VERSION "created by canmatrix"

NS_ :

BS_:

BU_: TCM iBooster HCU CIM SCM Right_Hand_Control Left_Hand_Control GPS VCM IC_2 XM GMRS Radio_CANtool Diagnostic_Tool_Digital_Wrench Information_System_Controller_1 STEERING_CONTROLLER VEHICLE_SECURITY RADIO_Hub ABS Battery_Management_Cntrl_2 Battery_Management_Cntrl_1 Auxiliary_Power_Unit_2 Auxiliary_Power_Unit_1 Electric_Propulsion_Cntrl_Unit_4 Electric_Propulsion_Cntrl_Unit_3 Electric_Propulsion_Cntrl_Unit_2 Electric_Propulsion_Cntrl_Unit_1 ECM IC

BO_ 2348941054 TC1_256: 8 Vector__XXX
 SG_ AutoNeutralReq_7695 : 48|2@1+ (1,0) [0.0|3.0] "" Vector__XXX
 SG_ TransMode8_4249 : 62|2@1+ (1,0) [0.0|3.0] "" Vector__XXX
 SG_ TransMode7_4248 : 60|2@1+ (1,0) [0.0|3.0] "" Vector__XXX
 SG_ TransMode6_4247 : 58|2@1+ (1,0) [0.0|3.0] "" Vector__XXX
 SG_ TransMode5_4246 : 56|2@1+ (1,0) [0.0|3.0] "" Vector__XXX
 SG_ TrnsShftSelectorDMS_2985 : 54|2@1+ (1,0) [0.0|3.0] "" Vector__XXX
 SG_ TransRequestedLaunchGear_4255 : 50|4@1+ (1,0) [0.0|15.0] "" Vector__XXX
 SG_ TransMode4_1855 : 46|2@1+ (1,0) [0.0|3.0] "" Vector__XXX
 SG_ TransMode3_1854 : 44|2@1+ (1,0) [0.0|3.0] "" Vector__XXX
 SG_ TransMode2_1853 : 42|2@1+ (1,0) [0.0|3.0] "" Vector__XXX
 SG_ TransMode1_1852 : 40|2@1+ (1,0) [0.0|3.0] "" Vector__XXX
 SG_ TransLoadReductionInhibitRq_5762 : 38|2@1+ (1,0) [0.0|3.0] "" Vector__XXX
 SG_ DisengDiffLockRqCentralRear_691 : 36|2@1+ (1,0) [0.0|3.0] "" Vector__XXX
 SG_ DisengDiffLockRqCentralFront_690 : 34|2@1+ (1,0) [0.0|3.0] "" Vector__XXX
 SG_ DisengageDiffLockRqCentral_689 : 32|2@1+ (1,0) [0.0|3.0] "" Vector__XXX
 SG_ DisengageDiffLockRqRearAxle2_688 : 30|2@1+ (1,0) [0.0|3.0] "" Vector__XXX
 SG_ DisengageDiffLockRqRearAxle1_687 : 28|2@1+ (1,0) [0.0|3.0] "" Vector__XXX
 SG_ DisengDiffLockRqFrontAxle2_686 : 26|2@1+ (1,0) [0.0|3.0] "" Vector__XXX
 SG_ DisengDiffLockRqFrontAxle1_685 : 24|2@1+ (1,0) [0.0|3.0] "" Vector__XXX
 SG_ TransRequestedGear_525 : 16|8@1+ (1,-125) [-64.0|64.0] "" Vector__XXX
 SG_ RequestedPercentClutchSlip_684 : 8|8@1+ (0.4,0) [0.0|100.0] "%" Vector__XXX
 SG_ TransRevGearShiftInhibitRq_4242 : 6|2@1+ (1,0) [0.0|3.0] "" Vector__XXX
 SG_ DisengageDrivelineRq_683 : 4|2@1+ (1,0) [0.0|3.0] "" Vector__XXX
 SG_ TrnsTrqeConvLockupDisableRq_682 : 2|2@1+ (1,0) [0.0|3.0] "" Vector__XXX
 SG_ TransGearShiftInhibitRq_681 : 0|2@1+ (1,0) [0.0|3.0] "" Vector__XXX

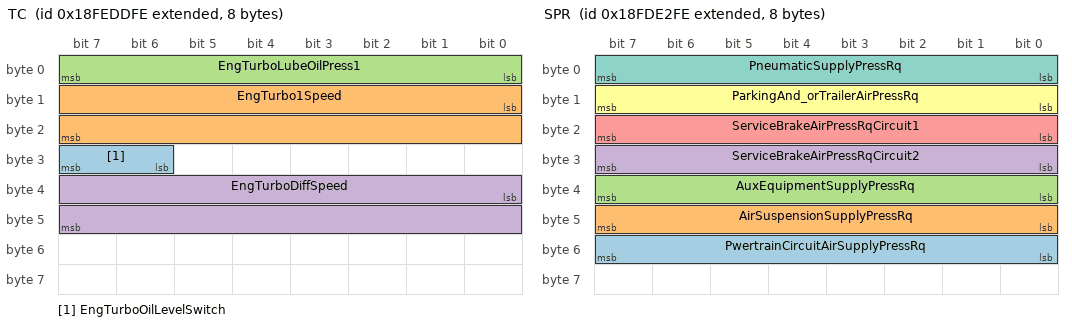
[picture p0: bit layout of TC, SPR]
BO_ 2566839806 TC: 8 Vector__XXX
 SG_ EngTurboOilLevelSwitch : 30|2@1+ (1,0) [0.0|3.0] "" Vector__XXX
 SG_ EngTurbo1Speed : 8|16@1+ (4,0) [0.0|257020.0] "rpm" Vector__XXX
 SG_ EngTurboLubeOilPress1 : 0|8@1+ (4,0) [0.0|1000.0] "kPa" Vector__XXX
 SG_ EngTurboDiffSpeed : 32|16@1+ (4,0) [0.0|257020.0] "rpm" Vector__XXX

BO_ 2633911806 TAVG: 8 Vector__XXX
 SG_ EngTotalAverageFuelEconomy : 16|16@1+ (0.00195312,0) [0.0|125.498046875] "km/L" Vector__XXX
 SG_ EngTotalAverageFuelRate : 0|16@1+ (0.05,0) [0.0|3212.75] "L/h" Vector__XXX

BO_ 2566775550 SPR: 8 Vector__XXX
 SG_ PwertrainCircuitAirSupplyPressRq : 48|8@1+ (8,0) [0.0|2000.0] "kPa" Vector__XXX
 SG_ AirSuspensionSupplyPressRq : 40|8@1+ (8,0) [0.0|2000.0] "kPa" Vector__XXX
 SG_ AuxEquipmentSupplyPressRq : 32|8@1+ (8,0) [0.0|2000.0] "kPa" Vector__XXX
 SG_ ServiceBrakeAirPressRqCircuit2 : 24|8@1+ (8,0) [0.0|2000.0] "kPa" Vector__XXX
 SG_ ServiceBrakeAirPressRqCircuit1 : 16|8@1+ (8,0) [0.0|2000.0] "kPa" Vector__XXX
 SG_ ParkingAnd_orTrailerAirPressRq : 8|8@1+ (8,0) [0.0|2000.0] "kPa" Vector__XXX
 SG_ PneumaticSupplyPressRq : 0|8@1+ (8,0) [0.0|2000.0] "kPa" Vector__XXX

BO_ 2566819838 SP2: 8 Vector__XXX
 SG_ EngExtlShutdownAirSupplyPress : 0|16@1+ (0.5,0) [0.0|32127.5] "kPa" Vector__XXX

BO_ 2566839038 SOFT: 8 Vector__XXX
 SG_ NmbrOfSftwreIdentificationFields : 0|8@1+ (1,0) [0.0|125.0] "steps" Vector__XXX
 SG_ SoftwareIdentification : 8|8@1+ (1,0) [0.0|255.0] "" Vector__XXX

BO_ 2566841598 SHUTDN: 8 Vector__XXX
 SG_ ClntLvlEngPrtctionShutdownStatus : 60|2@1+ (1,0) [0.0|3.0] "" Vector__XXX
 SG_ PTOShutdownHasShutdownEng : 58|2@1+ (1,0) [0.0|3.0] "" Vector__XXX
 SG_ EngAirShutoffStatus : 56|2@1+ (1,0) [0.0|3.0] "" Vector__XXX
 SG_ EngOverspeedTest : 54|2@1+ (1,0) [0.0|3.0] "" Vector__XXX
 SG_ EngAirShutoffCmdStatus : 52|2@1+ (1,0) [0.0|3.0] "" Vector__XXX
 SG_ EngAlarmOutputCmdStatus : 50|2@1+ (1,0) [0.0|3.0] "" Vector__XXX
 SG_ EngAlarmAcknowledge : 48|2@1+ (1,0) [0.0|3.0] "" Vector__XXX
 SG_ EngProtectionSystemConfig : 46|2@1+ (1,0) [0.0|3.0] "" Vector__XXX
 SG_ EngProtectionSystemTimerState : 38|2@1+ (1,0) [0.0|3.0] "" Vector__XXX
 SG_ EngProtectionSystemTimerOverride : 36|2@1+ (1,0) [0.0|3.0] "" Vector__XXX
 SG_ EngPrtctnSystmApprachingShutdown : 34|2@1+ (1,0) [0.0|3.0] "" Vector__XXX
 SG_ EngPrtectionSystemHasShutdownEng : 32|2@1+ (1,0) [0.0|3.0] "" Vector__XXX
 SG_ EngWaitToStartLamp : 24|2@1+ (1,0) [0.0|3.0] "" Vector__XXX
 SG_ RefrigerantHighPressSwitch : 20|2@1+ (1,0) [0.0|3.0] "" Vector__XXX
 SG_ RefrigerantLowPressSwitch : 18|2@1+ (1,0) [0.0|3.0] "" Vector__XXX
 SG_ A_CHighPressFanSwitch : 16|2@1+ (1,0) [0.0|3.0] "" Vector__XXX
 SG_ EngIdleShutdownTimerFunction : 14|2@1+ (1,0) [0.0|3.0] "" Vector__XXX
 SG_ EngIdleShutdownTimerState : 6|2@1+ (1,0) [0.0|3.0] "" Vector__XXX
 SG_ EngIdleShutdownTimerOverride : 4|2@1+ (1,0) [0.0|3.0] "" Vector__XXX
 SG_ EngIdleShutdownDriverAlertMode : 2|2@1+ (1,0) [0.0|3.0] "" Vector__XXX
 SG_ EngIdleShutdownHasShutdownEng : 0|2@1+ (1,0) [0.0|3.0] "" Vector__XXX

BO_ 2566786302 WSMEM: 8 Vector__XXX
 SG_ VehicleSystem5 m5  : 49|7@1+ (1,0) [0.0|127.0] "" Vector__XXX
 SG_ VehicleSystem4 m4  : 49|7@1+ (1,0) [0.0|127.0] "" Vector__XXX
 SG_ VehicleSystem3 m3  : 49|7@1+ (1,0) [0.0|127.0] "" Vector__XXX
 SG_ VehicleSystem2 m2  : 49|7@1+ (1,0) [0.0|127.0] "" Vector__XXX
 SG_ VehicleSystem1 m1  : 49|7@1+ (1,0) [0.0|127.0] "" Vector__XXX
 SG_ ArbitraryAddressCapable : 63|1@1+ (1,0) [0.0|1.0] "" Vector__XXX
 SG_ IndustryGroup M  : 60|3@1+ (1,0) [0.0|7.0] "" Vector__XXX
 SG_ VehicleSystemInstance : 56|4@1+ (1,0) [0.0|15.0] "" Vector__XXX
 SG_ VehicleSystem m0  : 49|7@1+ (1,0) [0.0|127.0] "" Vector__XXX
 SG_ ECUInstance : 32|3@1+ (1,0) [0.0|7.0] "" Vector__XXX
 SG_ FunctionInstance : 35|5@1+ (1,0) [0.0|31.0] "" Vector__XXX
 SG_ Function : 40|8@1+ (1,0) [0.0|255.0] "" Vector__XXX
 SG_ ManufacturerCode : 21|11@1+ (1,0) [0.0|2047.0] "" Vector__XXX
 SG_ IdentityNumber : 0|21@1+ (1,0) [0.0|2097152.0] "" Vector__XXX

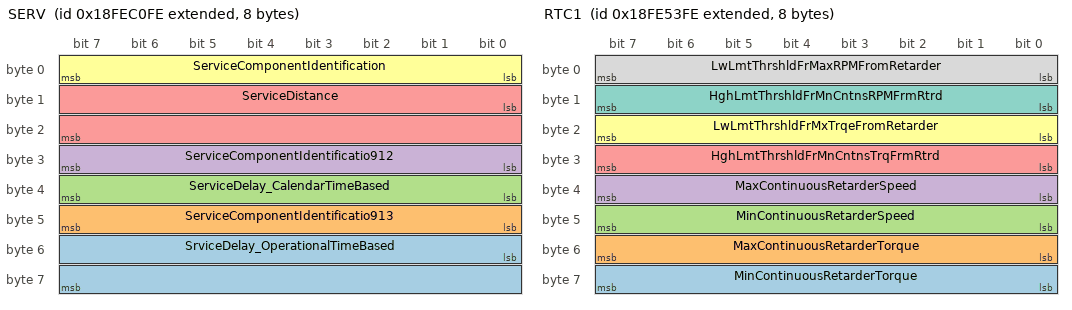
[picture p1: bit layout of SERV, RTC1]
BO_ 2566832382 SERV: 8 Vector__XXX
 SG_ SrviceDelay_OperationalTimeBased : 48|16@1+ (1,-32127) [-32127.0|32128.0] "h" Vector__XXX
 SG_ ServiceComponentIdentificatio913 : 40|8@1+ (1,0) [0.0|250.0] "ID" Vector__XXX
 SG_ ServiceDelay_CalendarTimeBased : 32|8@1+ (1,-125) [-125.0|125.0] "weeks" Vector__XXX
 SG_ ServiceComponentIdentificatio912 : 24|8@1+ (1,0) [0.0|250.0] "ID" Vector__XXX
 SG_ ServiceDistance : 8|16@1+ (5,-160635) [-160635.0|160640.0] "km" Vector__XXX
 SG_ ServiceComponentIdentification : 0|8@1+ (1,0) [0.0|250.0] "ID" Vector__XXX

BO_ 2633928446 S2: 8 Vector__XXX
 SG_ TimeSinceLastService : 8|16@1+ (1,-32127) [-32127.0|32128.0] "h" Vector__XXX
 SG_ ServiceComponentIdentification : 0|8@1+ (1,0) [0.0|250.0] "ID" Vector__XXX

BO_ 2566804478 RTC1: 8 Vector__XXX
 SG_ MinContinuousRetarderTorque : 56|8@1+ (1,-125) [-125.0|125.0] "%" Vector__XXX
 SG_ MaxContinuousRetarderTorque : 48|8@1+ (1,-125) [-125.0|125.0] "%" Vector__XXX
 SG_ MinContinuousRetarderSpeed : 40|8@1+ (32,0) [0.0|8000.0] "rpm" Vector__XXX
 SG_ MaxContinuousRetarderSpeed : 32|8@1+ (32,0) [0.0|8000.0] "rpm" Vector__XXX
 SG_ HghLmtThrshldFrMnCntnsTrqFrmRtrd : 24|8@1+ (1,-125) [-125.0|125.0] "%" Vector__XXX
 SG_ LwLmtThrshldFrMxTrqeFromRetarder : 16|8@1+ (1,-125) [-125.0|125.0] "%" Vector__XXX
 SG_ HghLmtThrshldFrMnCntnsRPMFrmRtrd : 8|8@1+ (32,0) [0.0|8000.0] "rpm" Vector__XXX
 SG_ LwLmtThrshldFrMaxRPMFromRetarder : 0|8@1+ (32,0) [0.0|8000.0] "rpm" Vector__XXX

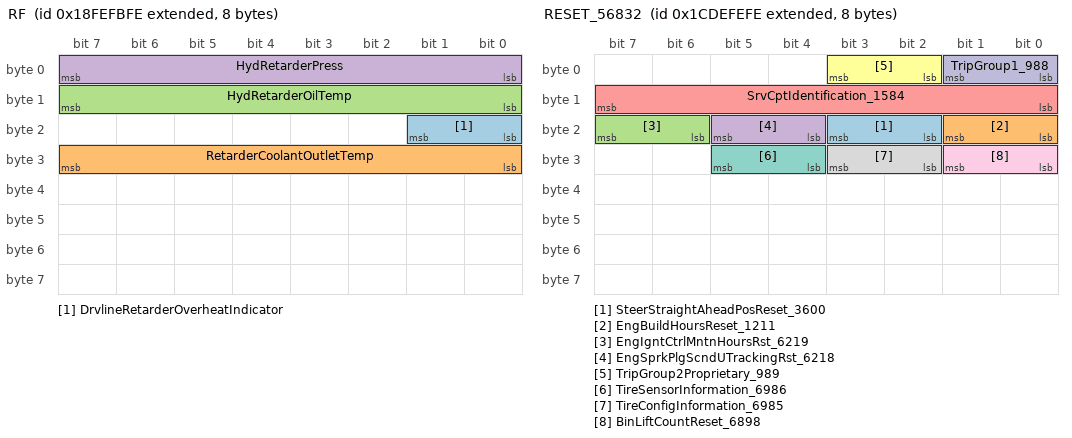
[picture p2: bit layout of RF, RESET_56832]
BO_ 2566847486 RF: 8 Vector__XXX
 SG_ DrvlineRetarderOverheatIndicator : 16|2@1+ (1,0) [0.0|3.0] "" Vector__XXX
 SG_ RetarderCoolantOutletTemp : 24|8@1+ (1,-40) [-40.0|210.0] "°C" Vector__XXX
 SG_ HydRetarderOilTemp : 8|8@1+ (1,-40) [-40.0|210.0] "°C" Vector__XXX
 SG_ HydRetarderPress : 0|8@1+ (16,0) [0.0|4000.0] "kPa" Vector__XXX

BO_ 2631859966 RESET_56832: 8 Vector__XXX
 SG_ SteerStraightAheadPosReset_3600 : 18|2@1+ (1,0) [0.0|3.0] "" Vector__XXX
 SG_ EngBuildHoursReset_1211 : 16|2@1+ (1,0) [0.0|3.0] "" Vector__XXX
 SG_ EngIgntCtrlMntnHoursRst_6219 : 22|2@1+ (1,0) [0.0|3.0] "" Vector__XXX
 SG_ EngSprkPlgScndUTrackingRst_6218 : 20|2@1+ (1,0) [0.0|3.0] "" Vector__XXX
 SG_ SrvCptIdentification_1584 : 8|8@1+ (1,0) [0.0|250.0] "ID" Vector__XXX
 SG_ TripGroup2Proprietary_989 : 2|2@1+ (1,0) [0.0|3.0] "" Vector__XXX
 SG_ TireSensorInformation_6986 : 28|2@1+ (1,0) [0.0|3.0] "" Vector__XXX
 SG_ TireConfigInformation_6985 : 26|2@1+ (1,0) [0.0|3.0] "" Vector__XXX
 SG_ BinLiftCountReset_6898 : 24|2@1+ (1,0) [0.0|3.0] "" Vector__XXX
 SG_ TripGroup1_988 : 0|2@1+ (1,0) [0.0|3.0] "" Vector__XXX

BO_ 2566840830 RC: 19 Vector__XXX
 SG_ PercentTorqueAtPeakTorquePoint5 : 144|8@1+ (1,-125) [-125.0|0.0] "%" Vector__XXX
 SG_ ReferenceRetarderTorque : 128|16@1+ (1,0) [0.0|64255.0] "Nm" Vector__XXX
 SG_ RetarderSpeedAtPeakTorquePoint5 : 112|16@1+ (0.125,0) [0.0|8031.875] "rpm" Vector__XXX
 SG_ PercentTorqueAtPoint4 : 104|8@1+ (1,-125) [-125.0|0.0] "%" Vector__XXX
 SG_ RetarderSpeedAtPoint4 : 88|16@1+ (0.125,0) [0.0|8031.875] "rpm" Vector__XXX
 SG_ PercentTorqueAtPoint3 : 80|8@1+ (1,-125) [-125.0|0.0] "%" Vector__XXX
 SG_ RetarderSpeedAtPoint3 : 64|16@1+ (0.125,0) [0.0|8031.875] "rpm" Vector__XXX
 SG_ PercentTorqueAtMaxSpeedPoint2 : 56|8@1+ (1,-125) [-125.0|0.0] "%" Vector__XXX
 SG_ MaxRetarderSpeedPoint2 : 40|16@1+ (0.125,0) [0.0|8031.875] "rpm" Vector__XXX
 SG_ PercentTorqueAtIdlePoint1 : 32|8@1+ (1,-125) [-125.0|0.0] "%" Vector__XXX
 SG_ RetarderSpeedAtIdlePoint1 : 16|16@1+ (0.125,0) [0.0|8031.875] "rpm" Vector__XXX
 SG_ RetarderCtrlMethod : 8|8@1+ (1,0) [0.0|250.0] "steps" Vector__XXX
 SG_ RetarderLocation : 4|4@1+ (1,0) [0.0|15.0] "" Vector__XXX
 SG_ RetarderType : 0|4@1+ (1,0) [0.0|15.0] "" Vector__XXX

BO_ 2633930238 RBI: 8 Vector__XXX
 SG_ EngOperationTimeSinceRebuild : 0|32@1+ (1,0) [0.0|4211081215.0] "s" Vector__XXX

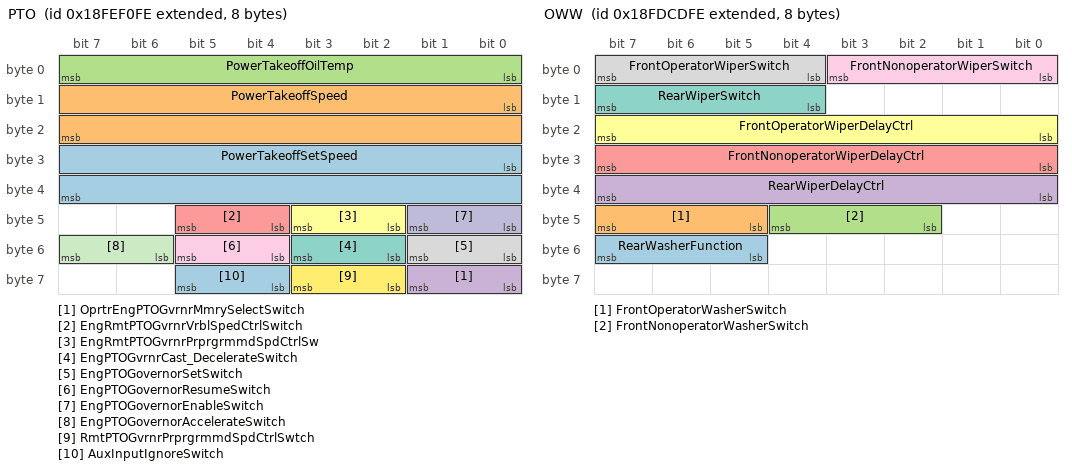
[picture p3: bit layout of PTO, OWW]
BO_ 2566844670 PTO: 8 Vector__XXX
 SG_ PowerTakeoffSetSpeed : 24|16@1+ (0.125,0) [0.0|8031.875] "rpm" Vector__XXX
 SG_ PowerTakeoffSpeed : 8|16@1+ (0.125,0) [0.0|8031.875] "rpm" Vector__XXX
 SG_ PowerTakeoffOilTemp : 0|8@1+ (1,-40) [-40.0|210.0] "°C" Vector__XXX
 SG_ OprtrEngPTOGvrnrMmrySelectSwitch : 56|2@1+ (1,0) [0.0|3.0] "" Vector__XXX
 SG_ EngRmtPTOGvrnrVrblSpedCtrlSwitch : 44|2@1+ (1,0) [0.0|3.0] "" Vector__XXX
 SG_ EngRmtPTOGvrnrPrprgrmmdSpdCtrlSw : 42|2@1+ (1,0) [0.0|3.0] "" Vector__XXX
 SG_ EngPTOGvrnrCast_DecelerateSwitch : 50|2@1+ (1,0) [0.0|3.0] "" Vector__XXX
 SG_ EngPTOGovernorSetSwitch : 48|2@1+ (1,0) [0.0|3.0] "" Vector__XXX
 SG_ EngPTOGovernorResumeSwitch : 52|2@1+ (1,0) [0.0|3.0] "" Vector__XXX
 SG_ EngPTOGovernorEnableSwitch : 40|2@1+ (1,0) [0.0|3.0] "" Vector__XXX
 SG_ EngPTOGovernorAccelerateSwitch : 54|2@1+ (1,0) [0.0|3.0] "" Vector__XXX
 SG_ RmtPTOGvrnrPrprgrmmdSpdCtrlSwtch : 58|2@1+ (1,0) [0.0|3.0] "" Vector__XXX
 SG_ AuxInputIgnoreSwitch : 60|2@1+ (1,0) [0.0|3.0] "" Vector__XXX

BO_ 2566770174 OWW: 8 Vector__XXX
 SG_ RearWasherFunction : 53|3@1+ (1,0) [0.0|7.0] "" Vector__XXX
 SG_ FrontOperatorWasherSwitch : 45|3@1+ (1,0) [0.0|7.0] "" Vector__XXX
 SG_ FrontNonoperatorWasherSwitch : 42|3@1+ (1,0) [0.0|7.0] "" Vector__XXX
 SG_ RearWiperDelayCtrl : 32|8@1+ (0.4,0) [0.0|100.0] "%" Vector__XXX
 SG_ FrontNonoperatorWiperDelayCtrl : 24|8@1+ (0.4,0) [0.0|100.0] "%" Vector__XXX
 SG_ FrontOperatorWiperDelayCtrl : 16|8@1+ (0.4,0) [0.0|100.0] "%" Vector__XXX
 SG_ RearWiperSwitch : 12|4@1+ (1,0) [0.0|15.0] "" Vector__XXX
 SG_ FrontOperatorWiperSwitch : 4|4@1+ (1,0) [0.0|15.0] "" Vector__XXX
 SG_ FrontNonoperatorWiperSwitch : 0|4@1+ (1,0) [0.0|15.0] "" Vector__XXX

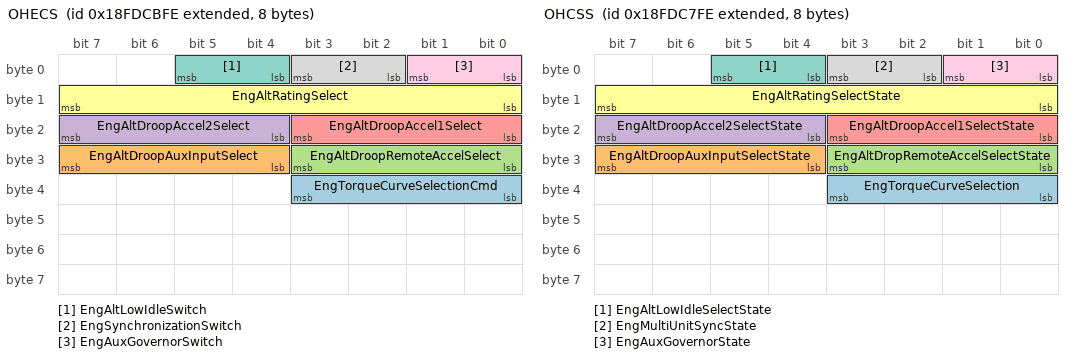
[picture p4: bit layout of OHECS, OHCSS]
BO_ 2566769662 OHECS: 8 Vector__XXX
 SG_ EngTorqueCurveSelectionCmd : 32|4@1+ (1,0) [0.0|15.0] "" Vector__XXX
 SG_ EngAltDroopAuxInputSelect : 28|4@1+ (1,0) [0.0|15.0] "" Vector__XXX
 SG_ EngAltDroopRemoteAccelSelect : 24|4@1+ (1,0) [0.0|15.0] "" Vector__XXX
 SG_ EngAltDroopAccel2Select : 20|4@1+ (1,0) [0.0|15.0] "" Vector__XXX
 SG_ EngAltDroopAccel1Select : 16|4@1+ (1,0) [0.0|15.0] "" Vector__XXX
 SG_ EngAltRatingSelect : 8|8@1+ (1,0) [0.0|255.0] "" Vector__XXX
 SG_ EngAltLowIdleSwitch : 4|2@1+ (1,0) [0.0|3.0] "" Vector__XXX
 SG_ EngSynchronizationSwitch : 2|2@1+ (1,0) [0.0|3.0] "" Vector__XXX
 SG_ EngAuxGovernorSwitch : 0|2@1+ (1,0) [0.0|3.0] "" Vector__XXX

BO_ 2566768638 OHCSS: 8 Vector__XXX
 SG_ EngTorqueCurveSelection : 32|4@1+ (1,0) [0.0|15.0] "" Vector__XXX
 SG_ EngAltDroopAuxInputSelectState : 28|4@1+ (1,0) [0.0|15.0] "" Vector__XXX
 SG_ EngAltDropRemoteAccelSelectState : 24|4@1+ (1,0) [0.0|15.0] "" Vector__XXX
 SG_ EngAltDroopAccel2SelectState : 20|4@1+ (1,0) [0.0|15.0] "" Vector__XXX
 SG_ EngAltDroopAccel1SelectState : 16|4@1+ (1,0) [0.0|15.0] "" Vector__XXX
 SG_ EngAltRatingSelectState : 8|8@1+ (1,0) [0.0|255.0] "" Vector__XXX
 SG_ EngAltLowIdleSelectState : 4|2@1+ (1,0) [0.0|3.0] "" Vector__XXX
 SG_ EngMultiUnitSyncState : 2|2@1+ (1,0) [0.0|3.0] "" Vector__XXX
 SG_ EngAuxGovernorState : 0|2@1+ (1,0) [0.0|3.0] "" Vector__XXX

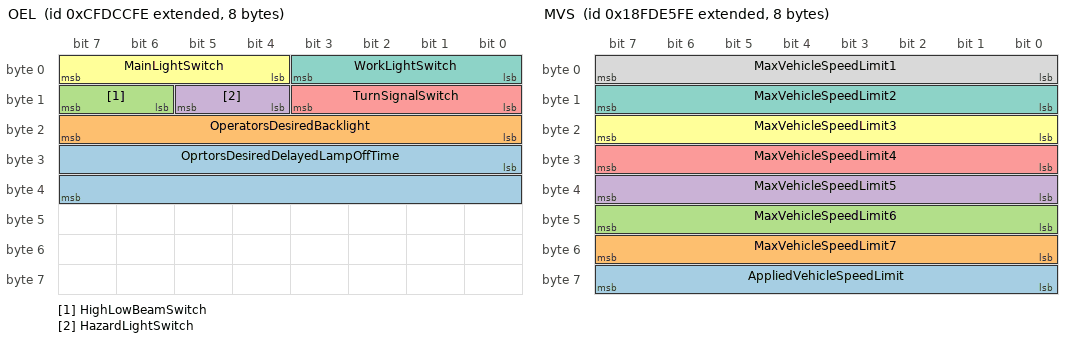
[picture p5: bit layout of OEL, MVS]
BO_ 2365443326 OEL: 8 Vector__XXX
 SG_ OprtorsDesiredDelayedLampOffTime : 24|16@1+ (1,0) [0.0|64255.0] "s" Vector__XXX
 SG_ OperatorsDesiredBacklight : 16|8@1+ (0.4,0) [0.0|100.0] "%" Vector__XXX
 SG_ HighLowBeamSwitch : 14|2@1+ (1,0) [0.0|3.0] "" Vector__XXX
 SG_ HazardLightSwitch : 12|2@1+ (1,0) [0.0|3.0] "" Vector__XXX
 SG_ TurnSignalSwitch : 8|4@1+ (1,0) [0.0|15.0] "" Vector__XXX
 SG_ MainLightSwitch : 4|4@1+ (1,0) [0.0|15.0] "" Vector__XXX
 SG_ WorkLightSwitch : 0|4@1+ (1,0) [0.0|15.0] "" Vector__XXX

BO_ 2566776318 MVS: 8 Vector__XXX
 SG_ AppliedVehicleSpeedLimit : 56|8@1+ (1,0) [0.0|250.0] "km/h" Vector__XXX
 SG_ MaxVehicleSpeedLimit7 : 48|8@1+ (1,0) [0.0|250.0] "km/h" Vector__XXX
 SG_ MaxVehicleSpeedLimit6 : 40|8@1+ (1,0) [0.0|250.0] "km/h" Vector__XXX
 SG_ MaxVehicleSpeedLimit5 : 32|8@1+ (1,0) [0.0|250.0] "km/h" Vector__XXX
 SG_ MaxVehicleSpeedLimit4 : 24|8@1+ (1,0) [0.0|250.0] "km/h" Vector__XXX
 SG_ MaxVehicleSpeedLimit3 : 16|8@1+ (1,0) [0.0|250.0] "km/h" Vector__XXX
 SG_ MaxVehicleSpeedLimit2 : 8|8@1+ (1,0) [0.0|250.0] "km/h" Vector__XXX
 SG_ MaxVehicleSpeedLimit1 : 0|8@1+ (1,0) [0.0|250.0] "km/h" Vector__XXX

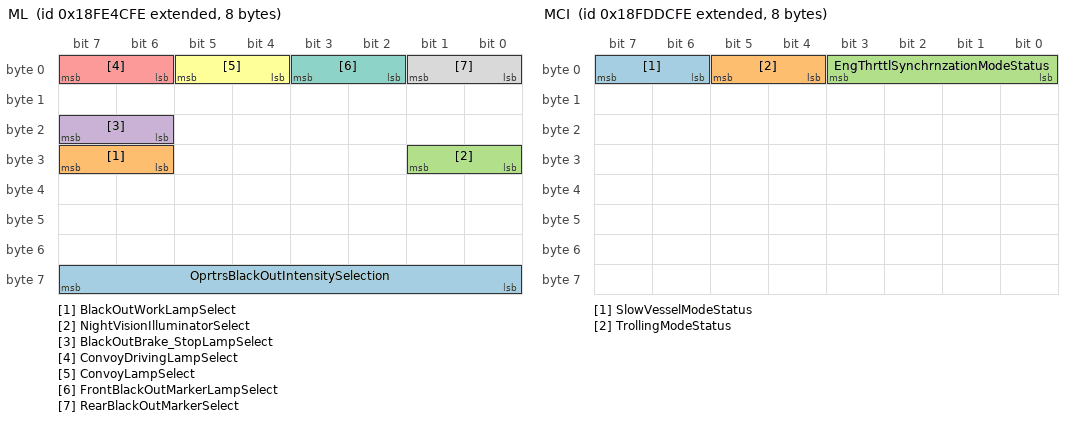
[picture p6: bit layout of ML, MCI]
BO_ 2566802686 ML: 8 Vector__XXX
 SG_ OprtrsBlackOutIntensitySelection : 56|8@1+ (0.4,0) [0.0|100.0] "%" Vector__XXX
 SG_ BlackOutWorkLampSelect : 30|2@1+ (1,0) [0.0|3.0] "" Vector__XXX
 SG_ NightVisionIlluminatorSelect : 24|2@1+ (1,0) [0.0|3.0] "" Vector__XXX
 SG_ BlackOutBrake_StopLampSelect : 22|2@1+ (1,0) [0.0|3.0] "" Vector__XXX
 SG_ ConvoyDrivingLampSelect : 6|2@1+ (1,0) [0.0|3.0] "" Vector__XXX
 SG_ ConvoyLampSelect : 4|2@1+ (1,0) [0.0|3.0] "" Vector__XXX
 SG_ FrontBlackOutMarkerLampSelect : 2|2@1+ (1,0) [0.0|3.0] "" Vector__XXX
 SG_ RearBlackOutMarkerSelect : 0|2@1+ (1,0) [0.0|3.0] "" Vector__XXX

BO_ 2566774014 MCI: 8 Vector__XXX
 SG_ SlowVesselModeStatus : 6|2@1+ (1,0) [0.0|3.0] "" Vector__XXX
 SG_ TrollingModeStatus : 4|2@1+ (1,0) [0.0|3.0] "" Vector__XXX
 SG_ EngThrttlSynchrnzationModeStatus : 0|4@1+ (1,0) [0.0|15.0] "" Vector__XXX

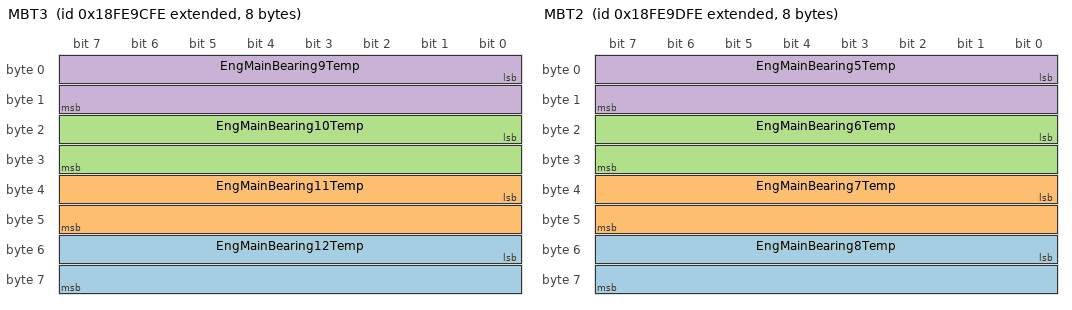
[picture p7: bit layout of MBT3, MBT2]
BO_ 2566823166 MBT3: 8 Vector__XXX
 SG_ EngMainBearing12Temp : 48|16@1+ (0.03125,-273) [-273.0|1734.96875] "°C" Vector__XXX
 SG_ EngMainBearing11Temp : 32|16@1+ (0.03125,-273) [-273.0|1734.96875] "°C" Vector__XXX
 SG_ EngMainBearing10Temp : 16|16@1+ (0.03125,-273) [-273.0|1734.96875] "°C" Vector__XXX
 SG_ EngMainBearing9Temp : 0|16@1+ (0.03125,-273) [-273.0|1734.96875] "°C" Vector__XXX

BO_ 2566823422 MBT2: 8 Vector__XXX
 SG_ EngMainBearing8Temp : 48|16@1+ (0.03125,-273) [-273.0|1734.96875] "°C" Vector__XXX
 SG_ EngMainBearing7Temp : 32|16@1+ (0.03125,-273) [-273.0|1734.96875] "°C" Vector__XXX
 SG_ EngMainBearing6Temp : 16|16@1+ (0.03125,-273) [-273.0|1734.96875] "°C" Vector__XXX
 SG_ EngMainBearing5Temp : 0|16@1+ (0.03125,-273) [-273.0|1734.96875] "°C" Vector__XXX

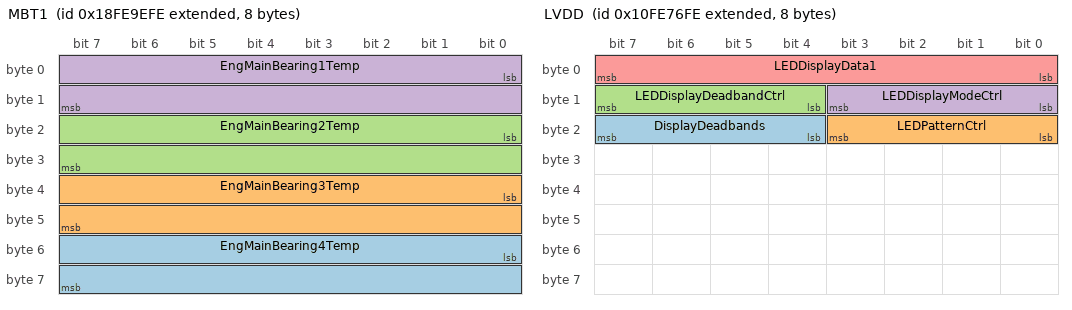
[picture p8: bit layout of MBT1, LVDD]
BO_ 2566823678 MBT1: 8 Vector__XXX
 SG_ EngMainBearing4Temp : 48|16@1+ (0.03125,-273) [-273.0|1734.96875] "°C" Vector__XXX
 SG_ EngMainBearing3Temp : 32|16@1+ (0.03125,-273) [-273.0|1734.96875] "°C" Vector__XXX
 SG_ EngMainBearing2Temp : 16|16@1+ (0.03125,-273) [-273.0|1734.96875] "°C" Vector__XXX
 SG_ EngMainBearing1Temp : 0|16@1+ (0.03125,-273) [-273.0|1734.96875] "°C" Vector__XXX

BO_ 2432595710 LVDD: 8 Vector__XXX
 SG_ DisplayDeadbands : 20|4@1+ (1,0) [0.0|15.0] "" Vector__XXX
 SG_ LEDPatternCtrl : 16|4@1+ (1,0) [0.0|15.0] "" Vector__XXX
 SG_ LEDDisplayDeadbandCtrl : 12|4@1+ (1,0) [0.0|15.0] "" Vector__XXX
 SG_ LEDDisplayModeCtrl : 8|4@1+ (1,0) [0.0|15.0] "" Vector__XXX
 SG_ LEDDisplayData1 : 0|8@1+ (1,0) [0.0|255.0] "" Vector__XXX

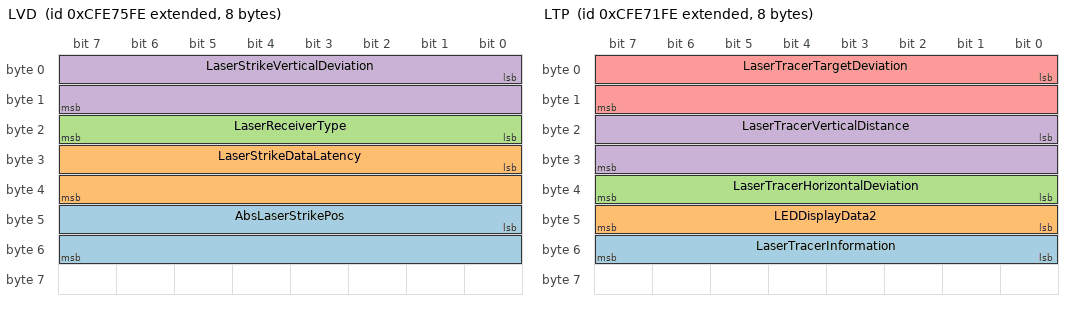
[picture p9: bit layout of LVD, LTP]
BO_ 2365486590 LVD: 8 Vector__XXX
 SG_ AbsLaserStrikePos : 40|16@1+ (0.1,0) [0.0|6425.5] "mm" Vector__XXX
 SG_ LaserStrikeDataLatency : 24|16@1+ (5.12e-05,0) [0.0|3.289856] "s" Vector__XXX
 SG_ LaserReceiverType : 16|8@1+ (1,0) [0.0|250.0] "" Vector__XXX
 SG_ LaserStrikeVerticalDeviation : 0|16@1+ (0.1,-3200) [-3200.0|3225.5] "mm" Vector__XXX

BO_ 2365485566 LTP: 8 Vector__XXX
 SG_ LaserTracerInformation : 48|8@1+ (1,0) [0.0|255.0] "" Vector__XXX
 SG_ LEDDisplayData2 : 40|8@1+ (1,0) [0.0|255.0] "" Vector__XXX
 SG_ LaserTracerHorizontalDeviation : 32|8@1+ (1,0) [0.0|200.0] "%" Vector__XXX
 SG_ LaserTracerVerticalDistance : 16|16@1+ (0.1,0) [0.0|6400.0] "mm" Vector__XXX
 SG_ LaserTracerTargetDeviation : 0|16@1+ (0.1,-3200) [-3200.0|3225.5] "mm" Vector__XXX

BO_ 2633939454 LTFI: 22 Vector__XXX
 SG_ TripDriveFuelEconomy : 160|16@1+ (0.00195312,0) [0.0|125.498046875] "km/L" Vector__XXX
 SG_ TripCruiseFuelUsed : 128|32@1+ (0.5,0) [0.0|2105540607.5] "L" Vector__XXX
 SG_ TripVehicleIdleFuelUsed : 96|32@1+ (0.5,0) [0.0|2105540607.5] "L" Vector__XXX
 SG_ TripPTOGovernorNonmovingFuelUsed : 64|32@1+ (0.5,0) [0.0|2105540607.5] "L" Vector__XXX
 SG_ TripPTOGovernorMovingFuelUsed : 32|32@1+ (0.5,0) [0.0|2105540607.5] "L" Vector__XXX
 SG_ TripDriveFuelUsed : 0|32@1+ (0.5,0) [0.0|2105540607.5] "L" Vector__XXX

BO_ 2365486334 LSP: 8 Vector__XXX
 SG_ BldeHeightSetPointHighResolution : 16|32@1+ (1e-07,-209.715) [-209.7152|209.7152] "m" Vector__XXX
 SG_ ModifyLevelingSystemSetPoint : 0|16@1+ (0.1,-3200) [-3200.0|3225.5] "mm" Vector__XXX

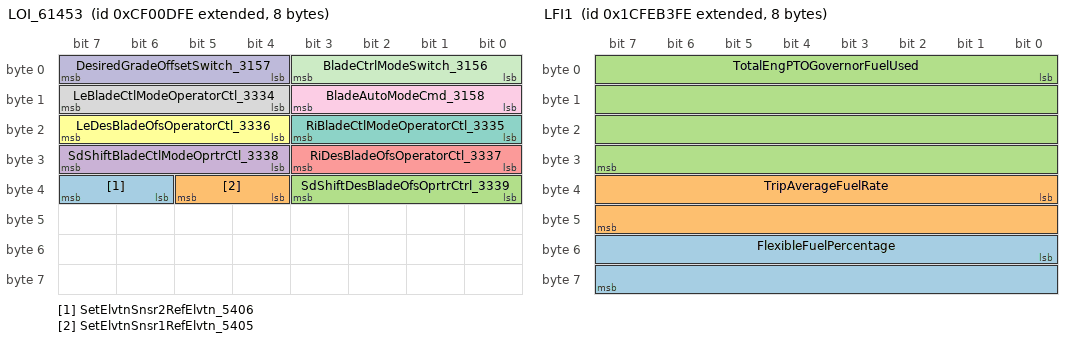
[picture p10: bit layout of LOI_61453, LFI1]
BO_ 2364542462 LOI_61453: 8 Vector__XXX
 SG_ SetElvtnSnsr2RefElvtn_5406 : 38|2@1+ (1,0) [0.0|3.0] "" Vector__XXX
 SG_ SetElvtnSnsr1RefElvtn_5405 : 36|2@1+ (1,0) [0.0|3.0] "" Vector__XXX
 SG_ SdShiftDesBladeOfsOprtrCtrl_3339 : 32|4@1+ (1,0) [0.0|15.0] "" Vector__XXX
 SG_ SdShiftBladeCtlModeOprtrCtl_3338 : 28|4@1+ (1,0) [0.0|15.0] "" Vector__XXX
 SG_ RiDesBladeOfsOperatorCtl_3337 : 24|4@1+ (1,0) [0.0|15.0] "" Vector__XXX
 SG_ LeDesBladeOfsOperatorCtl_3336 : 20|4@1+ (1,0) [0.0|15.0] "" Vector__XXX
 SG_ RiBladeCtlModeOperatorCtl_3335 : 16|4@1+ (1,0) [0.0|15.0] "" Vector__XXX
 SG_ LeBladeCtlModeOperatorCtl_3334 : 12|4@1+ (1,0) [0.0|15.0] "" Vector__XXX
 SG_ BladeAutoModeCmd_3158 : 8|4@1+ (1,0) [0.0|15.0] "" Vector__XXX
 SG_ DesiredGradeOffsetSwitch_3157 : 4|4@1+ (1,0) [0.0|15.0] "" Vector__XXX
 SG_ BladeCtrlModeSwitch_3156 : 0|4@1+ (1,0) [0.0|15.0] "" Vector__XXX

BO_ 2365486078 LMP: 8 Vector__XXX
 SG_ MastPos : 0|16@1+ (0.1,-3200) [-3200.0|3225.5] "mm" Vector__XXX

BO_ 2633937918 LFI1: 8 Vector__XXX
 SG_ FlexibleFuelPercentage : 48|16@1+ (0.0025,0) [0.0|100.0] "%" Vector__XXX
 SG_ TripAverageFuelRate : 32|16@1+ (0.05,0) [0.0|3212.75] "L/h" Vector__XXX
 SG_ TotalEngPTOGovernorFuelUsed : 0|32@1+ (0.5,0) [0.0|2105540607.5] "L" Vector__XXX

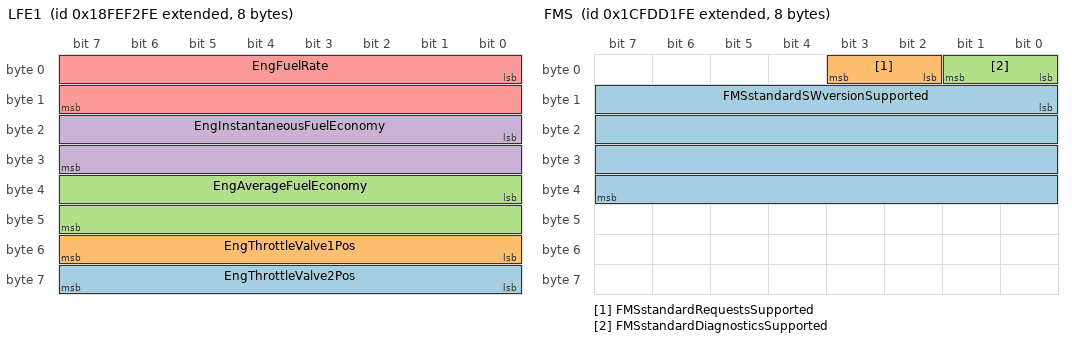
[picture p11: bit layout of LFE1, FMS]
BO_ 2566845182 LFE1: 8 Vector__XXX
 SG_ EngThrottleValve2Pos : 56|8@1+ (0.4,0) [0.0|100.0] "%" Vector__XXX
 SG_ EngThrottleValve1Pos : 48|8@1+ (0.4,0) [0.0|100.0] "%" Vector__XXX
 SG_ EngAverageFuelEconomy : 32|16@1+ (0.00195312,0) [0.0|125.498046875] "km/L" Vector__XXX
 SG_ EngInstantaneousFuelEconomy : 16|16@1+ (0.00195312,0) [0.0|125.498046875] "km/L" Vector__XXX
 SG_ EngFuelRate : 0|16@1+ (0.05,0) [0.0|3212.75] "L/h" Vector__XXX

BO_ 2566842878 LFC1: 8 Vector__XXX
 SG_ EngTotalFuelUsed : 32|32@1+ (0.5,0) [0.0|2105540607.5] "L" Vector__XXX
 SG_ EngTripFuel : 0|32@1+ (0.5,0) [0.0|2105540607.5] "L" Vector__XXX

BO_ 2633883646 FWD: 8 Vector__XXX
 SG_ FrontWheelDriveActuatorStatus : 0|2@1+ (1,0) [0.0|3.0] "" Vector__XXX

BO_ 2633880062 FMS: 8 Vector__XXX
 SG_ FMSstandardSWversionSupported : 8|32@1+ (1,0) [0.0|255.0] "" Vector__XXX
 SG_ FMSstandardRequestsSupported : 2|2@1+ (1,0) [0.0|3.0] "" Vector__XXX
 SG_ FMSstandardDiagnosticsSupported : 0|2@1+ (1,0) [0.0|3.0] "" Vector__XXX

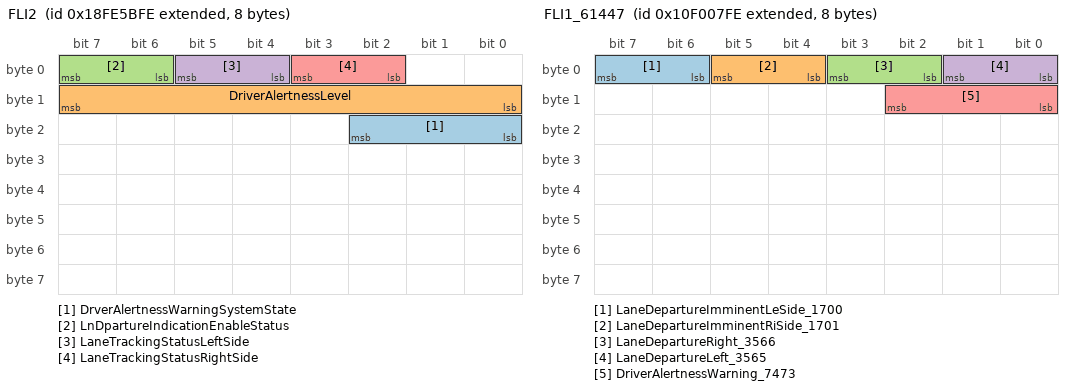
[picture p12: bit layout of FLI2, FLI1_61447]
BO_ 2566806526 FLI2: 8 Vector__XXX
 SG_ DrverAlertnessWarningSystemState : 16|3@1+ (1,0) [0.0|7.0] "" Vector__XXX
 SG_ DriverAlertnessLevel : 8|8@1+ (0.4,0) [0.0|100.0] "%" Vector__XXX
 SG_ LnDpartureIndicationEnableStatus : 6|2@1+ (1,0) [0.0|3.0] "" Vector__XXX
 SG_ LaneTrackingStatusLeftSide : 4|2@1+ (1,0) [0.0|3.0] "" Vector__XXX
 SG_ LaneTrackingStatusRightSide : 2|2@1+ (1,0) [0.0|3.0] "" Vector__XXX

BO_ 2431649790 FLI1_61447: 8 Vector__XXX
 SG_ LaneDepartureImminentLeSide_1700 : 6|2@1+ (1,0) [0.0|3.0] "" Vector__XXX
 SG_ LaneDepartureImminentRiSide_1701 : 4|2@1+ (1,0) [0.0|3.0] "" Vector__XXX
 SG_ LaneDepartureRight_3566 : 2|2@1+ (1,0) [0.0|3.0] "" Vector__XXX
 SG_ LaneDepartureLeft_3565 : 0|2@1+ (1,0) [0.0|3.0] "" Vector__XXX
 SG_ DriverAlertnessWarning_7473 : 8|3@1+ (1,0) [0.0|7.0] "" Vector__XXX

BO_ 2633929214 FL: 8 Vector__XXX
 SG_ EngFuelLeakage2 : 2|2@1+ (1,0) [0.0|3.0] "" Vector__XXX
 SG_ EngFuelLeakage1 : 0|2@1+ (1,0) [0.0|3.0] "" Vector__XXX

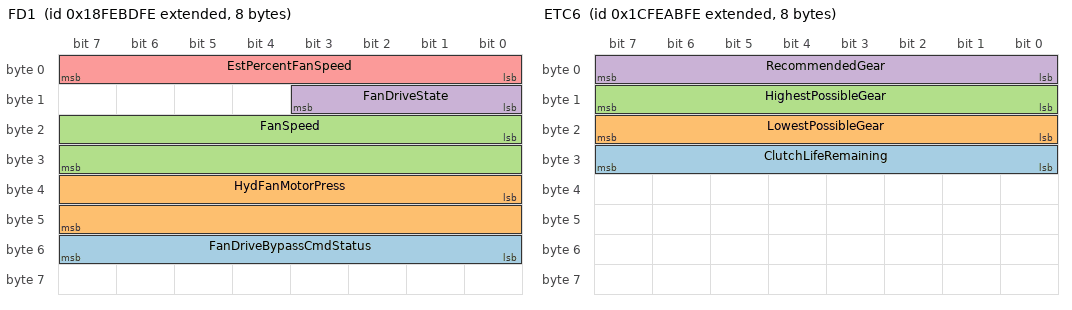
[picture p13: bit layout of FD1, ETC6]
BO_ 2566831614 FD1: 8 Vector__XXX
 SG_ FanDriveBypassCmdStatus : 48|8@1+ (0.4,0) [0.0|100.0] "%" Vector__XXX
 SG_ HydFanMotorPress : 32|16@1+ (0.5,0) [0.0|32127.5] "kPa" Vector__XXX
 SG_ FanSpeed : 16|16@1+ (0.125,0) [0.0|8031.875] "rpm" Vector__XXX
 SG_ FanDriveState : 8|4@1+ (1,0) [0.0|15.0] "" Vector__XXX
 SG_ EstPercentFanSpeed : 0|8@1+ (0.4,0) [0.0|100.0] "%" Vector__XXX

BO_ 2566820094 ETH: 8 Vector__XXX
 SG_ EngTorqueLimit6AxleInput : 248|16@1+ (2,0) [0.0|128510.0] "Nm" Vector__XXX
 SG_ EngTorqueLimit5Switch : 232|16@1+ (1,0) [0.0|64255.0] "Nm" Vector__XXX
 SG_ EngTorqueLimit4Trans : 216|16@1+ (1,0) [0.0|64255.0] "Nm" Vector__XXX
 SG_ EngTorqueLimit3Trans : 200|16@1+ (1,0) [0.0|64255.0] "Nm" Vector__XXX
 SG_ TransGearRatio3 : 184|16@1+ (0.01,0) [0.0|642.55] "" Vector__XXX
 SG_ EngTorqueLimit2Trans : 168|16@1+ (1,0) [0.0|64255.0] "Nm" Vector__XXX
 SG_ TransGearRatio2 : 152|16@1+ (0.01,0) [0.0|642.55] "" Vector__XXX
 SG_ EngTorqueLimit1Trans : 136|16@1+ (1,0) [0.0|64255.0] "Nm" Vector__XXX
 SG_ TransGearRatio1 : 120|16@1+ (0.01,0) [0.0|642.55] "" Vector__XXX
 SG_ EngTorqueLimitFeature : 114|3@1+ (1,0) [0.0|7.0] "" Vector__XXX
 SG_ TorqueLimitingFeatureStatus : 112|2@1+ (1,0) [0.0|3.0] "" Vector__XXX
 SG_ CalibRecordDurationTime : 80|32@1+ (0.05,0) [0.0|210554060.75] "h" Vector__XXX
 SG_ CalibRecordStartYear : 72|8@1+ (1,1985) [1985.0|2235.0] "years" Vector__XXX
 SG_ CalibRecordStartDay : 64|8@1+ (0.25,0) [0.25|31.75] "days" Vector__XXX
 SG_ CalibRecordStartMonth : 56|8@1+ (1,0) [1.0|12.0] "months" Vector__XXX
 SG_ EngPeakTorque2 : 40|16@1+ (1,0) [0.0|64255.0] "Nm" Vector__XXX
 SG_ EngPeakTorque1 : 24|16@1+ (1,0) [0.0|64255.0] "Nm" Vector__XXX
 SG_ EngPower : 8|16@1+ (0.5,0) [0.0|32127.5] "kW" Vector__XXX
 SG_ NumberOfEngTorqueHistoryRecords : 0|8@1+ (1,0) [0.0|250.0] "records" Vector__XXX

BO_ 2364542206 ETC8_61452: 8 Vector__XXX
 SG_ TransCluCnvrInpSpd_5052 : 16|16@1+ (0.125,0) [0.0|8031.875] "rpm" Vector__XXX
 SG_ TransTorqueConverterRatio_3030 : 0|16@1+ (0.001,0) [0.0|64.255] "" Vector__XXX

BO_ 2566802174 ETC7: 8 Vector__XXX
 SG_ TransAutoNeutralSt : 50|2@1+ (1,0) [0.0|3.0] "" Vector__XXX
 SG_ TransWarningIndicator : 42|2@1+ (1,0) [0.0|3.0] "" Vector__XXX
 SG_ TrnsRverseGearShiftInhibitStatus : 40|2@1+ (1,0) [0.0|3.0] "" Vector__XXX
 SG_ TransMode8Indicator : 38|2@1+ (1,0) [0.0|3.0] "" Vector__XXX
 SG_ TransMode7Indicator : 36|2@1+ (1,0) [0.0|3.0] "" Vector__XXX
 SG_ TransMode6Indicator : 34|2@1+ (1,0) [0.0|3.0] "" Vector__XXX
 SG_ TransMode5Indicator : 32|2@1+ (1,0) [0.0|3.0] "" Vector__XXX
 SG_ TransRequestedGearFeedback : 24|8@1+ (1,-125) [-125.0|125.0] "" Vector__XXX
 SG_ TransMode1Indicator : 22|2@1+ (1,0) [0.0|3.0] "" Vector__XXX
 SG_ TransMode2Indicator : 20|2@1+ (1,0) [0.0|3.0] "" Vector__XXX
 SG_ TransMode3Indicator : 18|2@1+ (1,0) [0.0|3.0] "" Vector__XXX
 SG_ TransMode4Indicator : 16|2@1+ (1,0) [0.0|3.0] "" Vector__XXX
 SG_ TransShiftInhibitIndicator : 14|2@1+ (1,0) [0.0|3.0] "" Vector__XXX
 SG_ TransEngCrankEnable : 12|2@1+ (1,0) [0.0|3.0] "" Vector__XXX
 SG_ ActiveShiftConsoleIndicator : 10|2@1+ (1,0) [0.0|3.0] "" Vector__XXX
 SG_ TransReadyForBrakeRelease : 8|2@1+ (1,0) [0.0|3.0] "" Vector__XXX
 SG_ TrnsRqstedRangeDisplayFlashState : 6|2@1+ (1,0) [0.0|3.0] "" Vector__XXX
 SG_ TrnsRqstedRangeDisplayBlankState : 4|2@1+ (1,0) [0.0|3.0] "" Vector__XXX
 SG_ TransServiceIndicator : 2|2@1+ (1,0) [0.0|3.0] "" Vector__XXX
 SG_ TransAirSupplyPressIndicator : 48|2@1+ (1,0) [0.0|3.0] "" Vector__XXX
 SG_ TransMode10Indicator : 46|2@1+ (1,0) [0.0|3.0] "" Vector__XXX
 SG_ TransMode9Indicator : 44|2@1+ (1,0) [0.0|3.0] "" Vector__XXX
 SG_ TrnsCrrentRangeDisplayBlankState : 0|2@1+ (1,0) [0.0|3.0] "" Vector__XXX

BO_ 2633935870 ETC6: 8 Vector__XXX
 SG_ ClutchLifeRemaining : 24|8@1+ (0.4,0) [0.0|100.0] "%" Vector__XXX
 SG_ LowestPossibleGear : 16|8@1+ (1,-125) [-125.0|125.0] "" Vector__XXX
 SG_ HighestPossibleGear : 8|8@1+ (1,-125) [-125.0|125.0] "" Vector__XXX
 SG_ RecommendedGear : 0|8@1+ (1,-125) [-125.0|125.0] "" Vector__XXX

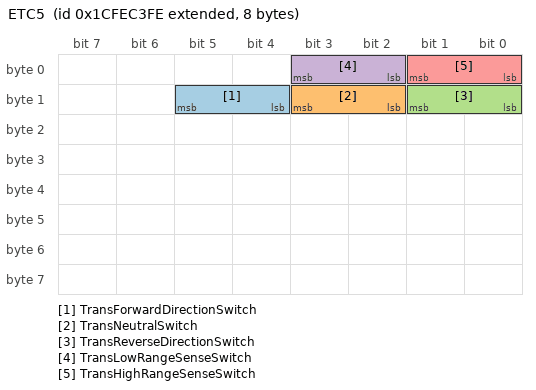
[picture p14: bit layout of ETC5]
BO_ 2633942014 ETC5: 8 Vector__XXX
 SG_ TransForwardDirectionSwitch : 12|2@1+ (1,0) [0.0|3.0] "" Vector__XXX
 SG_ TransNeutralSwitch : 10|2@1+ (1,0) [0.0|3.0] "" Vector__XXX
 SG_ TransReverseDirectionSwitch : 8|2@1+ (1,0) [0.0|3.0] "" Vector__XXX
 SG_ TransLowRangeSenseSwitch : 2|2@1+ (1,0) [0.0|3.0] "" Vector__XXX
 SG_ TransHighRangeSenseSwitch : 0|2@1+ (1,0) [0.0|3.0] "" Vector__XXX

BO_ 2633942526 ETC4: 8 Vector__XXX
 SG_ TransSynchronizerBrakeValue : 8|8@1+ (0.4,0) [0.0|100.0] "%" Vector__XXX
 SG_ TransSynchronizerClutchValue : 0|8@1+ (0.4,0) [0.0|100.0] "%" Vector__XXX

CM_ BO_ 2348941054  "Transmission Control 1";
CM_ BO_ 2566839806  "Turbocharger";
CM_ BO_ 2633911806  "Total Averaged Information
Averages of information accumulated over the life of the engine";
CM_ BO_ 2566775550  "Supply Pressure Demand
Used for controlling the supply pressure.  Often used to raise the pressure of a supply pressure circuit in situations where more pneumatic energy is needed.
This message is the setpoint for the PGN 65198 message.";
CM_ BO_ 2566819838  "Supply Pressure 2";
CM_ BO_ 2566839038  "Software Identification
Byte: 1 Number of software identification fields
2-n Software identification(s)
Delimiter (ASCII “*”)
NOTE- The software identification field is variable in length and may contain up to 125 software identification ...";
CM_ BO_ 2566841598  "Shutdown";
CM_ BO_ 2566786302  "Working Set Member
This message is sent by the Master of a Working Set to identify an individual member of a specific Working Set (Master’s Source Address identifies the particular Working Set).";
CM_ BO_ 2566832382  "Service Information
Transmitted with the service component identification that has the shortest distance or nearest time until the next service inspection.
NOTE - There are two acceptable formats for the Service PGN.  Format 1 has only 8 bytes of ...";
CM_ BO_ 2633928446  "Service 2
NOTE - There are two acceptable formats for the Service PGN.  Format 1 has only 8 bytes of data and reports the component most in need of service for each of the three categories.  Format 2, however, uses the transport protocol as ...";
CM_ BO_ 2566804478  "Retarder Continuous Torque & Speed Limit";
CM_ BO_ 2566847486  "Retarder fluids";
CM_ BO_ 2631859966  "Reset - NOTE This message requires an Acknowledgement response (See J1939-21,PGN 59392) from the receiving node.The use of individual proprietary protocols can still be used instead of the trip reset PGN to maintain security.";
CM_ BO_ 2566840830  "Retarder Configuration
This map describes the stationary behavior of the retarder.
Note:  Grandfathered definition for systems that implemented this message prior to July, 2010: On change of torque/speed points of more than 10% since last ...";
CM_ BO_ 2633930238  "Rebuild Information";
CM_ BO_ 2566844670  "Power Takeoff Information";
CM_ BO_ 2566770174  "Operator Wiper and Washer Controls Message
Message for items related to the operators controls for the window wipers and washers on the front and rear cab windows";
CM_ BO_ 2566769662  "Off-Highway Engine Control Selection
Allows for the selection of off-highway engine control modes, as they apply to different modes of engine operation which may be used to aid particular working environments. By offering characteristics suitable ...";
CM_ BO_ 2566768638  "Off-Highway Engine Control Selection States
Reports the states of off-highway engine control modes, as they apply to different modes of engine operation which may be used to aid particular working environments. These states provide the controls ...";
CM_ BO_ 2365443326  "Operators External Light Controls Message
The message containing the information about the position of the operator's external light control switch(s).  Including switches for the Headlights, turn signals, hazard light, clearance lights, marker ...";
CM_ BO_ 2566776318  "Maximum Vehicle Speed Limit Status
Reports the possible maximum vehicle speed limits, one through seven, and the applied maximum vehicle speed limit.";
CM_ BO_ 2566802686  "Military Lighting Command
The message contains parameters that control military specific lights.";
CM_ BO_ 2566774014  "Marine Control Information
This messages contains marine vessel control information for the engine";
CM_ BO_ 2566823166  "Main Bearing Temperature 3";
CM_ BO_ 2566823422  "Main Bearing Temperature 2";
CM_ BO_ 2566823678  "Main Bearing Temperature 1";
CM_ BO_ 2432595710  "Laser Leveling System Vertical Position Display Data";
CM_ BO_ 2365486590  "Laser Leveling System Vertical Deviation";
CM_ BO_ 2365485566  "Laser Tracer Position";
CM_ BO_ 2633939454  "Trip Fuel Information (Liquid)";
CM_ BO_ 2365486334  "Modify Leveling System Control Set Point";
CM_ BO_ 2364542462  "Land Leveling System Operational Information - Group of operational parameters associated with the Land Leveling System, such as switch states.    This is provided to the device controlling the blade, and is usually directed at the primary land ...";
CM_ BO_ 2365486078  "Laser Receiver Mast Position";
CM_ BO_ 2633937918  "Fuel Information 1 (Liquid)";
CM_ BO_ 2566845182  "Fuel Economy (Liquid)";
CM_ BO_ 2566842878  "Fuel Consumption (Liquid) 1
Engine fuel consumption accumulators.  See PGN 64777 for alternate resolution.";
CM_ BO_ 2633883646  "Front Wheel Drive Status
Front wheel drive ECU information";
CM_ BO_ 2633880062  "FMS-standard Interface Identity/Capabilities
Information which specifies the capabilities of the Fleet Management System (FMS) - standard interface device. This PGN typically is sourced from the network interconnect FMS - standard interface device.";
CM_ BO_ 2566806526  "Forward Lane Image 2";
CM_ BO_ 2431649790  "Forward Lane Image 1";
CM_ BO_ 2633929214  "Fuel Leakage";
CM_ BO_ 2566831614  "Fan Drive #1
This parameter group transfers status and measured information for an engine coolant fan.  This PGN is used for the primary fan if there are more than one fan in the syste.  PGN 64817 may be used for a second fan.";
CM_ BO_ 2566820094  "Engine Torque History
NOTE - The torque history PGN is variable in length and may contain up to 125 torque history records.  Each torque history record MUST BE 38 bytes in length.  Any unused bytes must be 0xFF.
The last six bytes of each record ...";
CM_ BO_ 2364542206  "Electronic Transmission Controller #8 - Electronic Transmission Controller #8";
CM_ BO_ 2566802174  "Electronic Transmission Controller 7
Transmission status information from the transmission controller to network.";
CM_ BO_ 2633935870  "Electronic Transmission Controller 6";
CM_ BO_ 2633942014  "Electronic Transmission Controller 5";
CM_ BO_ 2633942526  "Electronic Transmission Controller 4";
CM_ SG_ 2348941054 AutoNeutralReq_7695 "This parameter conveys a vehicle system desire to override the operator’s current shift selector request (e.g. Drive, Reverse) and shift the transmission into Neutral. “Manual Return” indicates this parameter has the ability to initiate a ...";
CM_ SG_ 2348941054 TransMode8_4249 "Indicates whether transmission mode 8 is enabled. Modes are manufacturer specific and are not necessarily mutually exclusive. See also SPN 4253.
00  Disable
01  Enable
10  Reserved
11  Take no action";
CM_ SG_ 2348941054 TransMode7_4248 "Indicates whether transmission mode 7 is enabled. Modes are manufacturer specific and are not necessarily mutually exclusive. See also SPN 4252.
00  Disable
01  Enable
10  Reserved
11  Take no action";
CM_ SG_ 2348941054 TransMode6_4247 "Indicates whether transmission mode 6 is enabled. Modes are manufacturer specific and are not necessarily mutually exclusive. See also SPN 4251.
00  Disable
01  Enable
10  Reserved
11  Take no action";
CM_ SG_ 2348941054 TransMode5_4246 "Indicates whether transmission mode 5 is enabled. Modes are manufacturer specific and are not necessarily mutually exclusive. See also SPN 4250.
00  Disable
01  Enable
10  Reserved
11  Take no action";
CM_ SG_ 2348941054 TrnsShftSelectorDMS_2985 "Status of the operator’s switch used to ‘toggle’ through multiple display modes of a shift selector display.
When a shift selector display is capable of displaying more than just range information, this switch is toggled by the operator to move ...";
CM_ SG_ 2348941054 TransRequestedLaunchGear_4255 "Initial gear for the transmission to start out in when the vehicle is launched from a standing stop, as specified by the vehicle operator or vehicle system.  Automatic transmissions typically default to starting out in 1st gear.  However, in ...";
CM_ SG_ 2348941054 TransMode4_1855 "Indicates whether transmission mode 4 is enabled.  Modes are manufacturer specific and are not necessarily mutually exclusive.  See also SPN 2539.
00 Disable
01 Enable
10 Reserved
11 Take no action";
CM_ SG_ 2348941054 TransMode3_1854 "Indicates whether transmission mode 3 is enabled.  Modes are manufacturer specific and are not necessarily mutually exclusive.  See also SPN 2538.
00 Disable
01 Enable
10 Reserved
11 Take no action";
CM_ SG_ 2348941054 TransMode2_1853 "Indicates whether transmission mode 2 is enabled.  Modes are manufacturer specific and are not necessarily mutually exclusive.  See also SPN 2537.
00 Disable
01 Enable
10 Reserved
11 Take no action";
CM_ SG_ 2348941054 TransMode1_1852 "Indicates whether transmission mode 1 is enabled.  Modes are manufacturer specific and are not necessarily mutually exclusive.  See also SPN 2536.
00 Disable
01 Enable
10 Reserved
11 Take no action";
CM_ SG_ 2348941054 TransLoadReductionInhibitRq_5762 "Request signal to the transmission to inhibit activation of load reduction functions.
Automatic transmissions may incorporate functions designed to reduce engine load during certain operating conditions (vehicle standstill at bus stop, traffic ...";
CM_ SG_ 2348941054 DisengDiffLockRqCentralRear_691 "Command signal used to disengage the various differential locks, e.g., to allow an undistributed individual wheel control by ABS.  The differential locks are located as defined in Figure SPN564_A.
00 Engage differential lock
01 Disengage ...";
CM_ SG_ 2348941054 DisengDiffLockRqCentralFront_690 "Command signal used to disengage the various differential locks, e.g., to allow an undistributed individual wheel control by ABS.  The differential locks are located as defined in Figure SPN564_A.
00 Engage differential lock
01 Disengage ...";
CM_ SG_ 2348941054 DisengageDiffLockRqCentral_689 "Command signal used to disengage the various differential locks, e.g., to allow an undistributed individual wheel control by ABS.  The differential locks are located as defined in Figure SPN564_A.
00 Engage differential lock
01 Disengage ...";
CM_ SG_ 2348941054 DisengageDiffLockRqRearAxle2_688 "Command signal used to disengage the various differential locks, e.g., to allow an undistributed individual wheel control by ABS.  The differential locks are located as defined in Figure SPN564_A.
00 Engage differential lock
01 Disengage ...";
CM_ SG_ 2348941054 DisengageDiffLockRqRearAxle1_687 "Command signal used to disengage the various differential locks, e.g., to allow an undistributed individual wheel control by ABS.  The differential locks are located as defined in Figure SPN564_A.
00 Engage differential lock
01 Disengage ...";
CM_ SG_ 2348941054 DisengDiffLockRqFrontAxle2_686 "Command signal used to disengage the various differential locks, e.g., to allow an undistributed individual wheel control by ABS.  The differential locks are located as defined in Figure SPN564_A.
00 Engage differential lock
01 Disengage ...";
CM_ SG_ 2348941054 DisengDiffLockRqFrontAxle1_685 "Command signal used to disengage the various differential locks, e.g., to allow an undistributed individual wheel control by ABS.  The differential locks are located as defined in Figure SPN564_A.
00 Engage differential lock
01 Disengage ...";
CM_ SG_ 2348941054 TransRequestedGear_525 "Gear requested by the operator, ABS, or engine.
Negative values are reverse gears, positive values are forward gears, zero is neutral, parameter specific indicators are listed below.
Parameter specific values for this parameter are as follows:
...";
CM_ SG_ 2348941054 RequestedPercentClutchSlip_684 "Parameter which represents the percent clutch slip requested by a device.";
CM_ SG_ 2348941054 TransRevGearShiftInhibitRq_4242 "Allows devices external to the normal transmission shift selector system to request the transmission to inhibit shifts into any Reverse gear and force the transmission into Neutral if it is currently in Reverse or attempting to shift to Reverse ...";
CM_ SG_ 2348941054 DisengageDrivelineRq_683 "Command signal used to simply disengage the driveline, e.g., to prevent engine drag torque from causing high wheel slip on slippery surfaces.
00 Allow driveline engagement
01 Disengage driveline
10 Reserved
11 Take no action
Note:  If this ...";
CM_ SG_ 2348941054 TrnsTrqeConvLockupDisableRq_682 "Command signal to prevent torque converter lockup, which may cause problems in certain circumstances for ASR.
00 Allow torque converter lockup
01 Disable torque converter lockup
10 Reserved
11 Take no action";
CM_ SG_ 2348941054 TransGearShiftInhibitRq_681 "Command signal to inhibit gear shifts.
00 Gear shifts are allowed  (disable function)
01 Gear shifts are inhibited  (enable function)
10 Reserved
11 Take no action  (leave function as is)";
CM_ SG_ 2566839806 EngTurboOilLevelSwitch "Switch signal which indicates the presence of oil at the turbocharger
00 = No oil present at turbocharger
01 = Oil present at turbocharger
10 = Error
11 = Not available";
CM_ SG_ 2566839806 EngTurbo1Speed "Rotational velocity of rotor in the turbocharger.";
CM_ SG_ 2566839806 EngTurboLubeOilPress1 "Gage pressure of oil in turbocharger lubrication system.";
CM_ SG_ 2566839806 EngTurboDiffSpeed "The difference between turbocharger speeds on engine systems with 2 or more turbochargers. If there are are more than 2 turbochargers, it will be the difference between the fastest and the slowest turbocharger speed.";
CM_ SG_ 2633911806 EngTotalAverageFuelEconomy "Average fuel economy, equal to total vehicle distance divided by total fuel used, over the life of the engine";
CM_ SG_ 2633911806 EngTotalAverageFuelRate "Average fuel rate, equal to total fuel used divided by total engine hours, over the life of the engine";
CM_ SG_ 2566775550 PwertrainCircuitAirSupplyPressRq "Command signal to influence the air pressure in the powertrain circuit.  This parameter is the setpoint for the parameter SPN 6305.";
CM_ SG_ 2566775550 AirSuspensionSupplyPressRq "Command signal to influence the pneumatic pressure in the circuit for the electronically controlled air suspension system.   This parameter is the setpoint for the parameter SPN 1090.";
CM_ SG_ 2566775550 AuxEquipmentSupplyPressRq "Command signal to influence the pneumatic pressure in the auxiliary circuit.   This parameter is the setpoint for the parameter SPN 1089.";
CM_ SG_ 2566775550 ServiceBrakeAirPressRqCircuit2 "Command signal to influence the pneumatic pressure in the service brake circuit or reservoir #2.  This parameter is the setpoint for the parameter SPN 1088.";
CM_ SG_ 2566775550 ServiceBrakeAirPressRqCircuit1 "Command signal to influence the pneumatic pressure in the service brake circuit or reservoir #1.  This parameter is the setpoint for the parameter SPN 1087.";
CM_ SG_ 2566775550 ParkingAnd_orTrailerAirPressRq "Command signal to influence the pneumatic pressure in the circuit or reservoir for the parking brake and/or the trailer supply.  This parameter is the setpoint for the parameter SPN 1086.";
CM_ SG_ 2566775550 PneumaticSupplyPressRq "Command signal to influence the pneumatic pressure in the main reservoir.  This parameter is the setpoint for the parameter SPN 46.";
CM_ SG_ 2566819838 EngExtlShutdownAirSupplyPress "Pressure of the air used to shut off the fuel supply to the engine.";
CM_ SG_ 2566839038 NmbrOfSftwreIdentificationFields "Number of software identification designators represented in the software identification parameter group.";
CM_ SG_ 2566839038 SoftwareIdentification "Software identification of an electronic module.  As an example, this parameter may be represented with ASCII characters MMDDYYaa where MM is the month, DD is the day, YY is the year, and aa is the revision number.
NOTE The ASCII character “*” is ...";
CM_ SG_ 2566841598 ClntLvlEngPrtctionShutdownStatus "Parameter which indicates the configuration of the coolant level engine protection shutdown.
00 - Disabled - calibration does not allow engine protection due to low coolant level or the override is currently active
01 - Enabled - calibration ...";
CM_ SG_ 2566841598 PTOShutdownHasShutdownEng "Status signal which identifies whether or not the engine has been shutdown by the PTO shutdown system.
00 - No
01 - Yes
10 - Error
11 - Not available";
CM_ SG_ 2566841598 EngAirShutoffStatus "State signal which indicates the actual measured position of the Air Shutoff.
00 - Air flow allowed to engine
01 - Air flow restricted
10 - Error
11 - Not Available
Note:   This parameter, in conjunction with SPN 2813 - \"Engine Air Shutoff ...";
CM_ SG_ 2566841598 EngOverspeedTest "The engine overspeed test signal as measured by the reporting ECM.  Engine Overspeed Test is a mechanism to simulate engine overspeed situations, while operating the engine within the engine's safe operating range.
State signal which indicates when ...";
CM_ SG_ 2566841598 EngAirShutoffCmdStatus "State signal which indicates when the Air Shutoff  driver output is being driven. Disabled means controller wants air flowing to the engine. Status of the airflow  shutoff as being commanded by the ECU.
00 Air Shutoff Disabled, not attempting to ...";
CM_ SG_ 2566841598 EngAlarmOutputCmdStatus "State signal which indicates when the Alarm driver output is being driven. Not active means the Controller has no alarm level conditions.
00 Engine Alarm Output Command Not Active
01 Engine Alarm Output Command Active
10 Reserved
11 Not ...";
CM_ SG_ 2566841598 EngAlarmAcknowledge "The Engine Alarm Acknowledge Input signal as measured by the reporting ECU.  The Engine Alarm Acknowledge is a mechanism for external acknowledgement of the SPN 2814,  Engine Alarm Output Command.
00 Engine Alarm Acknowledge  Not Active
01 Engine ...";
CM_ SG_ 2566841598 EngProtectionSystemConfig "Parameter which indicates the configuration of the engine shutdown system.
00 - Disabled in calibration
01 - Enabled in calibration
10 - Error
11 - Not available";
CM_ SG_ 2566841598 EngProtectionSystemTimerState "Status signal which indicates the current mode of the engine protection system timer system.  See Figure SPN1107_A.
00 - Inactive
01 - Active
10 - Error
11 - Not available";
CM_ SG_ 2566841598 EngProtectionSystemTimerOverride "Status signal which indicates the status of the override feature of the engine protection system timer. See Figure SPN1107_A.
00 - Inactive
01 - Active
10 - Error
11 - Not available";
CM_ SG_ 2566841598 EngPrtctnSystmApprachingShutdown "Status signal which indicates that engine shutdown is imminent.  This engine protection signal can be a result of different systems failing, i.e., engine overheating. See Figure SPN1107_A.
00 - Not approaching
01 - Approaching
10 - Error
11 - ...";
CM_ SG_ 2566841598 EngPrtectionSystemHasShutdownEng "Status signal which indicates whether or not the engine protection system has shutdown the engine.  See Figure SPN1107_A.
00 - No
01 - Yes
10 - Error
11 - Not available";
CM_ SG_ 2566841598 EngWaitToStartLamp "Lamp signal which indicates that the engine is too cold to start and the operator should wait until the signal becomes inactive (turns off).  See SPN 5416 for the lamp operating condition.
00 - Off
01 - On
10 - Error
11 - Not available";
CM_ SG_ 2566841598 RefrigerantHighPressSwitch "Switch signal which indicates the position of the high pressure switch in the coolant circuit of an air conditioning system.  When the switch is enabled, the pressure inside the circuit is too high and the compressor clutch may be disengaged.
00 - ...";
CM_ SG_ 2566841598 RefrigerantLowPressSwitch "Switch signal which indicates the position of the low pressure switch in the coolant circuit of an air conditioning system.  When the switch is enabled, the pressure inside the circuit is too low and the compressor clutch may be disengaged.
00 - ...";
CM_ SG_ 2566841598 A_CHighPressFanSwitch "Switch signal which indicates that the pressure in the coolant circuit of an air conditioning system is high and the fan may be engaged.
00 - Pressure normal
01 - Pressure high, fan may be engaged
10 - Error
11 - Not available";
CM_ SG_ 2566841598 EngIdleShutdownTimerFunction "Parameter which indicates the configuration of the idle shutdown timer system.
00 - Disabled in calibration
01 - Enabled in calibration
10 - Error
11 - Not available";
CM_ SG_ 2566841598 EngIdleShutdownTimerState "Status signal which indicates the current mode of operation of the idle shutdown timer system.  See Figure SPN590_A.
00 - Inactive
01 - Active
10 - Error
11 - Not available";
CM_ SG_ 2566841598 EngIdleShutdownTimerOverride "Status signal which indicates the status of the override feature of the idle shutdown timer system.  See Figure SPN590_A.
00 - Inactive
01 - Active
10 - Error
11 - Not available";
CM_ SG_ 2566841598 EngIdleShutdownDriverAlertMode "Status signal which indicates the status of the driver alert mode of the idle shutdown timer system.  While the driver alert mode is active, the idle shutdown timer may be overridden.  See Figure SPN590_A.
00 - Inactive
01 - Active
10 - Error
11 ...";
CM_ SG_ 2566841598 EngIdleShutdownHasShutdownEng "Status signal which identifies whether or not the engine has been shutdown by the idle shutdown timer system.  See Figure SPN590_A.
00 - No
01 - Yes
10 - Error
11 - Not available";
CM_ SG_ 2566786302 IndustryGroup "0 = Global;
1  = On-Highway;
2  = Agricultural and Forestry;
3  = Construction;
4  = Marine;
5  = Industrial - Process
Control - Stationary (Gen-Sets)
6  = Reserve for SAE
7  = Reserve for SAE";
CM_ SG_ 2566786302 ManufacturerCode "Assigned by NMEA 2000 Committee";
CM_ SG_ 2566832382 SrviceDelay_OperationalTimeBased "The time in vehicle operational time until the next vehicle service inspection is required.  A negative value is transmitted if the service inspection has been passed.  The component that requires service is identified by the service component ...";
CM_ SG_ 2566832382 ServiceComponentIdentificatio913 "Identification of component needing service.  See Table SPN911_A.";
CM_ SG_ 2566832382 ServiceDelay_CalendarTimeBased "The time in weeks until the next vehicle service inspection is required.  A negative value is transmitted if the service inspection has been passed.  The component that requires service is identified by the service component identification (see SPN ...";
CM_ SG_ 2566832382 ServiceComponentIdentificatio912 "Identification of component needing service.  See Table SPN911_A.";
CM_ SG_ 2566832382 ServiceDistance "The distance which can be traveled by the vehicle before the next service inspection is required.  A negative distance is transmitted if the service inspection has been passed.  The component that requires service is identified by the service ...";
CM_ SG_ 2566832382 ServiceComponentIdentification "Identification of component needing service.  See Table SPN911_A.";
CM_ SG_ 2633928446 TimeSinceLastService "The vehicle operation time since the last service was performed.  The type of service information is identified by the service component identification number.";
CM_ SG_ 2633928446 ServiceComponentIdentification "Identification of component needing service.  See Table SPN911_A.";
CM_ SG_ 2566804478 MinContinuousRetarderTorque "Applied limit for minimum continuous retarder torque";
CM_ SG_ 2566804478 MaxContinuousRetarderTorque "Applied limit for maximum continuous retarder torque.";
CM_ SG_ 2566804478 MinContinuousRetarderSpeed "Applied limit for minimum continuous retarder RPM";
CM_ SG_ 2566804478 MaxContinuousRetarderSpeed "Applied limit for maximum continuous retarder RPM";
CM_ SG_ 2566804478 HghLmtThrshldFrMnCntnsTrqFrmRtrd "Maximum allowable value for minimum continuous retarder torque.";
CM_ SG_ 2566804478 LwLmtThrshldFrMxTrqeFromRetarder "Minimum allowable value for maximum continuous retarder torque.";
CM_ SG_ 2566804478 HghLmtThrshldFrMnCntnsRPMFrmRtrd "Maximum allowable value for minimum continuous retarder speed";
CM_ SG_ 2566804478 LwLmtThrshldFrMaxRPMFromRetarder "Minimum allowable value for maximum continuous retarder speed";
CM_ SG_ 2566847486 DrvlineRetarderOverheatIndicator "Signal from the driveline retarder indicating that its fluid temperature is above normal acceptable limits, and as a result, retarder operation may be altered or restricted.  The indicator is typically a lamp.  Distinctions in meaning between the ...";
CM_ SG_ 2566847486 RetarderCoolantOutletTemp "Temperature of liquid found in retarder cooling system.";
CM_ SG_ 2566847486 HydRetarderOilTemp "Temperature of oil found in a hydraulic retarder.";
CM_ SG_ 2566847486 HydRetarderPress "Gage pressure of oil in hydraulic retarder system.";
CM_ SG_ 2631859966 SteerStraightAheadPosReset_3600 "Used to reset the straight ahead position for a steering sensor in the steering column or a steering controller's straight ahead position on any steerable axle.
00 Take no action - Do not Reset
01 Reset
10 Reserved, take no action
11 Not ...";
CM_ SG_ 2631859966 EngBuildHoursReset_1211 "Command signal used to reset the engine rebuild hours.
00 Do not reset
01 Reset
10 Reserved
11 Take no action";
CM_ SG_ 2631859966 EngIgntCtrlMntnHoursRst_6219 "Used to reset the maintenance hour counter for an engine ignition control module.  The hours remaining until required maintenance is performed are reported in PGN 64688.
00 Do not reset
01 Reset
10 Reserved
11 Take no action";
CM_ SG_ 2631859966 EngSprkPlgScndUTrackingRst_6218 "Command signal used to reset the ignition controller average, maximum, and minimum level tracking of the spark plug secondary voltages and to reset the learned misfire rate.  Average secondary voltage tracking is reported in PGNs 64882 - 64887 ...";
CM_ SG_ 2631859966 SrvCptIdentification_1584 "Identification of component needing service.  See Table SPN911_A.";
CM_ SG_ 2631859966 TripGroup2Proprietary_989 "Command signal used to reset proprietary parameters associated with a trip but not defined within this document.
00 Take no action
01 Reset
10 Reserved
11 Not applicable";
CM_ SG_ 2631859966 TireSensorInformation_6986 "Command signal used to initiate change in the tire sensor identification information.
00 Take no action
01 Reset
10 Reserved
11 Not applicable";
CM_ SG_ 2631859966 TireConfigInformation_6985 "Command signal used to initiate change in the tire configuration of the vehicle system. On receipt of this reset, necessary changes will be made in the tire configuration command information.
00 - Take No Action
01 - Reset
10 - Reserved
11 - Not ...";
CM_ SG_ 2631859966 BinLiftCountReset_6898 "Used to reset the bin lift count as reported in PGN 64594.
00 Do not reset
01 Reset
10 Reserved
11 Take no action";
CM_ SG_ 2631859966 TripGroup1_988 "Command signal used to reset the PGNs and parameters as defined in Table SPN988_A.
00 Take no action
01 Reset
10 Reserved
11 Not applicable";
CM_ SG_ 2566840830 PercentTorqueAtPeakTorquePoint5 "The torque limit that indicates the available retarder torque which can be provided by the retarder at point 5 of the retarder torque map.  Please reference PGN 65249.  The data is transmitted in indicated torque as a percent of the reference ...";
CM_ SG_ 2566840830 ReferenceRetarderTorque "This parameter is the 100% reference value for all defined indicated retarder torque parameters.  It is only defined once and doesn't change if a different retarder torque map becomes valid.";
CM_ SG_ 2566840830 RetarderSpeedAtPeakTorquePoint5 "Please reference PGN 65249";
CM_ SG_ 2566840830 PercentTorqueAtPoint4 "The torque limit that indicates the available retarder torque which can be provided by the retarder at points 3 and 4 of the retarder torque map.  Please reference PGN 65249.  The data is transmitted in indicated torque as a percent of the reference ...";
CM_ SG_ 2566840830 RetarderSpeedAtPoint4 "Retarder speed of point 4 of the engine retarder torque map.  Please reference PGN 65249.";
CM_ SG_ 2566840830 PercentTorqueAtPoint3 "The torque limit that indicates the available retarder torque which can be provided by the retarder at points 3 and 4 of the retarder torque map.  Please reference PGN 65249.  The data is transmitted in indicated torque as a percent of the reference ...";
CM_ SG_ 2566840830 RetarderSpeedAtPoint3 "Retarder speed of point 3 of the engine retarder torque map.  Please reference PGN 65249.";
CM_ SG_ 2566840830 PercentTorqueAtMaxSpeedPoint2 "The torque limit that indicates the available retarder torque which can be provided by the retarder at its maximum speed.  Please reference PGN 65249.  The data is transmitted in indicated torque as a percent of the reference retarder torque.";
CM_ SG_ 2566840830 MaxRetarderSpeedPoint2 "Maximum speed of retarder (Please reference PGN 65249).";
CM_ SG_ 2566840830 PercentTorqueAtIdlePoint1 "The torque limit that indicates the available retarder torque which can be provided by the retarder at idle speed.  The data is transmitted in indicated torque as a percent of the reference retarder torque.";
CM_ SG_ 2566840830 RetarderSpeedAtIdlePoint1 "Please reference PGN 65249";
CM_ SG_ 2566840830 RetarderCtrlMethod "This parameter identifies the number of steps used by the retarder.";
CM_ SG_ 2566840830 RetarderLocation "This parameter defines whether the “torque/speed curve” defined by the retarder configuration message (PGN 65249) is dependent on engine rpm, output shaft rpm, or other parameter.  The data type of this parameter is measured.
0000  (Primary) ...";
CM_ SG_ 2566840830 RetarderType "A vehicle retarder is a supplementary device to the wheel brakes for the driver to better control the vehicle.  The wheel brakes used in the vehicle are not designed for continuous retarding operation.  In a prolonged period of braking, the brakes ...";
CM_ SG_ 2633930238 EngOperationTimeSinceRebuild "The time in engine operation since the last engine rebuild.";
CM_ SG_ 2566844670 PowerTakeoffSetSpeed "Rotational velocity selected by operator for device used to transmit engine power to auxiliary equipment.";
CM_ SG_ 2566844670 PowerTakeoffSpeed "Rotational velocity of device used to transmit engine power to auxiliary equipment.";
CM_ SG_ 2566844670 PowerTakeoffOilTemp "Temperature of lubricant in device used to transmit engine power to auxiliary equipment.";
CM_ SG_ 2566844670 OprtrEngPTOGvrnrMmrySelectSwitch "Measured state of the operator’s engine PTO governor memory select switch. This switch selects which of the two available memory locations is to be used to store the dynamically assigned value. This speed will be set using the PTO governor set ...";
CM_ SG_ 2566844670 EngRmtPTOGvrnrVrblSpedCtrlSwitch "Switch signal which indicates that the remote PTO governor toggle switch is in the enabled (ON) position.  If the toggle switch is enabled and other conditions are satisfied then the remote PTO governor feature is activated and the PTO governor will ...";
CM_ SG_ 2566844670 EngRmtPTOGvrnrPrprgrmmdSpdCtrlSw "Switch signal which indicates that the remote PTO governor  toggle switch is in the enabled (ON) position.  If the toggle switch is enabled and other conditions are satisfied then the remote PTO governor feature is activated and the PTO governor ...";
CM_ SG_ 2566844670 EngPTOGvrnrCast_DecelerateSwitch "Switch signal of the PTO control activator which indicates that the activator is in the position to \"coast/decelerate\" the PTO governor set speed.
00 - Off
01 - On
10 - Error
11 - Not available";
CM_ SG_ 2566844670 EngPTOGovernorSetSwitch "Switch signal of the PTO control activator which indicates that the activator is in the position to \"set\" the engine PTO governor set speed.
00 - Off
01 - On
10 - Error
11 - Not available";
CM_ SG_ 2566844670 EngPTOGovernorResumeSwitch "Switch signal of the PTO control activator which indicates that the activator is in the position to \"resume\" a previously established PTO governor set speed.
00 - Off
01 - On
10 - Error
11 - Not available";
CM_ SG_ 2566844670 EngPTOGovernorEnableSwitch "Switch signal which indicates that the PTO governor toggle switch is in the enabled (ON) position and therefore it is possible to manage the PTO control function.
00 - Off
01 - On
10 - Error
11 - Not available";
CM_ SG_ 2566844670 EngPTOGovernorAccelerateSwitch "Switch signal of the PTO control activator which indicates that the activator is in the position to \"accelerate\" the PTO governor set speed.
00 - Off
01 - On
10 - Error
11 - Not available";
CM_ SG_ 2566844670 RmtPTOGvrnrPrprgrmmdSpdCtrlSwtch "Switch signal which indicates that the remote PTO governor toggle switch #2 is in the enabled (ON) position. If the toggle switch is enabled and other conditions are satisfied then the remote PTO governor control feature is activated and the PTO ...";
CM_ SG_ 2566844670 AuxInputIgnoreSwitch "Switch signal which overrides other switch input's ability to disable an engine's operating condition.
00 - Off
01 - On
10 - Error
11 - Not Available
This switch input can be used to prevent the PTO from disengaging if another switch input's ...";
CM_ SG_ 2566770174 RearWasherFunction "State of operation selected by operator switch for the rear washer.   The parameter, 'Front Operator Washer Switch’ should be used for the control information if this parameter is 'Not Available' and the associated washer still needs to be ...";
CM_ SG_ 2566770174 FrontOperatorWasherSwitch "State of operation selected by operator switch for the washer in front of the operator position. This parameter, 'Front Operator Washer Switch’ should be used for the control information if either of the other washer switch parameters  is 'Not ...";
CM_ SG_ 2566770174 FrontNonoperatorWasherSwitch "State of operation selected by operator switch for the front washer not in front of the operator position.  The parameter, 'Front Operator Washer Switch’ should be used for the control information if this parameter  is 'Not Available' and the ...";
CM_ SG_ 2566770174 RearWiperDelayCtrl "Time between cycles of the rear wiper (i.e. from end of cycle 'n' to start of cycle 'n+1') as selected by the operator control (switch, etc.) in percentage of position with maximum position corresponding to maximum delay selectable.  The parameter, ...";
CM_ SG_ 2566770174 FrontNonoperatorWiperDelayCtrl "Time between cycles of the front non-operator side wiper (i.e. from end of cycle 'n' to start of cycle 'n+1') as selected by the operator control (switch, etc.) in percentage of position with maximum position corresponding to maximum delay ...";
CM_ SG_ 2566770174 FrontOperatorWiperDelayCtrl "Time between cycles of the front operator side wiper (i.e. from end of cycle 'n' to start of cycle 'n+1') as selected by the operator control (switch, etc.) in percentage of position with maximum position corresponding to maximum delay selectable ...";
CM_ SG_ 2566770174 RearWiperSwitch "State of operation selected by operator switch for the rear wiper.  The parameter, 'Front Operator Washer Switch' should be used for the control information if this parameter is 'Not Available' and the associated washer still needs to be controlled.
...";
CM_ SG_ 2566770174 FrontOperatorWiperSwitch "State of operation selected by operator switch for the Wiper in front of the operator position. This parameter, 'Front Operator Wiper Switch' should be used for the control information if either of the other wiper switch parameters is 'Not ...";
CM_ SG_ 2566770174 FrontNonoperatorWiperSwitch "State of operation selected by operator switch for the front wiper not in front of the operator position.  The parameter, 'Front Operator Washer Switch' should be used for the control information if this parameter is 'Not Available' and the ...";
CM_ SG_ 2566769662 EngTorqueCurveSelectionCmd "This parameter will allow selection of a torque curve that is higher than the base curve.
0 - Indicates that this parameter is not presently requesting a different torque curve be used
1 - Indicates that Torque Curve 1 is selected
2 - Indicates ...";
CM_ SG_ 2566769662 EngAltDroopAuxInputSelect "In some off-highway applications it may be desirable to have multiple droop settings available across the range of engine operation.  For example, in an agricultural tractor application, this functionality allows a higher engine speed during low ...";
CM_ SG_ 2566769662 EngAltDroopRemoteAccelSelect "In some off-highway applications it may be desirable to have multiple droop settings available across the range of engine operation.  For example, in an agricultural tractor application, this functionality allows a higher engine speed during low ...";
CM_ SG_ 2566769662 EngAltDroopAccel2Select "In some off-highway applications it may be desirable to have multiple droop settings available across the range of engine operation.  For example, in an agricultural tractor application, this functionality allows a higher engine speed during low ...";
CM_ SG_ 2566769662 EngAltDroopAccel1Select "In some off-highway applications it may be desirable to have multiple droop settings available across the range of engine operation.  For example, in an agricultural tractor application, this functionality allows a higher engine speed during low ...";
CM_ SG_ 2566769662 EngAltRatingSelect "In some off-highway applications it may be desirable to have multiple engine ratings available for selection by the operator. There is the default engine rating, which provides the maximum available power across the range of operation. There are ...";
CM_ SG_ 2566769662 EngAltLowIdleSwitch "Operator switch which selects between two low idle speeds, default and alternate.
The normal programmed low idle is the default low idle, and when the Alternate Low Idle switch is activated, a alternate preprogrammed low idle speed is selected. The ...";
CM_ SG_ 2566769662 EngSynchronizationSwitch "This is the On/Off operation of the Multiple Unit Synchronization functionality. When it is enabled (i.e. On) the master engine will synchronize one or more slave engines to operate at the same speed. This switch position indicates whether this ...";
CM_ SG_ 2566769662 EngAuxGovernorSwitch "This is the On/Off operation of the Auxiliary Governor feature switch. This feature is used to allow engine speed to be controlled by an auxiliary input such as pressure or tailshaft speed. This switch position indicates whether this feature is ...";
CM_ SG_ 2566768638 EngTorqueCurveSelection "This parameter will report the selected torque curve, as indicated by SPN 6796.
0 - Indicates that the engine is using a torque that is not presently selected by SPN 6796
1 - Indicates that Torque Curve 1 is selected
2 - Indicates that Torque ...";
CM_ SG_ 2566768638 EngAltDroopAuxInputSelectState "In some off-highway applications it may be desirable to have multiple droop settings available across the range of engine operation.  For example, in an agricultural tractor application, this functionality allows a higher engine speed during low ...";
CM_ SG_ 2566768638 EngAltDropRemoteAccelSelectState "In some off-highway applications it may be desirable to have multiple droop settings available across the range of engine operation.  For example, in an agricultural tractor application, this functionality allows a higher engine speed during low ...";
CM_ SG_ 2566768638 EngAltDroopAccel2SelectState "In some off-highway applications it may be desirable to have multiple droop settings available across the range of engine operation.  For example, in an agricultural tractor application, this functionality allows a higher engine speed during low ...";
CM_ SG_ 2566768638 EngAltDroopAccel1SelectState "In some off-highway applications it may be desirable to have multiple droop settings available across the range of engine operation.  For example, in an agricultural tractor application, this functionality allows a higher engine speed during low ...";
CM_ SG_ 2566768638 EngAltRatingSelectState "This parameter reflects the control state that has been achieved based on the input from the SPN 2882.  In some off-highway applications it may be desirable to have multiple engine ratings available for selection by the operator.  There is the ...";
CM_ SG_ 2566768638 EngAltLowIdleSelectState "In many applications, it is desirable that an alternate low idle speed setting be made available via switch input. The normal programmed low idle is the default low idle, and when the Alternate Low Idle feature is activated, an alternate ...";
CM_ SG_ 2566768638 EngMultiUnitSyncState "This feature is widely used in Industry to operate multiple engines from a single command source. A master engine will “synchronize” one or more slave engines to operate at the same speed. This feature is requested by an operator switch, this ...";
CM_ SG_ 2566768638 EngAuxGovernorState "This is the Engine Auxiliary Governor feature. This feature is used to allow engine speed to be controlled by an auxiliary input such as pressure or tailshaft speed. This feature is requested by an operator switch, this parameter indicates the state ...";
CM_ SG_ 2365443326 OprtorsDesiredDelayedLampOffTime "A 16 bit parameter to be associated with Delayed Off position (1000 binary) of the Main Light Switch.  This parameter indicates the time the operator wishes to have elapse following the Main Light switch being placed in Delayed Off position before ...";
CM_ SG_ 2365443326 OperatorsDesiredBacklight "A 8 bit parameter to indicate the level of back lighting the operator has selected for displays.  This is to be differentiated from the Illumination Brightness Percent (SPN:1487 PGN:53248 Cab Illumination Message) which is sent to the displays to ...";
CM_ SG_ 2365443326 HighLowBeamSwitch "A 2 bit parameter to indicate the selected position of the operator's high/low beam select switch.
00  Low Beam Selected
01  High Beam Selected
10  Error
11  Not available (do not change)";
CM_ SG_ 2365443326 HazardLightSwitch "A 2 bit parameter to indicate the selected position of the operator's hazard light switch.
00   Hazard Lamps to be Off
01   Hazard Lamps to be Flashing
10   Error
11   Not available (do not change)";
CM_ SG_ 2365443326 TurnSignalSwitch "A 4 bit parameter to indicate the selected position of the operator's turn signal switch.
0000   No Turn being signaled
0001   Left Turn to be Flashing
0010   Right turn to be Flashing
0011 - 1101   Reserved
1110   Error (to include both left ...";
CM_ SG_ 2365443326 MainLightSwitch "A 4 bit parameter to indicate the selected position of the operator's main light switch.
0000 Off - The position by which the operator selects that none of the lamps are to be on.
0001 Park On - The position by which the operator selects that the ...";
CM_ SG_ 2365443326 WorkLightSwitch "A 4 bit parameter to indicate the selected position of the operator's work light switch. In Ag applications the work lights are often refereed to as field lights.  In on-highway applications the work lights are often referred to as clearance lights ...";
CM_ SG_ 2566776318 AppliedVehicleSpeedLimit "The vehicle speed limit in effect.
251 (0xFB) is used to indicate that a maximum vehicle speed limit is not selected.
See SPN 7420 for alternate resolution.";
CM_ SG_ 2566776318 MaxVehicleSpeedLimit7 "The highest of the seven lowest vehicle speed limits";
CM_ SG_ 2566776318 MaxVehicleSpeedLimit6 "The highest of the six lowest vehicle speed limits";
CM_ SG_ 2566776318 MaxVehicleSpeedLimit5 "The highest of the five lowest vehicle speed limits";
CM_ SG_ 2566776318 MaxVehicleSpeedLimit4 "The highest of the four lowest vehicle speed limits";
CM_ SG_ 2566776318 MaxVehicleSpeedLimit3 "The highest of the three lowest vehicle speed limits";
CM_ SG_ 2566776318 MaxVehicleSpeedLimit2 "The highest of the two lowest vehicle speed limits";
CM_ SG_ 2566776318 MaxVehicleSpeedLimit1 "The lowest Maximum Vehicle Speed Limit. This value is the similar to SPN 74. However, SPN 74 was not specifically defined to convey  the applied vehicle speed limit or what was possible to be applied. This new SPN is the lowest vehicle speed limit ...";
CM_ SG_ 2566802686 OprtrsBlackOutIntensitySelection "Operators Selection of lamp intensity in black out mode.  This parameter provides the operators selected illumination intensity as a percentage of available full scale.  This parameter would be typically used as a dash or instrument cluster ...";
CM_ SG_ 2566802686 BlackOutWorkLampSelect "Black Out Work Lamp Selection
00 Off
01 On
10 Reserved
11 Not Supported";
CM_ SG_ 2566802686 NightVisionIlluminatorSelect "Night Vision Illuminator Selection
00 Off
01 On
10 Reserved
11 Not Supported";
CM_ SG_ 2566802686 BlackOutBrake_StopLampSelect "Black Out Brake/Stop Lamp Selection
00 Off
01 On
10 Reserved
11 Not Supported";
CM_ SG_ 2566802686 ConvoyDrivingLampSelect "Black Out Convoy Driving Lamp Selection
00 Off
01 On
10 Reserved
11 Not Supported";
CM_ SG_ 2566802686 ConvoyLampSelect "Black Out Convoy Lamp Selection
00 Off
01 On
10 Reserved
11 Not Supported";
CM_ SG_ 2566802686 FrontBlackOutMarkerLampSelect "Front Black Out Marker Lamp Selection
00 Off
01 On
10 Reserved
11 Not Supported";
CM_ SG_ 2566802686 RearBlackOutMarkerSelect "Rear Black Out Marker Selection
00 Off
01 On
10 Reserved
11 Not Supported";
CM_ SG_ 2566774014 SlowVesselModeStatus "The status of the Slow Vessel Mode.  Slow Vessel Mode puts the engine in a lower-than-normal low idle speed during docking or other slow vessel operations.
00 Slow vessel mode is OFF.
01 Slow vessel mode is ACTIVE.
10 Reserved
11 Take no action
...";
CM_ SG_ 2566774014 TrollingModeStatus "The status of the Trolling Mode.  Trolling mode limits the top speed.  Full range travel of the throttle level spans from low idle engine speed to maximum trolling speed.
00 Trolling mode is OFF.
01 Trolling mode is ACTIVE.
10 Reserved
11 Take ...";
CM_ SG_ 2566774014 EngThrttlSynchrnzationModeStatus "The status of the Throttle Synchronization Mode. Throttle Synchronization Mode is used to indicate which throttle, if any, is currently being used for the synchronized throttle.
0000 Not Synchronized
0001 Synchronized Center
0010 Synchronized ...";
CM_ SG_ 2566823166 EngMainBearing12Temp "Temperature of the main bearing which supports the crankshaft of the engine.";
CM_ SG_ 2566823166 EngMainBearing11Temp "Temperature of the main bearing which supports the crankshaft of the engine.";
CM_ SG_ 2566823166 EngMainBearing10Temp "Temperature of the main bearing which supports the crankshaft of the engine.";
CM_ SG_ 2566823166 EngMainBearing9Temp "Temperature of the main bearing which supports the crankshaft of the engine.";
CM_ SG_ 2566823422 EngMainBearing8Temp "Temperature of the main bearing which supports the crankshaft of the engine.";
CM_ SG_ 2566823422 EngMainBearing7Temp "Temperature of the main bearing which supports the crankshaft of the engine.";
CM_ SG_ 2566823422 EngMainBearing6Temp "Temperature of the main bearing which supports the crankshaft of the engine.";
CM_ SG_ 2566823422 EngMainBearing5Temp "Temperature of the main bearing which supports the crankshaft of the engine.";
CM_ SG_ 2566823678 EngMainBearing4Temp "Temperature of the main bearing which supports the crankshaft of the engine.";
CM_ SG_ 2566823678 EngMainBearing3Temp "Temperature of the main bearing which supports the crankshaft of the engine.";
CM_ SG_ 2566823678 EngMainBearing2Temp "Temperature of the main bearing which supports the crankshaft of the engine.";
CM_ SG_ 2566823678 EngMainBearing1Temp "Temperature of the main bearing which supports the crankshaft of the engine.";
CM_ SG_ 2432595710 DisplayDeadbands "Sets Display Deadbands mode.
0000 - Narrow = +/- 4.5mm
0001 - Standard = +/- 12mm
0010 - Wide = +/- 24mm
0011 - 1110 Reserved
1111 Not Available";
CM_ SG_ 2432595710 LEDPatternCtrl "Sets LED Pattern control mode on laser leveling systems.
0000 - 5 Channel
0001 - Offset
0010 - 7 Channel
0011 - 1110 Reserved
1111 Not Available";
CM_ SG_ 2432595710 LEDDisplayDeadbandCtrl "This parameter informs the system what the selected Display deadband will be.
0000    +/- 4.5 mm  (0.015 feet, 0.18 inches)
0001    +/- 12 mm   (0.040 feet, 0.45 inches)
0010    +/- 24 mm   (0.080 feet, 0.96 inches)
0011    +/- 5  mm    (0.017 ...";
CM_ SG_ 2432595710 LEDDisplayModeCtrl "This parameter informs the system what the selected Display mode will be.
0000 - Center On-Grade Display Mode 1 ( 5 CHANNEL )
0001 - Offset On-Grade Display Mode
0010 - Center On-Grade Display Mode 2 ( 7 CHANNEL )
0011 - 1110 Reserved
1111 - ...";
CM_ SG_ 2432595710 LEDDisplayData1 "Informs display devices how to display the current vertical position.
Values which are less than 128 decimal are bit-mapped values and any combination of these values is considered a valid value.  For example communicating the \"High Fine LED on\" ...";
CM_ SG_ 2365486590 AbsLaserStrikePos "Laser Strike location on the survey type  laser receiver.";
CM_ SG_ 2365486590 LaserStrikeDataLatency "Time from laser strike to CAN message transmission.  This parameter will be reported by survey receiver type devices only. Byte 3 (SPN 2576) of  PGN 65141 identifies the type of Laser Receiver.";
CM_ SG_ 2365486590 LaserReceiverType "Identifies which type of Laser Receiver transmitted the message.
0 = Reserved
1 = Linear Laser Receiver
2 = 1 Meter Survey Receiver
3 = 2 Meter Survey Receiver
4 = 2.5 Meter Survey Receiver
5-250 = Reserved";
CM_ SG_ 2365486590 LaserStrikeVerticalDeviation "The calculated distance from the laser strike position to the current land leveling system reference point.";
CM_ SG_ 2365485566 LaserTracerInformation "Provides the status of the laser tracer to the operator.
00000001 Laser power is on
00000010 Laser is ready
00000100 Valid target (1 = yes)
00001000 Previous pass (1 = yes)
00010000 Stringline (1 = yes)
00100000 Curb (1 = yes)
All other ...";
CM_ SG_ 2365485566 LEDDisplayData2 "Informs display devices how to display the current position of the laser tracer.
Values which are less than 128 decimal are bit-mapped values and any combination of these values is considered a valid value.  For example communicating the \"Up LED ...";
CM_ SG_ 2365485566 LaserTracerHorizontalDeviation "The calculated percent deviation between the target distance and the center of the laser tracer.";
CM_ SG_ 2365485566 LaserTracerVerticalDistance "The elevation of the laser tracer sensor in a laser leveling system.";
CM_ SG_ 2365485566 LaserTracerTargetDeviation "The calculated distance for the laser target to the current laser tracer reference point.
Parameter specific parameter: 0xFE03 indicates that the sensor can not sense the laser";
CM_ SG_ 2633939454 TripDriveFuelEconomy "Trip drive fuel economy is equal to the distance traveled by vehicle in the drive state (engine speed greater than zero, vehicle speed greater than or equal to 2 km/h, and neither the PTO or remote PTO governors are controlling engine power output) ...";
CM_ SG_ 2633939454 TripCruiseFuelUsed "Total fuel consumed while the engine is in the cruise hold state since the last trip reset.  If both cruise control and VSL (vehicle speed limiter) are commanding the same amount of fuel, the cruise control is deemed the active torque mode and fuel ...";
CM_ SG_ 2633939454 TripVehicleIdleFuelUsed "Total fuel consumed while neither the PTO or remote PTO governor is in the hold state, the engine speed is greater than zero, and vehicle speed is less than 2 km/h, since the last trip reset.
In marine applications, this parameter is defined as the ...";
CM_ SG_ 2633939454 TripPTOGovernorNonmovingFuelUsed "Total fuel consumed while either the PTO or remote PTO governors are in the hold state, the engine speed is greater than zero, and vehicle speed is less than 2 km/h, since the last trip reset.
NOTE—This parameter is intended for liquid fueled ...";
CM_ SG_ 2633939454 TripPTOGovernorMovingFuelUsed "Total fuel consumed while either the PTO or remote PTO governors are in the hold state, the engine speed is greater than zero, and vehicle speed is greater than or equal to 2 km/h, since the last trip reset.
NOTE—This parameter is intended for ...";
CM_ SG_ 2633939454 TripDriveFuelUsed "Total fuel consumed while the engine speed is greater than zero, vehicle speed is greater than or equal to 2 km/h, and neither the PTO or the remote PTO is controlling the engine power output, since the last trip reset.
NOTE—This parameter is ...";
CM_ SG_ 2365486334 BldeHeightSetPointHighResolution "High resolution for the laser guided blade set point.  The high resolution required for more accurate control and 'accurate' unit conversions.
Negative values are below grade, positive values are above grade, zero is on grade.";
CM_ SG_ 2365486334 ModifyLevelingSystemSetPoint "Used to control and coordinate the set point for the leveling system.
Operating Range: -3200 to +3200 mm, negative values are below current position, positive values are above current position, zero is no change.
Parameter specific parameter:
...";
CM_ SG_ 2364542462 SetElvtnSnsr2RefElvtn_5406 "Command from a display or other external device (i.e. remote switch) to the land leveling system controller instructing the controller to set the reference elvation based on data received from the corresponding land leveling sensor.
00 = Do not Set ...";
CM_ SG_ 2364542462 SetElvtnSnsr1RefElvtn_5405 "Command from a display or other external device (i.e. remote switch) to the land leveling system controller instructing the controller to set the reference elvation based on data received from the corresponding land leveling sensor.
00 = Do not Set ...";
CM_ SG_ 2364542462 SdShiftDesBladeOfsOprtrCtrl_3339 "This parameter indicates the side-shift blade control mode operator control state the user has set for the land leveling system.  When an implement moves in a side-shift direction, it moves from side to side, usually along its longitudinal axis.
...";
CM_ SG_ 2364542462 SdShiftBladeCtlModeOprtrCtl_3338 "This parameter indicates the side-shift offset operator control state the user has set for the land leveling system. When an implement moves in a side-shift direction, it moves from side to side, usually along its longitudinal axis. The desired ...";
CM_ SG_ 2364542462 RiDesBladeOfsOperatorCtl_3337 "This parameter indicates the right blade offset operator control state the user has set for the land leveling system.  The right desired blade offset value is the offset measured from a given reference point to the bottom right edge of the blade ...";
CM_ SG_ 2364542462 LeDesBladeOfsOperatorCtl_3336 "This parameter indicates the left blade offset operator control state the user has set for the land leveling system.  The left desired blade offset value is the offset measured from a given reference point to the bottom left edge of the blade. This ...";
CM_ SG_ 2364542462 RiBladeCtlModeOperatorCtl_3335 "This parameter indicates the right blade control mode operator control state the user has set for the land leveling system.  The operator control value directly relates to the current operator control state correlating to the left edge of the blade ...";
CM_ SG_ 2364542462 LeBladeCtlModeOperatorCtl_3334 "This parameter indicates the left blade control mode operator control state the user has set for the land leveling system.  The operator control value directly relates to the current operator control state correlating to the left edge of the blade ...";
CM_ SG_ 2364542462 BladeAutoModeCmd_3158 "Allows other controllers to command to the primary control system what they think is the appropriate auto control mode to be engaged in, based on the information they have available to them.  When in automatic mode, the blade automatically adjusts ...";
CM_ SG_ 2364542462 DesiredGradeOffsetSwitch_3157 "Indicates the grade offset switch state the user has set for the land leveling system.  The desired grade offset value is the vertical offset measured from a given elevation reference point to the bottom edge of the blade.  This parameter is ...";
CM_ SG_ 2364542462 BladeCtrlModeSwitch_3156 "Indicates the blade control mode switch state the user has set for the land leveling system.  The switch value directly correlates to the current switch state, regardless of the switch being used.  This parameter is intended for use in systems using ...";
CM_ SG_ 2365486078 MastPos "Used to monitor the position of the sensor attached to the land leveling mast.";
CM_ SG_ 2633937918 FlexibleFuelPercentage "Measured signal that indicates the percentage of alcohol in the fuel currently being used.  0% means no alcohol in fuel, 100% means alcohol as fuel and nothing else.
EXAMPLE: If a Bi-fuel vehicle has less than 10% ethanol in the gasoline/petrol, ...";
CM_ SG_ 2633937918 TripAverageFuelRate "Average fuel rate, equal to trip fuel divided by trip time while the engine speed is above zero, since the last trip reset.  This includes idle, engine PTO governor (both moving and non-moving) and drive operation but excludes ignition-on time while ...";
CM_ SG_ 2633937918 TotalEngPTOGovernorFuelUsed "Total fuel used while the PTO or remote PTO governors are in the hold state and engine speed is above zero, over the life of the engine.
NOTE—This parameter is intended for liquid fueled engines.  See SPN 1030 for alternate resolution.";
CM_ SG_ 2566845182 EngThrottleValve2Pos "The sensed position feedback of the valve, coming from a second electrical actuator for a second throttle plate, used to regulate the supply of a fluid, usually air or fuel//air mixture.  0% represents no supply and 100% is full supply. SPN 51 is ...";
CM_ SG_ 2566845182 EngThrottleValve1Pos "The position of the valve used to regulate the supply of a fluid, usually air or fuel/air mixture, to an engine.  0% represents no supply and 100% is full supply.";
CM_ SG_ 2566845182 EngAverageFuelEconomy "Average of instantaneous fuel economy for that segment of vehicle operation of interest.";
CM_ SG_ 2566845182 EngInstantaneousFuelEconomy "Current fuel economy at current vehicle velocity.
0xFB00 = Infinite (for example, during engine motoring)";
CM_ SG_ 2566845182 EngFuelRate "Amount of fuel consumed by engine per unit of time.
NOTE - See SPN 1600 for alternate resolution.";
CM_ SG_ 2566842878 EngTotalFuelUsed "Accumulated amount of fuel used during vehicle operation.  See SPN 5054 for alternate resolution.";
CM_ SG_ 2566842878 EngTripFuel "Fuel consumed during all or part of a journey.  See SPN 5053 for alternate resolution.";
CM_ SG_ 2633883646 FrontWheelDriveActuatorStatus "Feedback on the front wheel drive actuator.
00 Front Wheel Drive Actuator not engaged
01 Front Wheel Drive Actuator engaged
10 Error
11 Not Available";
CM_ SG_ 2633880062 FMSstandardSWversionSupported "Information that identifies which issue level of the FMS-standard document the software included in the FMS gateway supports. Four bytes, representing xx.yy type revision level identification.
Information to be ASCII equivalent of the numeric ...";
CM_ SG_ 2633880062 FMSstandardRequestsSupported "Status signal which indicates if the FMS Vehicle Interface (FMS Gateway) will respond to requests from the FMS device for the PGNs listed in the FMS Interface Specification.
This mode is to support FMS  gateway devices that only operate in a ...";
CM_ SG_ 2633880062 FMSstandardDiagnosticsSupported "Status signal which indicates if the FMS Vehicle Interface (FMS Gateway) supports the handling of diagnostic messages from the vehicle network onto the FMS network.
The FMS gateway does NOT support the re-broadcast of diagnostics messages present ...";
CM_ SG_ 2566806526 DrverAlertnessWarningSystemState "Indicates the various system state in the driver alertness warning system. This signal can be used independent of the technology and ECU used to estimate the driver alertness condition.
000 = System installed but disabled
001 = Initializing
010 = ...";
CM_ SG_ 2566806526 DriverAlertnessLevel "Indicates the alertness level of the driver measured by the driver alertness warning system. 100 % means driver is fully attentive. This signal can be used independent of the technology and ECU used to estimate the driver alertness condition.";
CM_ SG_ 2566806526 LnDpartureIndicationEnableStatus "Indicates whether lane departure indication is active.
00 Lane Departure indication disabled
01 Lane Departure Indication enabled
10 Reserved
11 Not Used";
CM_ SG_ 2566806526 LaneTrackingStatusLeftSide "Indicates whether the left side is tracking lane.
00 Not Tracking Left side
01 Tracking Left side
10 Reserved
11 Don't care/Take no action";
CM_ SG_ 2566806526 LaneTrackingStatusRightSide "Indicates whether right side is tracking lane.
00 Not Tracking Right side
01 Tracking Right side
10 Reserved
11 Don't Care/take no action";
CM_ SG_ 2431649790 LaneDepartureImminentLeSide_1700 "Indicates departure imminent on left side of lane.
00 Not imminent
01 Imminent
10 Reserved
11 Not used";
CM_ SG_ 2431649790 LaneDepartureImminentRiSide_1701 "Indicates departure imminent on right side of lane.
00 Not imminent
01 Imminent
10 Reserved
11 Not Used";
CM_ SG_ 2431649790 LaneDepartureRight_3566 "Indicates that the middle of vehicle departs the lane on the right side. The parameter indicates that the vehicle is changing the lane to the right.
00   Middle of the vehicle does not depart the lane to the right side
01   Middle of the vehicle ...";
CM_ SG_ 2431649790 LaneDepartureLeft_3565 "Indicates that the middle of vehicle departs the lane on the left side. The parameter indicates that the vehicle is changing the lane to the left.
00   Middle of the vehicle does not depart the lane to the left side
01   Middle of the vehicle ...";
CM_ SG_ 2431649790 DriverAlertnessWarning_7473 "Indicates when a distracted driving condition is detected. This signal can be used independent of the technology and ECU used to estimate the distracted driver condition.
000 = No distracted driving condition detected
001 = Level 1 - Mild ...";
CM_ SG_ 2633929214 EngFuelLeakage2 "Status signal which indicates fuel leakage in the fuel rail of the engine. Location can be either before or after the fuel pump.
00 - no leakage detected
01 - leakage detected
10 - Error
11 - Not available";
CM_ SG_ 2633929214 EngFuelLeakage1 "Status signal which indicates fuel leakage in the fuel rail of the engine. Location can be either before or after the fuel pump.
00 - no leakage detected
01 - leakage detected
10 - Error
11 - Not available";
CM_ SG_ 2566831614 FanDriveBypassCmdStatus "Status of the Fan Drive Bypass Command as being commanded by the ECU.  The fan drive bypass diverts pump pressure away from the hydraulic motor to maintain the fan drive pressure.  0% is defined as no bypass (i.e. diverting no fan drive pressure) ...";
CM_ SG_ 2566831614 HydFanMotorPress "The hydraulic pressure used to drive the fan system, sensed before the hydraulic fan motor.";
CM_ SG_ 2566831614 FanSpeed "The speed of the fan associated with engine coolant system.";
CM_ SG_ 2566831614 FanDriveState "This parameter is used to indicate the current state or mode of operation by the fan drive.
0000 Fan off
0001 Engine system-General
0010 Excessive engine air temperature
0011 Excessive engine oil temperature
0100 Excessive engine coolant ...";
CM_ SG_ 2566831614 EstPercentFanSpeed "Estimated fan speed as a ratio of the fan drive (current speed) to the fully engaged fan drive (maximum fan speed).  A two state fan (off/on) will use 0% and 100% respectively.  A three state fan (off/intermediate/on) will use 0%, 50% and 100% ...";
CM_ SG_ 2566820094 EngTorqueLimit6AxleInput "Limit applied to the engine output torque based on the maximum allowable axle input torque.  Axle input torque is calculated as the current engine torque output multiplied by the transmission gear ratio.";
CM_ SG_ 2566820094 EngTorqueLimit5Switch "Limit applied to the engine output torque based on activation of an ECU switch input.";
CM_ SG_ 2566820094 EngTorqueLimit4Trans "Limit applied to the engine output torque during vehicle operation in transmission gear ratios numerically less than or equal to transmission gear ratio 3 (see SPN 1259).";
CM_ SG_ 2566820094 EngTorqueLimit3Trans "Limit applied to the engine output torque during vehicle operation in transmission gear ratios numerically less than or equal to transmission gear ratio 2 (see SPN 1257) and numerically greater than transmission gear ratio 3 (see.SPN 1259).  For ...";
CM_ SG_ 2566820094 TransGearRatio3 "Gear ratio value stored in the ECU that is used to define a range of transmission gears for which a limit is applied to the engine output torque.  Transmission gear ratio 3 should be the numerically highest transmission gear ratio breakpoint less ...";
CM_ SG_ 2566820094 EngTorqueLimit2Trans "Limit applied to the engine output torque during vehicle operation in transmission gear ratios numerically less than or equal to transmission gear ratio 1 (see SPN 1255) and numerically greater than transmission gear ratio 2 (see.SPN 1257).  For ...";
CM_ SG_ 2566820094 TransGearRatio2 "Gear ratio value stored in the ECU that is used to define a range of transmission gears for which a limit is applied to the engine output torque.  Transmission gear ratio 2 should be the numerically highest transmission gear ratio breakpoint less ...";
CM_ SG_ 2566820094 EngTorqueLimit1Trans "Limit applied to the engine output torque during vehicle operation in transmission gear ratios numerically greater than transmission gear ratio 1 (see SPN 1255).";
CM_ SG_ 2566820094 TransGearRatio1 "Gear ratio value stored in the ECU that is used to define a range of transmission gears for which a limit is applied to the engine output torque.  Transmission gear ratio 1 should be the numerically highest transmission gear ratio breakpoint that ...";
CM_ SG_ 2566820094 EngTorqueLimitFeature "Torque limit rating described in the current record.
000 Reserved
001 Highest torque rating
010 First torque rating
011 Previous torque rating (rating prior to the current rating)
100 Current torque rating
101-110 Reserved
111 Not available
...";
CM_ SG_ 2566820094 TorqueLimitingFeatureStatus "Status of an ECU feature which limits the torque output of the engine.
00 - Disabled
01 - Enabled
10 - Error
11 - Not available";
CM_ SG_ 2566820094 CalibRecordDurationTime "Duration in hours for which the engine operated in the conditions captured in the current record.";
CM_ SG_ 2566820094 CalibRecordStartYear "Calendar year timestamp when an ECU record was established.
NOTE - A value of 0 for the year identifies the year 1985; a value of 1 identifies 1986; etc.";
CM_ SG_ 2566820094 CalibRecordStartDay "Calendar day timestamp when an ECU record was established.
NOTE - A value of 0 for the date is null.  The values 1, 2, 3, and 4 are used to identify the first day of the month; 5, 6, 7, and 8 identify the second day of the month; etc.";
CM_ SG_ 2566820094 CalibRecordStartMonth "Calendar month timestamp when an ECU record was established.
NOTE - A value of 0 for the month is null.  The value 1 identifies January; 2 identifies February; etc.";
CM_ SG_ 2566820094 EngPeakTorque2 "Maximum torque output of the current ECU calibration when the engine operates on torque curve 2.  For calibrations that support two torque curves, this parameter shall be assigned the value of the higher curve.  For calibrations that support only ...";
CM_ SG_ 2566820094 EngPeakTorque1 "Maximum torque output of the current ECU calibration when the engine operates on torque curve 1.  For calibrations that support two torque curves, this parameter shall be assigned the value of the lower curve.  For calibrations that support only one ...";
CM_ SG_ 2566820094 EngPower "Advertised engine power capability.  Advertised power is what a customer will find on a sales sheet for an engine with a certain calibration.";
CM_ SG_ 2566820094 NumberOfEngTorqueHistoryRecords "Number of torque history records contained in the engine torque history PGN.  A value of 0 is broadcast if no torque history records are stored in the ECU.";
CM_ SG_ 2364542206 TransCluCnvrInpSpd_5052 "Rotational velocity of the input to a transmission's master clutch or torque converter. In most cases the rotational velocity will be the same as engine flywheel speed unless there is an intermediate device, such as a power divider, between the ...";
CM_ SG_ 2364542206 TransTorqueConverterRatio_3030 "Ratio of the transmissions torque converter output torque to torque converter input torque at current speed.
The ratio of 1.000 ( 03 E8 hex ) indicates torque converter lockup.
If the ratio is less than 1 and the ratio can not be properly ...";
CM_ SG_ 2566802174 TransAutoNeutralSt "Indicates the transmission response to a Neutral request from SPN 7695 [Transmission Auto-Neutral (Manual Return) Request] or other vehicle input configured for Auto-Neutral (Manual Return) functionality. The applicability of the states and state ...";
CM_ SG_ 2566802174 TransWarningIndicator "Signal from transmission indicating that some aspect of its operation is not functioning correctly, and as a result, transmission operation may be altered or restricted.  The indicator is typically a lamp.  Distinctions in meaning between the ...";
CM_ SG_ 2566802174 TrnsRverseGearShiftInhibitStatus "Reflects the status of transmission reverse inhibit activity in response to requests via SPN 4242 - Transmission Reverse Gear Shift Inhibit Request.  Typically broadcast by the transmission controller.
00 = Reverse gear shifts are currently allowed
...";
CM_ SG_ 2566802174 TransMode8Indicator "This state signal is the transmission’s indication that it is operating under transmission mode 8 (SPN 4249) as commanded via the TC1 message (PGN 256).  The definition of the transmission mode is left to the discretion of the transmission ...";
CM_ SG_ 2566802174 TransMode7Indicator "This state signal is the transmission’s indication that it is operating under transmission mode 7 (SPN 4248) as commanded via the TC1 message (PGN 256).  The definition of the transmission mode is left to the discretion of the transmission ...";
CM_ SG_ 2566802174 TransMode6Indicator "This state signal is the transmission’s indication that it is operating under transmission mode 6 (SPN 4247) as commanded via the TC1 message (PGN 256).  The definition of the transmission mode is left to the discretion of the transmission ...";
CM_ SG_ 2566802174 TransMode5Indicator "This state signal is the transmission’s indication that it is operating under transmission mode 5 (SPN 4246) as commanded via the TC1 message (PGN 256).  The definition of the transmission mode is left to the discretion of the transmission ...";
CM_ SG_ 2566802174 TransRequestedGearFeedback "Feedback of the SPN 525 Transmission Requested Gear input as received from the shift selector, ABS or engine via PGN 256, Transmission Control 1 (TC1) or other transmission selector input.  Scaling, values and parameter specific indicators are ...";
CM_ SG_ 2566802174 TransMode1Indicator "This state signal is the transmission’s indication that it is operating under transmission mode 1 (SPN 1852) as commanded via the TC1 message (PGN 256).  The definition of the transmission mode is left to the discretion of the transmission ...";
CM_ SG_ 2566802174 TransMode2Indicator "This state signal is the transmission’s indication that it is operating under transmission mode 2 (SPN 1853) as commanded via the TC1 message (PGN 256).  The definition of the transmission mode is left to the discretion of the transmission ...";
CM_ SG_ 2566802174 TransMode3Indicator "This state signal is the transmission’s indication that it is operating under transmission mode 3 (SPN 1854) as commanded via the TC1 message (PGN 256).  The definition of the transmission mode is left to the discretion of the transmission ...";
CM_ SG_ 2566802174 TransMode4Indicator "This state signal is the transmission’s indication that it is operating under transmission mode 4 (SPN 1855) as commanded via the TC1 message (PGN 256).  The definition of the transmission mode is left to the discretion of the transmission ...";
CM_ SG_ 2566802174 TransShiftInhibitIndicator "State signal indicating a transmission request for the Shift Inhibit Indicator to be active or inactive. The shift inhibit indicator can be of lamp or text form, located on (but not limited to) the shift console, instrument cluster, or cab display ...";
CM_ SG_ 2566802174 TransEngCrankEnable "State signal from the transmission indicating if the transmission’s status is such that engine cranking is allowed (i.e.  at a minimum, transmission is in neutral and the driveline is disengaged).  As sender of this information, the transmission is ...";
CM_ SG_ 2566802174 ActiveShiftConsoleIndicator "Signal from transmission control unit indicating which shift console (primary or secondary) it currently considers as the active shift selector input.
00        Primary shift console is active
01        Secondary shift console is active
10 ...";
CM_ SG_ 2566802174 TransReadyForBrakeRelease "This parameter indicates that enough torque / motive force is available at the transmission output shaft to release all the brakes without a risk of unintentional movement in the opposite direction.
00 - Transmission Not Ready for Brake Release
01 ...";
CM_ SG_ 2566802174 TrnsRqstedRangeDisplayFlashState "State signal indicating a transmission request for the display of the Transmission Requested Range parameter (SPN 162) to flash or not to flash. The ‘Transmission Requested Range Display Flash State’ indicator can be utilized by (but not limited to) ...";
CM_ SG_ 2566802174 TrnsRqstedRangeDisplayBlankState "State signal indicating a transmission request for the display of the Transmission Requested Range parameter (SPN162) to be blanked or not blanked.  The ‘Transmission Requested Range Display Blank State’ indicator can be utilized by (but not limited ...";
CM_ SG_ 2566802174 TransServiceIndicator "Signal from transmission indicating that some aspect of the gearbox requires servicing, such as the oil, filter, clutch(es) or other component.
00  Transmission Service Indicator is off
01  Transmission Service Indicator is on continuously
10 ...";
CM_ SG_ 2566802174 TransAirSupplyPressIndicator "Indicates whether transmission air supply is sufficient
000   Normal Pressure Range - The transmission supply air pressure is within the normal operational range.
001   Low pressure - The transmission supply air pressure is within a range that may ...";
CM_ SG_ 2566802174 TransMode10Indicator "Indicates that the transmission is operating under transmission mode 10 (SPN 6570) as commanded via the TC2 message (PGN 3328). The definition of the transmission mode is left to the discretion of the transmission manufacturer.
00 Transmission Mode ...";
CM_ SG_ 2566802174 TransMode9Indicator "Indicates that the transmission is operating under transmission mode 9 (SPN 6569) as commanded via the TC2 message (PGN 3328). The definition of the transmission mode is left to the discretion of the transmission manufacturer.
00 Transmission Mode ...";
CM_ SG_ 2566802174 TrnsCrrentRangeDisplayBlankState "State signal indicating a transmission request for the display of the Transmission Current Range parameter (SPN 163) to be blanked or not blanked.  The 'Transmission Current Range Display Blank State' indicator can be utilized by (but not limited ...";
CM_ SG_ 2633935870 ClutchLifeRemaining "Signal which indicates the actual clutch life remaining in percent. One hundred percent means the clutch is brand new and zero percent means the clutch is at the end of its life.";
CM_ SG_ 2633935870 LowestPossibleGear "The transmission calculates this gear continuously.  Together with the highest possible gear (see SPN 1115), it enables a management computer to know the exact range of available gears.";
CM_ SG_ 2633935870 HighestPossibleGear "The transmission calculates this gear continuously.  Together with the lowest possible gear (see  SPN 1114), it enables a management computer to know the exact range of available gears.";
CM_ SG_ 2633935870 RecommendedGear "The transmission calculates this gear continuously.  In dangerous situations this gear may be selected to gain back vehicle control.";
CM_ SG_ 2633942014 TransForwardDirectionSwitch "Identifies the status of the switch that indicates forward direction.
00 - Off
01 - On
10 - Error
11 - Not available";
CM_ SG_ 2633942014 TransNeutralSwitch "Identifies the status of the switch that indicates neutral.
00 - Off
01 - On
10 - Error
11 - Not available";
CM_ SG_ 2633942014 TransReverseDirectionSwitch "Identifies the status of the switch that indicates reverse direction.
00 - Off
01 - On
10 - Error
11 - Not available";
CM_ SG_ 2633942014 TransLowRangeSenseSwitch "Identifies the status of the switch that represents low range.
00 - Off
01 - On
10 - Error
11 - Not available";
CM_ SG_ 2633942014 TransHighRangeSenseSwitch "Identifies the status of the switch that represents high range.
00 - Off
01 - On
10 - Error
11 - Not available";
CM_ SG_ 2633942526 TransSynchronizerBrakeValue "The current modulated value for the air supply to the synchronizer brake.";
CM_ SG_ 2633942526 TransSynchronizerClutchValue "The current modulated value for the air supply to the synchronizer clutch.";

BA_DEF_ BO_ "GenMsgCycleTime" INT 0 3600000;
BA_DEF_ BO_ "GenMsgCycleTimeFast" INT 0 3600000;
BA_DEF_ BO_ "GenMsgDelayTime" INT 0 1000;
BA_DEF_ BO_ "GenMsgILSupport" ENUM  "No","Yes";
BA_DEF_ BO_ "GenMsgRequestable" INT 0 1;
BA_DEF_ BO_ "GenMsgSendType" ENUM  "cyclic","spontaneous","cyclicIfActive","spontaneousWithDelay","cyclicAndSpontaneous","cyclicAndSpontaneousWithDelay","spontaneousWithRepetition","cyclicIfActiveAndSpontaneousWD";
BA_DEF_ BO_ "GenMsgStartDelayTime" INT 0 100000;
BA_DEF_ BO_ "J1939PGNameSecSrc0Dest3" STRING;
BA_DEF_ BO_ "J1939PGPrio" INT 0 7;
BA_DEF_ BO_ "J1939PGPrioSrc0Dest3" INT 0 7;
BA_DEF_ BO_ "J1939PGRelationDest3Src0" INT 0 254;
BA_DEF_ BO_ "J1939PGRelationSrc0Dest3" INT 0 254;
BA_DEF_ BO_ "J1939PGRepCycleSrc0Dest3" INT -1 65535;
BA_DEF_ BO_ "J1939PGRepTypeSrc0Dest3" INT 0 4;
BA_DEF_ BO_ "J1939PGRepetitionCycle" INT 0 65535;
BA_DEF_ BO_ "J1939PGRepetitionType" ENUM  "always","when active","on request";
BA_DEF_ BO_ "J1939PGtoECUSrc0Dest3" INT 0 254;
BA_DEF_ BO_ "J1939PGtoWSMSrc0Dest3" INT 0 254;
BA_DEF_ BO_ "TpJ1939VarDlc" ENUM  "No","Yes";
BA_DEF_ BO_ "VFrameFormat" ENUM  "StandardCAN","ExtendedCAN","reserved","J1939PG";
BA_DEF_ SG_ "GenSigEVName" STRING;
BA_DEF_ SG_ "GenSigILSupport" ENUM  "No","Yes";
BA_DEF_ SG_ "GenSigSendType" ENUM  "Cyclic","OnWrite","OnWriteWithRepetition","OnChange","OnChangeWithRepetition","IfActive","IfActiveWithRepetition","NoSigSendType";
BA_DEF_ SG_ "GenSigStartValue" INT 0 10000;
BA_DEF_ SG_ "SPN" INT 0 524287;
BA_DEF_ SG_ "SigType" ENUM  "Default","Range","RangeSigned","ASCII","Discrete","Control","ReferencePGN","DTC","StringDelimiter","StringLength","StringLengthControl","MessageCounter","MessageChecksum";
BA_DEF_ SG_ "SystemSignalLongSymbol" STRING;
BA_DEF_DEF_ "GenMsgCycleTime" 0;
BA_DEF_DEF_ "GenMsgCycleTimeFast" 0;
BA_DEF_DEF_ "GenMsgDelayTime" 0;
BA_DEF_DEF_ "GenMsgILSupport" "Yes";
BA_DEF_DEF_ "GenMsgRequestable" 1;
BA_DEF_DEF_ "GenMsgSendType" "noMsgSendType";
BA_DEF_DEF_ "GenMsgStartDelayTime" 0;
BA_DEF_DEF_ "GenSigEVName" "Env@Nodename_@Signame";
BA_DEF_DEF_ "GenSigILSupport" "Yes";
BA_DEF_DEF_ "GenSigSendType" "NoSigSendType";
BA_DEF_DEF_ "GenSigStartValue" 0;
BA_DEF_DEF_ "J1939PGNameSecSrc0Dest3" "(null)";
BA_DEF_DEF_ "J1939PGPrio" 6;
BA_DEF_DEF_ "J1939PGPrioSrc0Dest3" 6;
BA_DEF_DEF_ "J1939PGRelationDest3Src0" 254;
BA_DEF_DEF_ "J1939PGRelationSrc0Dest3" 254;
BA_DEF_DEF_ "J1939PGRepCycleSrc0Dest3" -1;
BA_DEF_DEF_ "J1939PGRepTypeSrc0Dest3" 3;
BA_DEF_DEF_ "J1939PGRepetitionCycle" 100;
BA_DEF_DEF_ "J1939PGRepetitionType" "always";
BA_DEF_DEF_ "J1939PGtoECUSrc0Dest3" -1;
BA_DEF_DEF_ "J1939PGtoWSMSrc0Dest3" -1;
BA_DEF_DEF_ "SPN" 0;
BA_DEF_DEF_ "SigType" "Default";
BA_DEF_DEF_ "SystemSignalLongSymbol" "";
BA_DEF_DEF_ "TpJ1939VarDlc" "No";
BA_DEF_DEF_ "VFrameFormat" "J1939PG";
BA_ "GenMsgCycleTime" BO_ 2348941054 50;
BA_ "GenMsgSendType" BO_ 2348941054 7;
BA_ "GenMsgCycleTime" BO_ 2566839806 1000;
BA_ "GenMsgSendType" BO_ 2566839806 0;
BA_ "GenMsgCycleTime" BO_ 2566775550 1000;
BA_ "GenMsgSendType" BO_ 2566775550 8;
BA_ "GenMsgCycleTime" BO_ 2566819838 1000;
BA_ "GenMsgSendType" BO_ 2566819838 0;
BA_ "TpJ1939VarDlc" BO_ 2566839038 1;
BA_ "GenMsgCycleTime" BO_ 2566841598 1000;
BA_ "GenMsgSendType" BO_ 2566841598 0;
BA_ "GenMsgCycleTime" BO_ 2566804478 5000;
BA_ "GenMsgSendType" BO_ 2566804478 0;
BA_ "GenMsgCycleTime" BO_ 2566847486 1000;
BA_ "GenMsgSendType" BO_ 2566847486 0;
BA_ "GenMsgCycleTime" BO_ 2566840830 5000;
BA_ "GenMsgDelayTime" BO_ 2566840830 500;
BA_ "GenMsgSendType" BO_ 2566840830 0;
BA_ "GenMsgCycleTime" BO_ 2566844670 100;
BA_ "GenMsgSendType" BO_ 2566844670 0;
BA_ "GenMsgCycleTime" BO_ 2566770174 200;
BA_ "GenMsgSendType" BO_ 2566770174 0;
BA_ "GenMsgCycleTime" BO_ 2566769662 500;
BA_ "GenMsgSendType" BO_ 2566769662 0;
BA_ "GenMsgCycleTime" BO_ 2566768638 5000;
BA_ "GenMsgSendType" BO_ 2566768638 0;
BA_ "GenMsgCycleTime" BO_ 2365443326 1000;
BA_ "GenMsgDelayTime" BO_ 2365443326 100;
BA_ "GenMsgSendType" BO_ 2365443326 0;
BA_ "GenMsgCycleTime" BO_ 2566776318 1000;
BA_ "GenMsgSendType" BO_ 2566776318 0;
BA_ "GenMsgCycleTime" BO_ 2566802686 500;
BA_ "GenMsgDelayTime" BO_ 2566802686 100;
BA_ "GenMsgSendType" BO_ 2566802686 0;
BA_ "GenMsgCycleTime" BO_ 2566774014 1000;
BA_ "GenMsgSendType" BO_ 2566774014 0;
BA_ "GenMsgCycleTime" BO_ 2566823166 1000;
BA_ "GenMsgSendType" BO_ 2566823166 0;
BA_ "GenMsgCycleTime" BO_ 2566823422 1000;
BA_ "GenMsgSendType" BO_ 2566823422 0;
BA_ "GenMsgCycleTime" BO_ 2566823678 1000;
BA_ "GenMsgSendType" BO_ 2566823678 0;
BA_ "GenMsgCycleTime" BO_ 2432595710 100;
BA_ "GenMsgSendType" BO_ 2432595710 0;
BA_ "GenMsgCycleTime" BO_ 2365486590 50;
BA_ "GenMsgSendType" BO_ 2365486590 0;
BA_ "GenMsgCycleTime" BO_ 2365485566 50;
BA_ "GenMsgSendType" BO_ 2365485566 0;
BA_ "GenMsgCycleTime" BO_ 2365486334 50;
BA_ "GenMsgSendType" BO_ 2365486334 0;
BA_ "GenMsgCycleTime" BO_ 2364542462 100;
BA_ "GenMsgSendType" BO_ 2364542462 0;
BA_ "GenMsgCycleTime" BO_ 2365486078 50;
BA_ "GenMsgSendType" BO_ 2365486078 0;
BA_ "GenMsgCycleTime" BO_ 2566845182 100;
BA_ "GenMsgSendType" BO_ 2566845182 0;
BA_ "GenMsgCycleTime" BO_ 2633883646 5000;
BA_ "GenMsgSendType" BO_ 2633883646 0;
BA_ "GenMsgCycleTime" BO_ 2633880062 10000;
BA_ "GenMsgSendType" BO_ 2633880062 0;
BA_ "GenMsgCycleTime" BO_ 2566806526 100;
BA_ "GenMsgSendType" BO_ 2566806526 0;
BA_ "GenMsgCycleTime" BO_ 2431649790 50;
BA_ "GenMsgSendType" BO_ 2431649790 8;
BA_ "GenMsgCycleTime" BO_ 2633929214 1000;
BA_ "GenMsgSendType" BO_ 2633929214 0;
BA_ "GenMsgCycleTime" BO_ 2566831614 1000;
BA_ "GenMsgSendType" BO_ 2566831614 0;
BA_ "GenMsgCycleTime" BO_ 2364542206 20;
BA_ "GenMsgSendType" BO_ 2364542206 0;
BA_ "GenMsgCycleTime" BO_ 2566802174 100;
BA_ "GenMsgSendType" BO_ 2566802174 0;
BA_ "SPN" SG_ 2348941054 AutoNeutralReq_7695 7695;
BA_ "SigType" SG_ 2348941054 AutoNeutralReq_7695 5;
BA_ "SPN" SG_ 2348941054 TransMode8_4249 4249;
BA_ "SigType" SG_ 2348941054 TransMode8_4249 5;
BA_ "SPN" SG_ 2348941054 TransMode7_4248 4248;
BA_ "SigType" SG_ 2348941054 TransMode7_4248 5;
BA_ "SPN" SG_ 2348941054 TransMode6_4247 4247;
BA_ "SigType" SG_ 2348941054 TransMode6_4247 5;
BA_ "SPN" SG_ 2348941054 TransMode5_4246 4246;
BA_ "SigType" SG_ 2348941054 TransMode5_4246 5;
BA_ "SPN" SG_ 2348941054 TrnsShftSelectorDMS_2985 2985;
BA_ "SigType" SG_ 2348941054 TrnsShftSelectorDMS_2985 4;
BA_ "SPN" SG_ 2348941054 TransRequestedLaunchGear_4255 4255;
BA_ "SPN" SG_ 2348941054 TransMode4_1855 1855;
BA_ "SigType" SG_ 2348941054 TransMode4_1855 5;
BA_ "SPN" SG_ 2348941054 TransMode3_1854 1854;
BA_ "SigType" SG_ 2348941054 TransMode3_1854 5;
BA_ "SPN" SG_ 2348941054 TransMode2_1853 1853;
BA_ "SigType" SG_ 2348941054 TransMode2_1853 5;
BA_ "SPN" SG_ 2348941054 TransMode1_1852 1852;
BA_ "SigType" SG_ 2348941054 TransMode1_1852 5;
BA_ "SPN" SG_ 2348941054 TransLoadReductionInhibitRq_5762 5762;
BA_ "SigType" SG_ 2348941054 TransLoadReductionInhibitRq_5762 5;
BA_ "SPN" SG_ 2348941054 DisengDiffLockRqCentralRear_691 691;
BA_ "SigType" SG_ 2348941054 DisengDiffLockRqCentralRear_691 5;
BA_ "SPN" SG_ 2348941054 DisengDiffLockRqCentralFront_690 690;
BA_ "SigType" SG_ 2348941054 DisengDiffLockRqCentralFront_690 5;
BA_ "SPN" SG_ 2348941054 DisengageDiffLockRqCentral_689 689;
BA_ "SigType" SG_ 2348941054 DisengageDiffLockRqCentral_689 5;
BA_ "SPN" SG_ 2348941054 DisengageDiffLockRqRearAxle2_688 688;
BA_ "SigType" SG_ 2348941054 DisengageDiffLockRqRearAxle2_688 5;
BA_ "SPN" SG_ 2348941054 DisengageDiffLockRqRearAxle1_687 687;
BA_ "SigType" SG_ 2348941054 DisengageDiffLockRqRearAxle1_687 5;
BA_ "SPN" SG_ 2348941054 DisengDiffLockRqFrontAxle2_686 686;
BA_ "SigType" SG_ 2348941054 DisengDiffLockRqFrontAxle2_686 5;
BA_ "SPN" SG_ 2348941054 DisengDiffLockRqFrontAxle1_685 685;
BA_ "SigType" SG_ 2348941054 DisengDiffLockRqFrontAxle1_685 5;
BA_ "GenSigStartValue" SG_ 2348941054 TransRequestedGear_525 61;
BA_ "SPN" SG_ 2348941054 TransRequestedGear_525 525;
BA_ "SigType" SG_ 2348941054 TransRequestedGear_525 1;
BA_ "SPN" SG_ 2348941054 RequestedPercentClutchSlip_684 684;
BA_ "SigType" SG_ 2348941054 RequestedPercentClutchSlip_684 1;
BA_ "SPN" SG_ 2348941054 TransRevGearShiftInhibitRq_4242 4242;
BA_ "SigType" SG_ 2348941054 TransRevGearShiftInhibitRq_4242 5;
BA_ "SPN" SG_ 2348941054 DisengageDrivelineRq_683 683;
BA_ "SigType" SG_ 2348941054 DisengageDrivelineRq_683 5;
BA_ "SPN" SG_ 2348941054 TrnsTrqeConvLockupDisableRq_682 682;
BA_ "SigType" SG_ 2348941054 TrnsTrqeConvLockupDisableRq_682 5;
BA_ "SPN" SG_ 2348941054 TransGearShiftInhibitRq_681 681;
BA_ "SigType" SG_ 2348941054 TransGearShiftInhibitRq_681 5;
BA_ "SPN" SG_ 2566839806 EngTurboOilLevelSwitch 1665;
BA_ "SigType" SG_ 2566839806 EngTurboOilLevelSwitch 4;
BA_ "SPN" SG_ 2566839806 EngTurbo1Speed 103;
BA_ "SigType" SG_ 2566839806 EngTurbo1Speed 1;
BA_ "SPN" SG_ 2566839806 EngTurboLubeOilPress1 104;
BA_ "SigType" SG_ 2566839806 EngTurboLubeOilPress1 1;
BA_ "SPN" SG_ 2566839806 EngTurboDiffSpeed 5980;
BA_ "SigType" SG_ 2566839806 EngTurboDiffSpeed 1;
BA_ "SPN" SG_ 2633911806 EngTotalAverageFuelEconomy 1835;
BA_ "SigType" SG_ 2633911806 EngTotalAverageFuelEconomy 1;
BA_ "SPN" SG_ 2633911806 EngTotalAverageFuelRate 1834;
BA_ "SigType" SG_ 2633911806 EngTotalAverageFuelRate 1;
BA_ "SPN" SG_ 2566775550 PwertrainCircuitAirSupplyPressRq 6306;
BA_ "SigType" SG_ 2566775550 PwertrainCircuitAirSupplyPressRq 1;
BA_ "SPN" SG_ 2566775550 AirSuspensionSupplyPressRq 2608;
BA_ "SigType" SG_ 2566775550 AirSuspensionSupplyPressRq 1;
BA_ "SPN" SG_ 2566775550 AuxEquipmentSupplyPressRq 2607;
BA_ "SigType" SG_ 2566775550 AuxEquipmentSupplyPressRq 1;
BA_ "SPN" SG_ 2566775550 ServiceBrakeAirPressRqCircuit2 2606;
BA_ "SigType" SG_ 2566775550 ServiceBrakeAirPressRqCircuit2 1;
BA_ "SPN" SG_ 2566775550 ServiceBrakeAirPressRqCircuit1 2605;
BA_ "SigType" SG_ 2566775550 ServiceBrakeAirPressRqCircuit1 1;
BA_ "SPN" SG_ 2566775550 ParkingAnd_orTrailerAirPressRq 2604;
BA_ "SigType" SG_ 2566775550 ParkingAnd_orTrailerAirPressRq 1;
BA_ "SPN" SG_ 2566775550 PneumaticSupplyPressRq 2603;
BA_ "SigType" SG_ 2566775550 PneumaticSupplyPressRq 1;
BA_ "SPN" SG_ 2566819838 EngExtlShutdownAirSupplyPress 1320;
BA_ "SigType" SG_ 2566819838 EngExtlShutdownAirSupplyPress 1;
BA_ "SPN" SG_ 2566839038 NmbrOfSftwreIdentificationFields 965;
BA_ "SigType" SG_ 2566839038 NmbrOfSftwreIdentificationFields 1;
BA_ "SPN" SG_ 2566839038 SoftwareIdentification 234;
BA_ "SigType" SG_ 2566839038 SoftwareIdentification 8;
BA_ "SPN" SG_ 2566841598 ClntLvlEngPrtctionShutdownStatus 5566;
BA_ "SigType" SG_ 2566841598 ClntLvlEngPrtctionShutdownStatus 5;
BA_ "SPN" SG_ 2566841598 PTOShutdownHasShutdownEng 5404;
BA_ "SigType" SG_ 2566841598 PTOShutdownHasShutdownEng 5;
BA_ "SPN" SG_ 2566841598 EngAirShutoffStatus 3667;
BA_ "SigType" SG_ 2566841598 EngAirShutoffStatus 5;
BA_ "SPN" SG_ 2566841598 EngOverspeedTest 2812;
BA_ "SigType" SG_ 2566841598 EngOverspeedTest 4;
BA_ "SPN" SG_ 2566841598 EngAirShutoffCmdStatus 2813;
BA_ "SigType" SG_ 2566841598 EngAirShutoffCmdStatus 5;
BA_ "SPN" SG_ 2566841598 EngAlarmOutputCmdStatus 2814;
BA_ "SigType" SG_ 2566841598 EngAlarmOutputCmdStatus 5;
BA_ "SPN" SG_ 2566841598 EngAlarmAcknowledge 2815;
BA_ "SigType" SG_ 2566841598 EngAlarmAcknowledge 4;
BA_ "SPN" SG_ 2566841598 EngProtectionSystemConfig 1111;
BA_ "SigType" SG_ 2566841598 EngProtectionSystemConfig 5;
BA_ "SPN" SG_ 2566841598 EngProtectionSystemTimerState 1107;
BA_ "SigType" SG_ 2566841598 EngProtectionSystemTimerState 5;
BA_ "SPN" SG_ 2566841598 EngProtectionSystemTimerOverride 1108;
BA_ "SigType" SG_ 2566841598 EngProtectionSystemTimerOverride 5;
BA_ "SPN" SG_ 2566841598 EngPrtctnSystmApprachingShutdown 1109;
BA_ "SigType" SG_ 2566841598 EngPrtctnSystmApprachingShutdown 5;
BA_ "SPN" SG_ 2566841598 EngPrtectionSystemHasShutdownEng 1110;
BA_ "SigType" SG_ 2566841598 EngPrtectionSystemHasShutdownEng 5;
BA_ "SPN" SG_ 2566841598 EngWaitToStartLamp 1081;
BA_ "SigType" SG_ 2566841598 EngWaitToStartLamp 5;
BA_ "SPN" SG_ 2566841598 RefrigerantHighPressSwitch 605;
BA_ "SigType" SG_ 2566841598 RefrigerantHighPressSwitch 4;
BA_ "SPN" SG_ 2566841598 RefrigerantLowPressSwitch 875;
BA_ "SigType" SG_ 2566841598 RefrigerantLowPressSwitch 4;
BA_ "SPN" SG_ 2566841598 A_CHighPressFanSwitch 985;
BA_ "SigType" SG_ 2566841598 A_CHighPressFanSwitch 4;
BA_ "SPN" SG_ 2566841598 EngIdleShutdownTimerFunction 591;
BA_ "SigType" SG_ 2566841598 EngIdleShutdownTimerFunction 4;
BA_ "SPN" SG_ 2566841598 EngIdleShutdownTimerState 590;
BA_ "SigType" SG_ 2566841598 EngIdleShutdownTimerState 5;
BA_ "SPN" SG_ 2566841598 EngIdleShutdownTimerOverride 592;
BA_ "SigType" SG_ 2566841598 EngIdleShutdownTimerOverride 5;
BA_ "SPN" SG_ 2566841598 EngIdleShutdownDriverAlertMode 594;
BA_ "SigType" SG_ 2566841598 EngIdleShutdownDriverAlertMode 5;
BA_ "SPN" SG_ 2566841598 EngIdleShutdownHasShutdownEng 593;
BA_ "SigType" SG_ 2566841598 EngIdleShutdownHasShutdownEng 5;
BA_ "SPN" SG_ 2566786302 ArbitraryAddressCapable 2844;
BA_ "SPN" SG_ 2566786302 IndustryGroup 2846;
BA_ "SPN" SG_ 2566786302 VehicleSystemInstance 2843;
BA_ "SPN" SG_ 2566786302 ECUInstance 2840;
BA_ "SPN" SG_ 2566786302 FunctionInstance 2839;
BA_ "SPN" SG_ 2566786302 Function 2841;
BA_ "SPN" SG_ 2566786302 ManufacturerCode 2838;
BA_ "SigType" SG_ 2566786302 ManufacturerCode 1;
BA_ "SPN" SG_ 2566786302 IdentityNumber 2837;
BA_ "SPN" SG_ 2566832382 SrviceDelay_OperationalTimeBased 916;
BA_ "SigType" SG_ 2566832382 SrviceDelay_OperationalTimeBased 1;
BA_ "SPN" SG_ 2566832382 ServiceComponentIdentificatio913 913;
BA_ "SigType" SG_ 2566832382 ServiceComponentIdentificatio913 1;
BA_ "SPN" SG_ 2566832382 ServiceDelay_CalendarTimeBased 915;
BA_ "SigType" SG_ 2566832382 ServiceDelay_CalendarTimeBased 1;
BA_ "SPN" SG_ 2566832382 ServiceComponentIdentificatio912 912;
BA_ "SigType" SG_ 2566832382 ServiceComponentIdentificatio912 1;
BA_ "SPN" SG_ 2566832382 ServiceDistance 914;
BA_ "SigType" SG_ 2566832382 ServiceDistance 1;
BA_ "SPN" SG_ 2566832382 ServiceComponentIdentification 911;
BA_ "SigType" SG_ 2566832382 ServiceComponentIdentification 1;
BA_ "SPN" SG_ 2633928446 TimeSinceLastService 1350;
BA_ "SigType" SG_ 2633928446 TimeSinceLastService 1;
BA_ "SPN" SG_ 2633928446 ServiceComponentIdentification 1379;
BA_ "SigType" SG_ 2633928446 ServiceComponentIdentification 1;
BA_ "SPN" SG_ 2566804478 MinContinuousRetarderTorque 1783;
BA_ "SigType" SG_ 2566804478 MinContinuousRetarderTorque 1;
BA_ "SPN" SG_ 2566804478 MaxContinuousRetarderTorque 1782;
BA_ "SigType" SG_ 2566804478 MaxContinuousRetarderTorque 1;
BA_ "SPN" SG_ 2566804478 MinContinuousRetarderSpeed 1781;
BA_ "SigType" SG_ 2566804478 MinContinuousRetarderSpeed 1;
BA_ "SPN" SG_ 2566804478 MaxContinuousRetarderSpeed 1780;
BA_ "SigType" SG_ 2566804478 MaxContinuousRetarderSpeed 1;
BA_ "SPN" SG_ 2566804478 HghLmtThrshldFrMnCntnsTrqFrmRtrd 1779;
BA_ "SigType" SG_ 2566804478 HghLmtThrshldFrMnCntnsTrqFrmRtrd 1;
BA_ "SPN" SG_ 2566804478 LwLmtThrshldFrMxTrqeFromRetarder 1778;
BA_ "SigType" SG_ 2566804478 LwLmtThrshldFrMxTrqeFromRetarder 1;
BA_ "SPN" SG_ 2566804478 HghLmtThrshldFrMnCntnsRPMFrmRtrd 1777;
BA_ "SigType" SG_ 2566804478 HghLmtThrshldFrMnCntnsRPMFrmRtrd 1;
BA_ "SPN" SG_ 2566804478 LwLmtThrshldFrMaxRPMFromRetarder 1776;
BA_ "SigType" SG_ 2566804478 LwLmtThrshldFrMaxRPMFromRetarder 1;
BA_ "SPN" SG_ 2566847486 DrvlineRetarderOverheatIndicator 5346;
BA_ "SigType" SG_ 2566847486 DrvlineRetarderOverheatIndicator 5;
BA_ "SPN" SG_ 2566847486 RetarderCoolantOutletTemp 5656;
BA_ "SigType" SG_ 2566847486 RetarderCoolantOutletTemp 1;
BA_ "SPN" SG_ 2566847486 HydRetarderOilTemp 120;
BA_ "SigType" SG_ 2566847486 HydRetarderOilTemp 1;
BA_ "SPN" SG_ 2566847486 HydRetarderPress 119;
BA_ "SigType" SG_ 2566847486 HydRetarderPress 1;
BA_ "SPN" SG_ 2631859966 SteerStraightAheadPosReset_3600 3600;
BA_ "SigType" SG_ 2631859966 SteerStraightAheadPosReset_3600 5;
BA_ "SPN" SG_ 2631859966 EngBuildHoursReset_1211 1211;
BA_ "SigType" SG_ 2631859966 EngBuildHoursReset_1211 5;
BA_ "SPN" SG_ 2631859966 EngIgntCtrlMntnHoursRst_6219 6219;
BA_ "SigType" SG_ 2631859966 EngIgntCtrlMntnHoursRst_6219 4;
BA_ "SPN" SG_ 2631859966 EngSprkPlgScndUTrackingRst_6218 6218;
BA_ "SigType" SG_ 2631859966 EngSprkPlgScndUTrackingRst_6218 5;
BA_ "SPN" SG_ 2631859966 SrvCptIdentification_1584 1584;
BA_ "SigType" SG_ 2631859966 SrvCptIdentification_1584 1;
BA_ "SPN" SG_ 2631859966 TripGroup2Proprietary_989 989;
BA_ "SigType" SG_ 2631859966 TripGroup2Proprietary_989 5;
BA_ "SPN" SG_ 2631859966 TireSensorInformation_6986 6986;
BA_ "SigType" SG_ 2631859966 TireSensorInformation_6986 4;
BA_ "SPN" SG_ 2631859966 TireConfigInformation_6985 6985;
BA_ "SigType" SG_ 2631859966 TireConfigInformation_6985 4;
BA_ "SPN" SG_ 2631859966 BinLiftCountReset_6898 6898;
BA_ "SigType" SG_ 2631859966 BinLiftCountReset_6898 4;
BA_ "SPN" SG_ 2631859966 TripGroup1_988 988;
BA_ "SigType" SG_ 2631859966 TripGroup1_988 5;
BA_ "SPN" SG_ 2566840830 PercentTorqueAtPeakTorquePoint5 555;
BA_ "SigType" SG_ 2566840830 PercentTorqueAtPeakTorquePoint5 1;
BA_ "SPN" SG_ 2566840830 ReferenceRetarderTorque 556;
BA_ "SigType" SG_ 2566840830 ReferenceRetarderTorque 1;
BA_ "SPN" SG_ 2566840830 RetarderSpeedAtPeakTorquePoint5 547;
BA_ "SigType" SG_ 2566840830 RetarderSpeedAtPeakTorquePoint5 1;
BA_ "SPN" SG_ 2566840830 PercentTorqueAtPoint4 554;
BA_ "SigType" SG_ 2566840830 PercentTorqueAtPoint4 1;
BA_ "SPN" SG_ 2566840830 RetarderSpeedAtPoint4 550;
BA_ "SigType" SG_ 2566840830 RetarderSpeedAtPoint4 1;
BA_ "SPN" SG_ 2566840830 PercentTorqueAtPoint3 553;
BA_ "SigType" SG_ 2566840830 PercentTorqueAtPoint3 1;
BA_ "SPN" SG_ 2566840830 RetarderSpeedAtPoint3 549;
BA_ "SigType" SG_ 2566840830 RetarderSpeedAtPoint3 1;
BA_ "SPN" SG_ 2566840830 PercentTorqueAtMaxSpeedPoint2 552;
BA_ "SigType" SG_ 2566840830 PercentTorqueAtMaxSpeedPoint2 1;
BA_ "SPN" SG_ 2566840830 MaxRetarderSpeedPoint2 548;
BA_ "SigType" SG_ 2566840830 MaxRetarderSpeedPoint2 1;
BA_ "SPN" SG_ 2566840830 PercentTorqueAtIdlePoint1 551;
BA_ "SigType" SG_ 2566840830 PercentTorqueAtIdlePoint1 1;
BA_ "SPN" SG_ 2566840830 RetarderSpeedAtIdlePoint1 546;
BA_ "SigType" SG_ 2566840830 RetarderSpeedAtIdlePoint1 1;
BA_ "SPN" SG_ 2566840830 RetarderCtrlMethod 557;
BA_ "SigType" SG_ 2566840830 RetarderCtrlMethod 1;
BA_ "SPN" SG_ 2566840830 RetarderLocation 902;
BA_ "SPN" SG_ 2566840830 RetarderType 901;
BA_ "SPN" SG_ 2633930238 EngOperationTimeSinceRebuild 1193;
BA_ "SigType" SG_ 2633930238 EngOperationTimeSinceRebuild 1;
BA_ "SPN" SG_ 2566844670 PowerTakeoffSetSpeed 187;
BA_ "SigType" SG_ 2566844670 PowerTakeoffSetSpeed 1;
BA_ "SPN" SG_ 2566844670 PowerTakeoffSpeed 186;
BA_ "SigType" SG_ 2566844670 PowerTakeoffSpeed 1;
BA_ "SPN" SG_ 2566844670 PowerTakeoffOilTemp 90;
BA_ "SigType" SG_ 2566844670 PowerTakeoffOilTemp 1;
BA_ "SPN" SG_ 2566844670 OprtrEngPTOGvrnrMmrySelectSwitch 2897;
BA_ "SigType" SG_ 2566844670 OprtrEngPTOGvrnrMmrySelectSwitch 4;
BA_ "SPN" SG_ 2566844670 EngRmtPTOGvrnrVrblSpedCtrlSwitch 978;
BA_ "SigType" SG_ 2566844670 EngRmtPTOGvrnrVrblSpedCtrlSwitch 4;
BA_ "SPN" SG_ 2566844670 EngRmtPTOGvrnrPrprgrmmdSpdCtrlSw 979;
BA_ "SigType" SG_ 2566844670 EngRmtPTOGvrnrPrprgrmmdSpdCtrlSw 4;
BA_ "SPN" SG_ 2566844670 EngPTOGvrnrCast_DecelerateSwitch 983;
BA_ "SigType" SG_ 2566844670 EngPTOGvrnrCast_DecelerateSwitch 4;
BA_ "SPN" SG_ 2566844670 EngPTOGovernorSetSwitch 984;
BA_ "SigType" SG_ 2566844670 EngPTOGovernorSetSwitch 4;
BA_ "SPN" SG_ 2566844670 EngPTOGovernorResumeSwitch 982;
BA_ "SigType" SG_ 2566844670 EngPTOGovernorResumeSwitch 4;
BA_ "SPN" SG_ 2566844670 EngPTOGovernorEnableSwitch 980;
BA_ "SigType" SG_ 2566844670 EngPTOGovernorEnableSwitch 4;
BA_ "SPN" SG_ 2566844670 EngPTOGovernorAccelerateSwitch 981;
BA_ "SigType" SG_ 2566844670 EngPTOGovernorAccelerateSwitch 4;
BA_ "SPN" SG_ 2566844670 RmtPTOGvrnrPrprgrmmdSpdCtrlSwtch 3447;
BA_ "SigType" SG_ 2566844670 RmtPTOGvrnrPrprgrmmdSpdCtrlSwtch 4;
BA_ "SPN" SG_ 2566844670 AuxInputIgnoreSwitch 3448;
BA_ "SigType" SG_ 2566844670 AuxInputIgnoreSwitch 4;
BA_ "SPN" SG_ 2566770174 RearWasherFunction 2868;
BA_ "SPN" SG_ 2566770174 FrontOperatorWasherSwitch 2866;
BA_ "SPN" SG_ 2566770174 FrontNonoperatorWasherSwitch 2867;
BA_ "SPN" SG_ 2566770174 RearWiperDelayCtrl 2871;
BA_ "SigType" SG_ 2566770174 RearWiperDelayCtrl 1;
BA_ "SPN" SG_ 2566770174 FrontNonoperatorWiperDelayCtrl 2870;
BA_ "SigType" SG_ 2566770174 FrontNonoperatorWiperDelayCtrl 1;
BA_ "SPN" SG_ 2566770174 FrontOperatorWiperDelayCtrl 2869;
BA_ "SigType" SG_ 2566770174 FrontOperatorWiperDelayCtrl 1;
BA_ "SPN" SG_ 2566770174 RearWiperSwitch 2865;
BA_ "SPN" SG_ 2566770174 FrontOperatorWiperSwitch 2863;
BA_ "SPN" SG_ 2566770174 FrontNonoperatorWiperSwitch 2864;
BA_ "SPN" SG_ 2566769662 EngTorqueCurveSelectionCmd 6796;
BA_ "SPN" SG_ 2566769662 EngAltDroopAuxInputSelect 2885;
BA_ "SPN" SG_ 2566769662 EngAltDroopRemoteAccelSelect 2886;
BA_ "SPN" SG_ 2566769662 EngAltDroopAccel2Select 2879;
BA_ "SPN" SG_ 2566769662 EngAltDroopAccel1Select 2881;
BA_ "SPN" SG_ 2566769662 EngAltRatingSelect 2882;
BA_ "SigType" SG_ 2566769662 EngAltRatingSelect 1;
BA_ "SPN" SG_ 2566769662 EngAltLowIdleSwitch 2883;
BA_ "SigType" SG_ 2566769662 EngAltLowIdleSwitch 4;
BA_ "SPN" SG_ 2566769662 EngSynchronizationSwitch 1377;
BA_ "SigType" SG_ 2566769662 EngSynchronizationSwitch 4;
BA_ "SPN" SG_ 2566769662 EngAuxGovernorSwitch 2884;
BA_ "SigType" SG_ 2566769662 EngAuxGovernorSwitch 4;
BA_ "SPN" SG_ 2566768638 EngTorqueCurveSelection 1568;
BA_ "SPN" SG_ 2566768638 EngAltDroopAuxInputSelectState 2895;
BA_ "SPN" SG_ 2566768638 EngAltDropRemoteAccelSelectState 2894;
BA_ "SPN" SG_ 2566768638 EngAltDroopAccel2SelectState 2893;
BA_ "SPN" SG_ 2566768638 EngAltDroopAccel1SelectState 2889;
BA_ "SPN" SG_ 2566768638 EngAltRatingSelectState 2888;
BA_ "SPN" SG_ 2566768638 EngAltLowIdleSelectState 2891;
BA_ "SigType" SG_ 2566768638 EngAltLowIdleSelectState 5;
BA_ "SPN" SG_ 2566768638 EngMultiUnitSyncState 2890;
BA_ "SigType" SG_ 2566768638 EngMultiUnitSyncState 5;
BA_ "SPN" SG_ 2566768638 EngAuxGovernorState 2896;
BA_ "SigType" SG_ 2566768638 EngAuxGovernorState 5;
BA_ "SPN" SG_ 2365443326 OprtorsDesiredDelayedLampOffTime 2877;
BA_ "SigType" SG_ 2365443326 OprtorsDesiredDelayedLampOffTime 1;
BA_ "SPN" SG_ 2365443326 OperatorsDesiredBacklight 2878;
BA_ "SigType" SG_ 2365443326 OperatorsDesiredBacklight 1;
BA_ "SPN" SG_ 2365443326 HighLowBeamSwitch 2874;
BA_ "SigType" SG_ 2365443326 HighLowBeamSwitch 4;
BA_ "SPN" SG_ 2365443326 HazardLightSwitch 2875;
BA_ "SigType" SG_ 2365443326 HazardLightSwitch 4;
BA_ "SPN" SG_ 2365443326 TurnSignalSwitch 2876;
BA_ "SPN" SG_ 2365443326 MainLightSwitch 2872;
BA_ "SPN" SG_ 2365443326 WorkLightSwitch 2873;
BA_ "SPN" SG_ 2566776318 AppliedVehicleSpeedLimit 2595;
BA_ "SigType" SG_ 2566776318 AppliedVehicleSpeedLimit 1;
BA_ "SPN" SG_ 2566776318 MaxVehicleSpeedLimit7 2594;
BA_ "SigType" SG_ 2566776318 MaxVehicleSpeedLimit7 1;
BA_ "SPN" SG_ 2566776318 MaxVehicleSpeedLimit6 2593;
BA_ "SigType" SG_ 2566776318 MaxVehicleSpeedLimit6 1;
BA_ "SPN" SG_ 2566776318 MaxVehicleSpeedLimit5 2592;
BA_ "SigType" SG_ 2566776318 MaxVehicleSpeedLimit5 1;
BA_ "SPN" SG_ 2566776318 MaxVehicleSpeedLimit4 2591;
BA_ "SigType" SG_ 2566776318 MaxVehicleSpeedLimit4 1;
BA_ "SPN" SG_ 2566776318 MaxVehicleSpeedLimit3 2590;
BA_ "SigType" SG_ 2566776318 MaxVehicleSpeedLimit3 1;
BA_ "SPN" SG_ 2566776318 MaxVehicleSpeedLimit2 2589;
BA_ "SigType" SG_ 2566776318 MaxVehicleSpeedLimit2 1;
BA_ "SPN" SG_ 2566776318 MaxVehicleSpeedLimit1 2588;
BA_ "SigType" SG_ 2566776318 MaxVehicleSpeedLimit1 1;
BA_ "SPN" SG_ 2566802686 OprtrsBlackOutIntensitySelection 1844;
BA_ "SigType" SG_ 2566802686 OprtrsBlackOutIntensitySelection 1;
BA_ "SPN" SG_ 2566802686 BlackOutWorkLampSelect 1842;
BA_ "SigType" SG_ 2566802686 BlackOutWorkLampSelect 5;
BA_ "SPN" SG_ 2566802686 NightVisionIlluminatorSelect 1843;
BA_ "SigType" SG_ 2566802686 NightVisionIlluminatorSelect 5;
BA_ "SPN" SG_ 2566802686 BlackOutBrake_StopLampSelect 1841;
BA_ "SigType" SG_ 2566802686 BlackOutBrake_StopLampSelect 5;
BA_ "SPN" SG_ 2566802686 ConvoyDrivingLampSelect 1837;
BA_ "SigType" SG_ 2566802686 ConvoyDrivingLampSelect 5;
BA_ "SPN" SG_ 2566802686 ConvoyLampSelect 1838;
BA_ "SigType" SG_ 2566802686 ConvoyLampSelect 5;
BA_ "SPN" SG_ 2566802686 FrontBlackOutMarkerLampSelect 1839;
BA_ "SigType" SG_ 2566802686 FrontBlackOutMarkerLampSelect 5;
BA_ "SPN" SG_ 2566802686 RearBlackOutMarkerSelect 1840;
BA_ "SigType" SG_ 2566802686 RearBlackOutMarkerSelect 5;
BA_ "SPN" SG_ 2566774014 SlowVesselModeStatus 2617;
BA_ "SigType" SG_ 2566774014 SlowVesselModeStatus 5;
BA_ "SPN" SG_ 2566774014 TrollingModeStatus 2616;
BA_ "SigType" SG_ 2566774014 TrollingModeStatus 5;
BA_ "SPN" SG_ 2566774014 EngThrttlSynchrnzationModeStatus 2615;
BA_ "SPN" SG_ 2566823166 EngMainBearing12Temp 6830;
BA_ "SigType" SG_ 2566823166 EngMainBearing12Temp 1;
BA_ "SPN" SG_ 2566823166 EngMainBearing11Temp 1167;
BA_ "SigType" SG_ 2566823166 EngMainBearing11Temp 1;
BA_ "SPN" SG_ 2566823166 EngMainBearing10Temp 1166;
BA_ "SigType" SG_ 2566823166 EngMainBearing10Temp 1;
BA_ "SPN" SG_ 2566823166 EngMainBearing9Temp 1165;
BA_ "SigType" SG_ 2566823166 EngMainBearing9Temp 1;
BA_ "SPN" SG_ 2566823422 EngMainBearing8Temp 1164;
BA_ "SigType" SG_ 2566823422 EngMainBearing8Temp 1;
BA_ "SPN" SG_ 2566823422 EngMainBearing7Temp 1163;
BA_ "SigType" SG_ 2566823422 EngMainBearing7Temp 1;
BA_ "SPN" SG_ 2566823422 EngMainBearing6Temp 1162;
BA_ "SigType" SG_ 2566823422 EngMainBearing6Temp 1;
BA_ "SPN" SG_ 2566823422 EngMainBearing5Temp 1161;
BA_ "SigType" SG_ 2566823422 EngMainBearing5Temp 1;
BA_ "SPN" SG_ 2566823678 EngMainBearing4Temp 1160;
BA_ "SigType" SG_ 2566823678 EngMainBearing4Temp 1;
BA_ "SPN" SG_ 2566823678 EngMainBearing3Temp 1159;
BA_ "SigType" SG_ 2566823678 EngMainBearing3Temp 1;
BA_ "SPN" SG_ 2566823678 EngMainBearing2Temp 1158;
BA_ "SigType" SG_ 2566823678 EngMainBearing2Temp 1;
BA_ "SPN" SG_ 2566823678 EngMainBearing1Temp 1157;
BA_ "SigType" SG_ 2566823678 EngMainBearing1Temp 1;
BA_ "SPN" SG_ 2432595710 DisplayDeadbands 2577;
BA_ "SPN" SG_ 2432595710 LEDPatternCtrl 2578;
BA_ "SPN" SG_ 2432595710 LEDDisplayDeadbandCtrl 1806;
BA_ "SPN" SG_ 2432595710 LEDDisplayModeCtrl 1805;
BA_ "SPN" SG_ 2432595710 LEDDisplayData1 1573;
BA_ "SPN" SG_ 2365486590 AbsLaserStrikePos 2794;
BA_ "SigType" SG_ 2365486590 AbsLaserStrikePos 1;
BA_ "SPN" SG_ 2365486590 LaserStrikeDataLatency 2793;
BA_ "SigType" SG_ 2365486590 LaserStrikeDataLatency 1;
BA_ "SPN" SG_ 2365486590 LaserReceiverType 2576;
BA_ "SigType" SG_ 2365486590 LaserReceiverType 1;
BA_ "SPN" SG_ 2365486590 LaserStrikeVerticalDeviation 1574;
BA_ "SigType" SG_ 2365486590 LaserStrikeVerticalDeviation 1;
BA_ "SPN" SG_ 2365485566 LaserTracerInformation 1583;
BA_ "SPN" SG_ 2365485566 LEDDisplayData2 1582;
BA_ "SPN" SG_ 2365485566 LaserTracerHorizontalDeviation 1581;
BA_ "SigType" SG_ 2365485566 LaserTracerHorizontalDeviation 1;
BA_ "SPN" SG_ 2365485566 LaserTracerVerticalDistance 1580;
BA_ "SigType" SG_ 2365485566 LaserTracerVerticalDistance 1;
BA_ "SPN" SG_ 2365485566 LaserTracerTargetDeviation 1579;
BA_ "SigType" SG_ 2365485566 LaserTracerTargetDeviation 1;
BA_ "SPN" SG_ 2633939454 TripDriveFuelEconomy 1006;
BA_ "SigType" SG_ 2633939454 TripDriveFuelEconomy 1;
BA_ "SPN" SG_ 2633939454 TripCruiseFuelUsed 1005;
BA_ "SigType" SG_ 2633939454 TripCruiseFuelUsed 1;
BA_ "SPN" SG_ 2633939454 TripVehicleIdleFuelUsed 1004;
BA_ "SigType" SG_ 2633939454 TripVehicleIdleFuelUsed 1;
BA_ "SPN" SG_ 2633939454 TripPTOGovernorNonmovingFuelUsed 1003;
BA_ "SigType" SG_ 2633939454 TripPTOGovernorNonmovingFuelUsed 1;
BA_ "SPN" SG_ 2633939454 TripPTOGovernorMovingFuelUsed 1002;
BA_ "SigType" SG_ 2633939454 TripPTOGovernorMovingFuelUsed 1;
BA_ "SPN" SG_ 2633939454 TripDriveFuelUsed 1001;
BA_ "SigType" SG_ 2633939454 TripDriveFuelUsed 1;
BA_ "SPN" SG_ 2365486334 BldeHeightSetPointHighResolution 1759;
BA_ "SigType" SG_ 2365486334 BldeHeightSetPointHighResolution 1;
BA_ "SPN" SG_ 2365486334 ModifyLevelingSystemSetPoint 1575;
BA_ "SigType" SG_ 2365486334 ModifyLevelingSystemSetPoint 1;
BA_ "SPN" SG_ 2364542462 SetElvtnSnsr2RefElvtn_5406 5406;
BA_ "SigType" SG_ 2364542462 SetElvtnSnsr2RefElvtn_5406 5;
BA_ "SPN" SG_ 2364542462 SetElvtnSnsr1RefElvtn_5405 5405;
BA_ "SigType" SG_ 2364542462 SetElvtnSnsr1RefElvtn_5405 5;
BA_ "SPN" SG_ 2364542462 SdShiftDesBladeOfsOprtrCtrl_3339 3339;
BA_ "SPN" SG_ 2364542462 SdShiftBladeCtlModeOprtrCtl_3338 3338;
BA_ "SPN" SG_ 2364542462 RiDesBladeOfsOperatorCtl_3337 3337;
BA_ "SPN" SG_ 2364542462 LeDesBladeOfsOperatorCtl_3336 3336;
BA_ "SPN" SG_ 2364542462 RiBladeCtlModeOperatorCtl_3335 3335;
BA_ "SPN" SG_ 2364542462 LeBladeCtlModeOperatorCtl_3334 3334;
BA_ "SPN" SG_ 2364542462 BladeAutoModeCmd_3158 3158;
BA_ "SPN" SG_ 2364542462 DesiredGradeOffsetSwitch_3157 3157;
BA_ "SPN" SG_ 2364542462 BladeCtrlModeSwitch_3156 3156;
BA_ "SPN" SG_ 2365486078 MastPos 1576;
BA_ "SigType" SG_ 2365486078 MastPos 1;
BA_ "SPN" SG_ 2633937918 FlexibleFuelPercentage 5458;
BA_ "SigType" SG_ 2633937918 FlexibleFuelPercentage 1;
BA_ "SPN" SG_ 2633937918 TripAverageFuelRate 1029;
BA_ "SigType" SG_ 2633937918 TripAverageFuelRate 1;
BA_ "SPN" SG_ 2633937918 TotalEngPTOGovernorFuelUsed 1028;
BA_ "SigType" SG_ 2633937918 TotalEngPTOGovernorFuelUsed 1;
BA_ "SPN" SG_ 2566845182 EngThrottleValve2Pos 3673;
BA_ "SigType" SG_ 2566845182 EngThrottleValve2Pos 1;
BA_ "SPN" SG_ 2566845182 EngThrottleValve1Pos 51;
BA_ "SigType" SG_ 2566845182 EngThrottleValve1Pos 1;
BA_ "SPN" SG_ 2566845182 EngAverageFuelEconomy 185;
BA_ "SigType" SG_ 2566845182 EngAverageFuelEconomy 1;
BA_ "SPN" SG_ 2566845182 EngInstantaneousFuelEconomy 184;
BA_ "SigType" SG_ 2566845182 EngInstantaneousFuelEconomy 1;
BA_ "SPN" SG_ 2566845182 EngFuelRate 183;
BA_ "SigType" SG_ 2566845182 EngFuelRate 1;
BA_ "SPN" SG_ 2566842878 EngTotalFuelUsed 250;
BA_ "SigType" SG_ 2566842878 EngTotalFuelUsed 1;
BA_ "SPN" SG_ 2566842878 EngTripFuel 182;
BA_ "SigType" SG_ 2566842878 EngTripFuel 1;
BA_ "SPN" SG_ 2633883646 FrontWheelDriveActuatorStatus 2612;
BA_ "SigType" SG_ 2633883646 FrontWheelDriveActuatorStatus 4;
BA_ "SPN" SG_ 2633880062 FMSstandardSWversionSupported 2806;
BA_ "SigType" SG_ 2633880062 FMSstandardSWversionSupported 1;
BA_ "SPN" SG_ 2633880062 FMSstandardRequestsSupported 2805;
BA_ "SigType" SG_ 2633880062 FMSstandardRequestsSupported 5;
BA_ "SPN" SG_ 2633880062 FMSstandardDiagnosticsSupported 2804;
BA_ "SigType" SG_ 2633880062 FMSstandardDiagnosticsSupported 5;
BA_ "SPN" SG_ 2566806526 DrverAlertnessWarningSystemState 7475;
BA_ "SPN" SG_ 2566806526 DriverAlertnessLevel 7474;
BA_ "SigType" SG_ 2566806526 DriverAlertnessLevel 1;
BA_ "SPN" SG_ 2566806526 LnDpartureIndicationEnableStatus 1702;
BA_ "SigType" SG_ 2566806526 LnDpartureIndicationEnableStatus 5;
BA_ "SPN" SG_ 2566806526 LaneTrackingStatusLeftSide 1710;
BA_ "SigType" SG_ 2566806526 LaneTrackingStatusLeftSide 5;
BA_ "SPN" SG_ 2566806526 LaneTrackingStatusRightSide 1711;
BA_ "SigType" SG_ 2566806526 LaneTrackingStatusRightSide 5;
BA_ "SPN" SG_ 2431649790 LaneDepartureImminentLeSide_1700 1700;
BA_ "SigType" SG_ 2431649790 LaneDepartureImminentLeSide_1700 5;
BA_ "SPN" SG_ 2431649790 LaneDepartureImminentRiSide_1701 1701;
BA_ "SigType" SG_ 2431649790 LaneDepartureImminentRiSide_1701 5;
BA_ "SPN" SG_ 2431649790 LaneDepartureRight_3566 3566;
BA_ "SigType" SG_ 2431649790 LaneDepartureRight_3566 5;
BA_ "SPN" SG_ 2431649790 LaneDepartureLeft_3565 3565;
BA_ "SigType" SG_ 2431649790 LaneDepartureLeft_3565 5;
BA_ "SPN" SG_ 2431649790 DriverAlertnessWarning_7473 7473;
BA_ "SPN" SG_ 2633929214 EngFuelLeakage2 1240;
BA_ "SigType" SG_ 2633929214 EngFuelLeakage2 5;
BA_ "SPN" SG_ 2633929214 EngFuelLeakage1 1239;
BA_ "SigType" SG_ 2633929214 EngFuelLeakage1 5;
BA_ "SPN" SG_ 2566831614 FanDriveBypassCmdStatus 4212;
BA_ "SigType" SG_ 2566831614 FanDriveBypassCmdStatus 1;
BA_ "SPN" SG_ 2566831614 HydFanMotorPress 4211;
BA_ "SigType" SG_ 2566831614 HydFanMotorPress 1;
BA_ "SPN" SG_ 2566831614 FanSpeed 1639;
BA_ "SigType" SG_ 2566831614 FanSpeed 1;
BA_ "SPN" SG_ 2566831614 FanDriveState 977;
BA_ "SPN" SG_ 2566831614 EstPercentFanSpeed 975;
BA_ "SigType" SG_ 2566831614 EstPercentFanSpeed 1;
BA_ "SPN" SG_ 2566820094 EngTorqueLimit6AxleInput 1263;
BA_ "SigType" SG_ 2566820094 EngTorqueLimit6AxleInput 1;
BA_ "SPN" SG_ 2566820094 EngTorqueLimit5Switch 1262;
BA_ "SigType" SG_ 2566820094 EngTorqueLimit5Switch 1;
BA_ "SPN" SG_ 2566820094 EngTorqueLimit4Trans 1261;
BA_ "SigType" SG_ 2566820094 EngTorqueLimit4Trans 1;
BA_ "SPN" SG_ 2566820094 EngTorqueLimit3Trans 1260;
BA_ "SigType" SG_ 2566820094 EngTorqueLimit3Trans 1;
BA_ "SPN" SG_ 2566820094 TransGearRatio3 1259;
BA_ "SigType" SG_ 2566820094 TransGearRatio3 1;
BA_ "SPN" SG_ 2566820094 EngTorqueLimit2Trans 1258;
BA_ "SigType" SG_ 2566820094 EngTorqueLimit2Trans 1;
BA_ "SPN" SG_ 2566820094 TransGearRatio2 1257;
BA_ "SigType" SG_ 2566820094 TransGearRatio2 1;
BA_ "SPN" SG_ 2566820094 EngTorqueLimit1Trans 1256;
BA_ "SigType" SG_ 2566820094 EngTorqueLimit1Trans 1;
BA_ "SPN" SG_ 2566820094 TransGearRatio1 1255;
BA_ "SigType" SG_ 2566820094 TransGearRatio1 1;
BA_ "SPN" SG_ 2566820094 EngTorqueLimitFeature 1632;
BA_ "SPN" SG_ 2566820094 TorqueLimitingFeatureStatus 1254;
BA_ "SigType" SG_ 2566820094 TorqueLimitingFeatureStatus 5;
BA_ "SPN" SG_ 2566820094 CalibRecordDurationTime 1253;
BA_ "SigType" SG_ 2566820094 CalibRecordDurationTime 1;
BA_ "SPN" SG_ 2566820094 CalibRecordStartYear 1252;
BA_ "SigType" SG_ 2566820094 CalibRecordStartYear 1;
BA_ "GenSigStartValue" SG_ 2566820094 CalibRecordStartDay 1;
BA_ "SPN" SG_ 2566820094 CalibRecordStartDay 1251;
BA_ "SigType" SG_ 2566820094 CalibRecordStartDay 1;
BA_ "GenSigStartValue" SG_ 2566820094 CalibRecordStartMonth 1;
BA_ "SPN" SG_ 2566820094 CalibRecordStartMonth 1250;
BA_ "SigType" SG_ 2566820094 CalibRecordStartMonth 1;
BA_ "SPN" SG_ 2566820094 EngPeakTorque2 1249;
BA_ "SigType" SG_ 2566820094 EngPeakTorque2 1;
BA_ "SPN" SG_ 2566820094 EngPeakTorque1 1248;
BA_ "SigType" SG_ 2566820094 EngPeakTorque1 1;
BA_ "SPN" SG_ 2566820094 EngPower 1247;
BA_ "SigType" SG_ 2566820094 EngPower 1;
BA_ "SPN" SG_ 2566820094 NumberOfEngTorqueHistoryRecords 1246;
BA_ "SigType" SG_ 2566820094 NumberOfEngTorqueHistoryRecords 1;
BA_ "SPN" SG_ 2364542206 TransCluCnvrInpSpd_5052 5052;
BA_ "SigType" SG_ 2364542206 TransCluCnvrInpSpd_5052 1;
BA_ "SPN" SG_ 2364542206 TransTorqueConverterRatio_3030 3030;
BA_ "SigType" SG_ 2364542206 TransTorqueConverterRatio_3030 1;
BA_ "SPN" SG_ 2566802174 TransAutoNeutralSt 7696;
BA_ "SigType" SG_ 2566802174 TransAutoNeutralSt 5;
BA_ "SPN" SG_ 2566802174 TransWarningIndicator 5344;
BA_ "SigType" SG_ 2566802174 TransWarningIndicator 5;
BA_ "SPN" SG_ 2566802174 TrnsRverseGearShiftInhibitStatus 4261;
BA_ "SigType" SG_ 2566802174 TrnsRverseGearShiftInhibitStatus 4;
BA_ "SPN" SG_ 2566802174 TransMode8Indicator 4253;
BA_ "SigType" SG_ 2566802174 TransMode8Indicator 4;
BA_ "SPN" SG_ 2566802174 TransMode7Indicator 4252;
BA_ "SigType" SG_ 2566802174 TransMode7Indicator 4;
BA_ "SPN" SG_ 2566802174 TransMode6Indicator 4251;
BA_ "SigType" SG_ 2566802174 TransMode6Indicator 4;
BA_ "SPN" SG_ 2566802174 TransMode5Indicator 4250;
BA_ "SigType" SG_ 2566802174 TransMode5Indicator 4;
BA_ "SPN" SG_ 2566802174 TransRequestedGearFeedback 3289;
BA_ "SigType" SG_ 2566802174 TransRequestedGearFeedback 1;
BA_ "SPN" SG_ 2566802174 TransMode1Indicator 2536;
BA_ "SigType" SG_ 2566802174 TransMode1Indicator 4;
BA_ "SPN" SG_ 2566802174 TransMode2Indicator 2537;
BA_ "SigType" SG_ 2566802174 TransMode2Indicator 4;
BA_ "SPN" SG_ 2566802174 TransMode3Indicator 2538;
BA_ "SigType" SG_ 2566802174 TransMode3Indicator 4;
BA_ "SPN" SG_ 2566802174 TransMode4Indicator 2539;
BA_ "SigType" SG_ 2566802174 TransMode4Indicator 4;
BA_ "SPN" SG_ 2566802174 TransShiftInhibitIndicator 1851;
BA_ "SigType" SG_ 2566802174 TransShiftInhibitIndicator 5;
BA_ "SPN" SG_ 2566802174 TransEngCrankEnable 2900;
BA_ "SigType" SG_ 2566802174 TransEngCrankEnable 5;
BA_ "SPN" SG_ 2566802174 ActiveShiftConsoleIndicator 2945;
BA_ "SigType" SG_ 2566802174 ActiveShiftConsoleIndicator 5;
BA_ "SPN" SG_ 2566802174 TransReadyForBrakeRelease 3086;
BA_ "SigType" SG_ 2566802174 TransReadyForBrakeRelease 5;
BA_ "SPN" SG_ 2566802174 TrnsRqstedRangeDisplayFlashState 1849;
BA_ "SigType" SG_ 2566802174 TrnsRqstedRangeDisplayFlashState 5;
BA_ "SPN" SG_ 2566802174 TrnsRqstedRangeDisplayBlankState 1850;
BA_ "SigType" SG_ 2566802174 TrnsRqstedRangeDisplayBlankState 5;
BA_ "SPN" SG_ 2566802174 TransServiceIndicator 4178;
BA_ "SigType" SG_ 2566802174 TransServiceIndicator 5;
BA_ "SPN" SG_ 2566802174 TransAirSupplyPressIndicator 6566;
BA_ "SigType" SG_ 2566802174 TransAirSupplyPressIndicator 4;
BA_ "SPN" SG_ 2566802174 TransMode10Indicator 6568;
BA_ "SigType" SG_ 2566802174 TransMode10Indicator 4;
BA_ "SPN" SG_ 2566802174 TransMode9Indicator 6567;
BA_ "SigType" SG_ 2566802174 TransMode9Indicator 4;
BA_ "SPN" SG_ 2566802174 TrnsCrrentRangeDisplayBlankState 4176;
BA_ "SigType" SG_ 2566802174 TrnsCrrentRangeDisplayBlankState 5;
BA_ "SPN" SG_ 2633935870 ClutchLifeRemaining 2983;
BA_ "SigType" SG_ 2633935870 ClutchLifeRemaining 1;
BA_ "SPN" SG_ 2633935870 LowestPossibleGear 1114;
BA_ "SigType" SG_ 2633935870 LowestPossibleGear 1;
BA_ "SPN" SG_ 2633935870 HighestPossibleGear 1115;
BA_ "SigType" SG_ 2633935870 HighestPossibleGear 1;
BA_ "SPN" SG_ 2633935870 RecommendedGear 1113;
BA_ "SigType" SG_ 2633935870 RecommendedGear 1;
BA_ "SPN" SG_ 2633942014 TransForwardDirectionSwitch 903;
BA_ "SigType" SG_ 2633942014 TransForwardDirectionSwitch 5;
BA_ "SPN" SG_ 2633942014 TransNeutralSwitch 604;
BA_ "SigType" SG_ 2633942014 TransNeutralSwitch 5;
BA_ "SPN" SG_ 2633942014 TransReverseDirectionSwitch 767;
BA_ "SigType" SG_ 2633942014 TransReverseDirectionSwitch 5;
BA_ "SPN" SG_ 2633942014 TransLowRangeSenseSwitch 779;
BA_ "SigType" SG_ 2633942014 TransLowRangeSenseSwitch 5;
BA_ "SPN" SG_ 2633942014 TransHighRangeSenseSwitch 778;
BA_ "SigType" SG_ 2633942014 TransHighRangeSenseSwitch 5;
BA_ "SPN" SG_ 2633942526 TransSynchronizerBrakeValue 54;
BA_ "SigType" SG_ 2633942526 TransSynchronizerBrakeValue 1;
BA_ "SPN" SG_ 2633942526 TransSynchronizerClutchValue 53;
BA_ "SigType" SG_ 2633942526 TransSynchronizerClutchValue 1;
VAL_ 2348941054 AutoNeutralReq_7695 0 "No request to shift to Auto-Neutral state" 1 "Request to shift to Auto-Neutral state" 2 "Reserved" 3 "Don’t Care / Take No Action";
VAL_ 2348941054 TransMode8_4249 0 "Disable" 1 "Enable" 2 "Reserved" 3 "Take no action";
VAL_ 2348941054 TransMode7_4248 0 "Disable" 1 "Enable" 2 "Reserved" 3 "Take no action";
VAL_ 2348941054 TransMode6_4247 0 "Disable" 1 "Enable" 2 "Reserved" 3 "Take no action";
VAL_ 2348941054 TransMode5_4246 0 "Disable" 1 "Enable" 2 "Reserved" 3 "Take no action";
VAL_ 2348941054 TrnsShftSelectorDMS_2985 0 "Off" 1 "On" 2 "Error" 3 "Not available";
VAL_ 2348941054 TransRequestedLaunchGear_4255 0 "No specific launch gear requested" 1 "Launch the vehicle in 1st gear" 2 "Launch the vehicle in 2nd gear" 3 "Launch the vehicle in 3rd gear" 4 "Launch the vehicle in 4th gear" 5 "Launch the vehicle in 5th gear" 6 "Launch the vehicle in 6th gear" 7 "Launch the vehicle in 7th gear" 8 "Launch the vehicle in 8th gear" 9 "Launch the vehicle in Reverse 1" 10 "Launch the vehicle in Reverse 2" 11 "Launch the vehicle in Reverse 3" 12 "Launch the vehicle in Reverse 4 " 13 "Allow transmission to select the optimum launch gear" 14 "Error" 15 "Not Available";
VAL_ 2348941054 TransMode4_1855 0 "Disable" 1 "Enable" 2 "Reserved" 3 "Take no action";
VAL_ 2348941054 TransMode3_1854 0 "Disable" 1 "Enable" 2 "Reserved" 3 "Take no action";
VAL_ 2348941054 TransMode2_1853 0 "Disable" 1 "Enable" 2 "Reserved" 3 "Take no action";
VAL_ 2348941054 TransMode1_1852 0 "Disable" 1 "Enable" 2 "Reserved" 3 "Take no action";
VAL_ 2348941054 TransLoadReductionInhibitRq_5762 0 "Allow or resume transmission load reduction functions" 1 "Inhibit or abort transmission load reduction functions" 2 "Reserved" 3 "Don't care/take no action";
VAL_ 2348941054 DisengDiffLockRqCentralRear_691 0 "Engage differential lock" 1 "Disengage differential lock" 2 "Reserved" 3 "Take no action";
VAL_ 2348941054 DisengDiffLockRqCentralFront_690 0 "Engage differential lock" 1 "Disengage differential lock" 2 "Reserved" 3 "Take no action";
VAL_ 2348941054 DisengageDiffLockRqCentral_689 0 "Engage differential lock" 1 "Disengage differential lock" 2 "Reserved" 3 "Take no action";
VAL_ 2348941054 DisengageDiffLockRqRearAxle2_688 0 "Engage differential lock" 1 "Disengage differential lock" 2 "Reserved" 3 "Take no action";
VAL_ 2348941054 DisengageDiffLockRqRearAxle1_687 0 "Engage differential lock" 1 "Disengage differential lock" 2 "Reserved" 3 "Take no action";
VAL_ 2348941054 DisengDiffLockRqFrontAxle2_686 0 "Engage differential lock" 1 "Disengage differential lock" 2 "Reserved" 3 "Take no action";
VAL_ 2348941054 DisengDiffLockRqFrontAxle1_685 0 "Engage differential lock" 1 "Disengage differential lock" 2 "Reserved" 3 "Take no action";
VAL_ 2348941054 TransRequestedGear_525 223 "Reverse Selector Position" 224 "Position unknown and/or no buttons pressed" 225 "Press of momentary button to reselect current position" 226 "Between ‘Reverse’ and ‘Park’ shift selector positions" 227 "Between ‘Neutral’ and ‘Reverse’ shift selector positions" 228 "Between ‘Drive’ and ‘Neutral’ shift selector positions" 229 "Between D-1 and ‘Drive’ shift selector positions" 230 "Between D-2 and D-1 shift selector positions" 231 "Between D-3 and D-2 shift selector positions" 232 "Between D-4 and D-3 shift selector positions" 233 "Between D-5 and D-4 shift selector positions" 234 "Between D-6 and D-5 shift selector positions" 235 "Between D-7 and D-6 shift selector positions" 236 "Between two forward shift selector positions" 237 "Between two reverse shift selector positions" 238 "Between two shift selector positions" 239 "D-7: 7th forward selector position referenced from ‘Drive’" 240 "D-6: 6th forward selector position referenced from ‘Drive’" 241 "D-5: 5th forward selector position referenced from ‘Drive’" 242 "D-4: 4th forward selector position referenced from ‘Drive’" 243 "D-3: 3rd forward selector position referenced from ‘Drive’" 244 "D-2: 2nd forward selector position referenced from ‘Drive’" 245 "D-1: 1st forward selector position referenced from ‘Drive’" 246 "Downshift 2 gears from current position" 247 "Downshift 1 gear from current position" 248 "Upshift 2 gears from current position" 249 "Upshift 1 gear from current position" 250 "Forward ‘Low’ position" 251 "‘Park’ position" 252 "Forward Drive Position" 253 "Hold current gear";
VAL_ 2348941054 TransRevGearShiftInhibitRq_4242 0 "Allow shifts into Reverse gear" 1 "Inhibit shifts into Reverse gear" 2 "Reserved " 3 "Take no action";
VAL_ 2348941054 DisengageDrivelineRq_683 0 "Allow driveline engagement" 1 "Disengage driveline" 2 "Reserved" 3 "Take no action";
VAL_ 2348941054 TrnsTrqeConvLockupDisableRq_682 0 "Allow torque converter lockup" 1 "Disable torque converter lockup" 2 "Reserved" 3 "Take no action";
VAL_ 2348941054 TransGearShiftInhibitRq_681 0 "Gear shifts are allowed " 1 "Gear shifts are inhibited " 2 "Reserved" 3 "Take no action ";
VAL_ 2566839806 EngTurboOilLevelSwitch 0 "No oil present at turbocharger" 1 "Oil present at turbocharger" 2 "Error" 3 "Not available";
VAL_ 2566841598 ClntLvlEngPrtctionShutdownStatus 0 "Disabled" 1 "Enabled" 2 "Reserved" 3 "Not Available";
VAL_ 2566841598 PTOShutdownHasShutdownEng 0 "No" 1 "Yes" 2 "Error" 3 "Not available";
VAL_ 2566841598 EngAirShutoffStatus 0 "Air flow allowed to engine" 1 "Air flow restricted" 2 "Error" 3 "Not Available";
VAL_ 2566841598 EngOverspeedTest 0 "Engine Overspeed Test Not Active" 1 "Engine Overspeed Test Active" 2 "Reserved" 3 "Not Available";
VAL_ 2566841598 EngAirShutoffCmdStatus 0 "Air Shutoff Disabled" 1 "Air Shutoff Enabled" 2 "Reserved" 3 "Not Available";
VAL_ 2566841598 EngAlarmOutputCmdStatus 0 "Engine Alarm Output Command Not Active" 1 "Engine Alarm Output Command Active" 2 "Reserved" 3 "Not Available";
VAL_ 2566841598 EngAlarmAcknowledge 0 "Engine Alarm Acknowledge  Not Active " 1 "Engine Alarm Acknowledge Active" 2 "Error" 3 "Not Available";
VAL_ 2566841598 EngProtectionSystemConfig 0 "Disabled in calibration" 1 "Enabled in calibration" 2 "Error" 3 "Not available";
VAL_ 2566841598 EngProtectionSystemTimerState 0 "Inactive" 1 "Active" 2 "Error" 3 "Not available";
VAL_ 2566841598 EngProtectionSystemTimerOverride 0 "Inactive" 1 "Active" 2 "Error" 3 "Not available";
VAL_ 2566841598 EngPrtctnSystmApprachingShutdown 0 "Not approaching" 1 "Approaching" 2 "Error" 3 "Not available";
VAL_ 2566841598 EngPrtectionSystemHasShutdownEng 0 "No" 1 "Yes" 2 "Error" 3 "Not available";
VAL_ 2566841598 EngWaitToStartLamp 0 "Off" 1 "On" 2 "Error" 3 "Not available";
VAL_ 2566841598 RefrigerantHighPressSwitch 0 "Pressure normal" 1 "Pressure too high" 2 "Error" 3 "Not available";
VAL_ 2566841598 RefrigerantLowPressSwitch 0 "Pressure normal" 1 "Pressure too low" 2 "Error" 3 "Not available";
VAL_ 2566841598 A_CHighPressFanSwitch 0 "Pressure normal" 1 "Pressure high" 2 "Error" 3 "Not available";
VAL_ 2566841598 EngIdleShutdownTimerFunction 0 "Disabled in calibration" 1 "Enabled in calibration" 2 "Error" 3 "Not available";
VAL_ 2566841598 EngIdleShutdownTimerState 0 "Inactive" 1 "Active" 2 "Error" 3 "Not available";
VAL_ 2566841598 EngIdleShutdownTimerOverride 0 "Inactive" 1 "Active" 2 "Error" 3 "Not available";
VAL_ 2566841598 EngIdleShutdownDriverAlertMode 0 "Inactive" 1 "Active" 2 "Error" 3 "Not available";
VAL_ 2566841598 EngIdleShutdownHasShutdownEng 0 "No" 1 "Yes" 2 "Error" 3 "Not available";
VAL_ 2566786302 VehicleSystem5 0 "Ind. Process Control Stationary" 127 "Not Available";
VAL_ 2566786302 VehicleSystem4 0 "Non-specific System" 10 "System Tools" 20 "Safety Systems" 25 "Inter/Intranetwork Device" 30 "Electrical Distribution" 35 "Electrical Generation" 40 "Steering and Control Surfaces" 50 "Propulsion" 60 "Navigation" 70 "Communications" 75 "Sensor Communication Interface" 80 "Instrumentation/General Systems (deprecate)" 85 "External Environment" 90 "Internal Environment" 100 "Deck, Cargo and Fishing Equipment" 120 "Display" 125 "Entertainment" 127 "Not Available";
VAL_ 2566786302 VehicleSystem3 0 "Non-specific System" 1 "Skid Steer Loader" 2 "Articulated Dump Truck" 3 "Backhoe" 4 "Crawler" 5 "Excavator" 6 "Forklift" 7 "Four Wheel Drive Loader" 8 "Grader" 127 "Not Available";
VAL_ 2566786302 VehicleSystem2 0 "Non-specific System" 1 "Tractor" 2 "Tillage" 3 "Secondary Tillage" 4 "Planters/Seeders" 5 "Fertilizers" 6 "Sprayers" 7 "Harvesters" 8 "Root Harvesters" 9 "Forage" 10 "Irrigation" 11 "Transport/Trailer" 12 "Farm Yard Operations" 13 "Powered Auxiliary Device" 14 "Special Crops" 15 "Earth Work" 16 "Skidder" 17 "Sensor Systems" 19 "Timber Harvesters" 20 "Forwarders" 21 "Timber loaders" 22 "Timber Processing Machines" 23 "Mulchers" 24 "Utility Vehicles" 25 "Slurry Applicators" 127 "Not Available";
VAL_ 2566786302 VehicleSystem1 0 "Non-specific System" 1 "Tractor" 2 "Trailer" 127 "Not Available";
VAL_ 2566786302 IndustryGroup 0 "Global" 1 "On-Highway" 2 "Agricultural and Forestry" 3 "Construction" 4 "Marine" 5 "IndustrialProcessCtrlStationary" 6 "Reserved for SAE" 7 "Reserved for SAE";
VAL_ 2566786302 VehicleSystem 0 "Non-specific System" 127 "Not Available";
VAL_ 2566786302 Function 0 "Engine" 1 "Auxiliary Power Unit (APU)" 2 "Electric Propulsion Control" 3 "Transmission" 4 "Battery Pack Monitor" 5 "Shift Control/Console" 6 "Power TakeOff - (Main or Rear)" 7 "Axle - Steering" 8 "Axle - Drive" 9 "Brakes - System Controller" 10 "Brakes - Steer Axle" 11 "Brakes - Drive Axle" 12 "Retarder - Engine" 13 "Retarder - Driveline" 14 "Cruise Control" 15 "Fuel System" 16 "Steering Controller" 17 "Suspension - Steer Axle" 18 "Suspension - Drive Axle" 19 "Instrument Cluster" 20 "Trip Recorder" 21 "Cab Climate Control" 22 "Aerodynamic Control" 23 "Vehicle Navigation" 24 "Vehicle Security" 25 "Network Interconnect ECU" 26 "Body Controller" 27 "Power TakeOff (Secondary or Front)" 28 "Off Vehicle Gateway" 29 "Virtual Terminal (in cab)" 30 "Management Computer" 31 "Propulsion Battery Charger" 32 "Headway Controller" 33 "System Monitor" 34 "Hydraulic Pump Controller" 35 "Suspension - System Controller" 36 "Pneumatic - System Controller" 37 "Cab Controller" 38 "Tire Pressure Control" 39 "Ignition Control Module" 40 "Seat Control" 41 "Lighting - Operator Controls" 42 "Water Pump Control" 43 "Transmission Display" 44 "Exhaust Emission Control" 45 "Vehicle Dynamic Stability Control" 46 "Oil Sensor Unit" 47 "Information System Controller" 48 "Ramp Control" 49 "Clutch/Converter Control" 50 "Auxiliary Heater" 51 "Forward-Looking Collision Warning System" 52 "Chassis Controller" 53 "Alternator/Charging System" 54 "Communications Unit, Cellular" 55 "Communications Unit, Satellite" 56 "Communications Unit, Radio" 57 "Steering Column Unit" 58 "Fan Drive Control" 59 "Starter" 60 "Cab Display" 61 "File Server/Printer" 62 "On-Board Diagnostic Unit" 63 "Engine Valve Controller" 64 "Endurance Braking" 65 "Gas Flow Measurement" 66 "I/O Controller" 67 "Electrical System Controller" 68 "Aftertreatment system gas measurement" 69 "Engine Emission Aftertreatement System" 70 "Auxiliary Regeneration Device" 71 "Transfer Case Control" 72 "Coolant Valve Controller" 73 "Rollover Detection Control" 74 "Lubrication System" 75 "Supplemental Fan" 76 "Temperature Sensor" 77 "Fuel Properties Sensor" 78 "Fire Suppression System" 79 "Reserved" 80 "Reserved" 81 "Reserved" 82 "Reserved" 83 "Reserved" 84 "Reserved" 85 "Reserved" 86 "Reserved" 87 "Reserved" 88 "Reserved" 89 "Reserved" 90 "Reserved" 91 "Reserved" 92 "Reserved" 93 "Reserved" 94 "Reserved" 95 "Reserved" 96 "Reserved" 97 "Reserved" 98 "Reserved" 99 "Reserved" 100 "Reserved" 101 "Reserved" 102 "Reserved" 103 "Reserved" 104 "Reserved" 105 "Reserved" 106 "Reserved" 107 "Reserved" 108 "Reserved" 109 "Reserved" 110 "Reserved" 111 "Reserved" 112 "Reserved" 113 "Reserved" 114 "Reserved" 115 "Reserved" 116 "Reserved" 117 "Reserved" 118 "Reserved" 119 "Reserved" 120 "Reserved" 121 "Reserved" 122 "Reserved" 123 "Reserved" 124 "Reserved" 125 "Reserved" 126 "Reserved" 127 "Reserved";
VAL_ 2566786302 ManufacturerCode 0 "Reserved" 1 "Allied Signal Inc." 2 "Allison Transmission, GMC" 3 "Ametek, US Gauge Division" 4 "Ametek-Dixson" 5 "AMP Inc." 6 "Berifors Electronics AB" 7 "Case Corp." 8 "Caterpillar Inc." 9 "Chrysler Corp." 10 "Cummins Engine Co." 11 "Dearborn Group Inc." 12 "Deere & Company, Precision Farming" 13 "Delco Electronics" 14 "Detroit Diesel Corporation" 15 "Dickey-John Corp." 16 "Eaton Corp." 17 "Eaton Corp. Res & Dev" 18 "Eaton Corp, Transmission Division" 19 "Eaton Corp. Trucking Info Services" 20 "Eaton Ltd" 21 "Echilin Inc., Midland Brake Inc." 22 "Ford Motor Co., Electronic Concepts $ Systems" 23 "Ford Motor Co., Heavy Truck" 24 "Ford Motor Co., Vehicle Controls" 25 "Daimler Trucks North America LLC" 26 "General Motors Corp., Service Technology Group" 27 "GMC" 28 "Grote Ind. Inc." 29 "Hino Motors Ltd." 30 "Isuzu Motors Ltd." 31 "J Pollak Corp." 32 "Jacobs Vehicle Systems" 33 "John Deere" 34 "Kelsey Hayes Co." 35 "Kenworth Truck Co." 36 "Lucas Ltd." 37 "Mack Trucks Inc." 38 "Micro Processor Systems Inc." 39 "Microfirm Inc." 40 "Motorola AIEG Inc." 41 "Motorola Inc." 42 "International Truck and Engine Corp. Engine Electronics" 43 "International Truck and Engine Corp. Vehicle Electronics" 44 "Nippondenso Co. Ltd." 45 "PACCAR" 46 "Noregon Systems, Inc" 47 "Phillips Semiconductor" 48 "Pollak Alphabet" 49 "RE America Inc." 50 "Robert Bosch Corp" 51 "Robert Bosch GmbH" 52 "Meritor Automotive, Inc." 53 "Continental Automotive Systems US, Inc." 54 "Meritor Wabco" 55 "Ryder System Inc." 56 "SAIC" 57 "Sauer-Danfoss Co." 58 "SPX Corporation, OTC Division" 59 "VES Inc." 60 "Volvo Trucks North America Inc." 61 "Volvo Truck Corp." 62 "Wabco" 63 "ZF Industries Inc." 64 "unused" 65 "MAN Nutzfahrzeuge AG" 66 "John Deere Construction Equipment Division" 67 "Funk Manufacturing Company" 68 "Scania" 69 "Trimble Navigation" 70 "Flex-Coil Limited" 71 "Vansco Electronics Ltd." 72 "Sisu Corporation" 73 "LeTourneau, Inc." 74 "Eaton Axle-Brake Division" 75 "Deere & Co. Agricultural Division" 76 "unused" 77 "Deere Power Systems Group" 78 "Frank W. Murphy Manufacturing, Inc." 79 "Daimler Benz AG - Engine Division (PBM)" 80 "Twin Disc, Inc." 81 "Fire Research Corp" 82 "Bobcat/Ingersoll-Rand" 83 "Bendix VORAD Technologies" 84 "New Holland UK Limited" 85 "Kohler Co." 86 "C.E. Niehoff & Company" 87 "J.C. Bamford Excavators Ltd (JCB)" 88 "Satloc Precision GPS" 89 "Kverneland Group, Electronics Division" 90 "Knorr-Bremse SfN GmbH" 91 "BSG Bodensee Steuergeraete GmbH" 92 "Ag-Chem Equipment Co., Inc." 93 "Perkins Engines Company Ltd." 94 "CNH Global N.V." 95 "Pacific Insight Electronics Corp." 96 "Mech@tronic IT GmbH" 97 "Ag Leader Technology, Inc." 98 "Mueller-Elektronik GmbH & Co." 99 "International Transmissions Ltd (ITL)" 100 "VDO Technik AG" 101 "Sensoria" 102 "AGCO GmbH & Co." 103 "CLAAS Agrosystems GmbH & Co. KG" 104 "Claas Selbstfahrende Erntemaschinen GmbH" 105 "Kiepe Elektrik GmbH & Co. KG" 106 "BAE Systems Controls, Inc." 107 "Grimme Landmaschinen GmbH & Co. KG" 108 "WTK-Elecktronik GmbH" 109 "TeeJet Technologies Denmark" 110 "EPIQ Sensor-Nite" 111 "Maschinenfabrik Bernard Krone GmbH" 112 "MECALAC" 113 "Stress-Tek, Inc." 114 "EControls, Inc." 115 "NACCO Materials Handling Group, Inc." 116 "BEELINE Technologies" 117 "HUSCO International" 118 "Intron GmbH" 119 "IntegriNautics" 120 "RDS Technology Ltd." 121 "HED (Hydro Electronic Devices, Inc.)" 122 "FG Wilson (Engineering) Limited" 123 "Basler Electric" 124 "Hydac Electronic" 125 "Nevada Automotive Test Center" 126 "Driver Tech" 127 "Holland USA" 128 "Gerhard Duecker GmbH & Co. KG" 129 "OMNEX Control Systems, Inc." 130 "Nido - Universal Machines B.V." 131 "ITT Industries" 132 "Mulag-Fahrzeugwerk" 133 "Bucher Schoerling GmbH" 134 "Iris Technology Ltd." 135 "Airmar Technology Corporation" 136 "Komatsu Ltd." 137 "Maretron" 138 "Georg Fritzmeier GmbH & Co. KG" 139 "Caterpillar Trimble Control Technologies (CTCT), LLC" 140 "Lowrance Electronics, Inc." 141 "Thales Navigation Ltd." 142 "TRW Automotive (Commercial Steering Systems)" 143 "W. Gmeiner GmbH & Co." 144 "Mercury Marine" 145 "MurCal Controls" 146 "Maxima Technologies" 147 "Nautibus Electronic GmbH" 148 "Blue Water Data, Inc." 149 "Holset" 150 "Fleetguard" 151 "Raven Industries Inc. - Flow Controls Division" 152 "elobau GmbH & Co. KG" 153 "Woodward, Industrial Controls Division" 154 "Westerbeke Corporation" 155 "Vetronix Corporation" 156 "ITT Industries - Cannon" 157 "ISSPRO Inc." 158 "Firestone Industrial Products Company" 159 "NTech Industries Inc." 160 "Nido" 161 "Offshore Systems (UK) Limited" 162 "Axiomatic Technologies" 163 "BRP Inc." 164 "DaimlerChrysler Off-Highway" 165 "CPAC Systems AB" 166 "Phoenix International" 167 "JLG Industries Inc." 168 "Xantrex" 169 "Marlin Technologies Inc." 170 "Computronics Corporation Ltd." 171 "Wachendorff Elektronik GmbH & Co. KG" 172 "Yanmar Marine USA" 173 "Ryeso, Inc." 174 "AB Volvo Penta" 175 "Veris Technologies, Inc." 176 "Moritz Aerospace" 177 "Diagnostic System Associates" 178 "Siemens VDO Automotive AG" 179 "TeeJet Technologies Denmark" 180 "Smart Power Systems" 181 "Coretronics, Inc." 182 "Vehicle Systems Engineering B.V." 183 "KDS Controls, Inc." 184 "EIA Electronics" 185 "Beede Electrical Instrument Company" 186 "Altronic, Inc." 187 "Air-Weigh" 188 "EMP Corp." 189 "QUALCOMM" 190 "Hella KGaA Hueck & Co." 191 "XRS Corporation" 192 "Floscan" 193 "Nobletec" 194 "TriMark Corporation" 195 "General Engine Products" 196 "LEMKEN GmbH & Co. KG" 197 "Mechron Power Systems" 198 "Mystic Valley Communications" 199 "Actia Corp." 200 "MGM Brakes" 201 "Disenos y Tecnologia S.A." 202 "Curtis Instruments, Inc." 203 "MILtronik GmbH" 204 "The Morey Corporation" 205 "SmarTire Systems Inc" 206 "port GmbH" 207 "Otto Engineering" 208 "Drew Technologies, Inc." 209 "Bell Equip. Co. SA (PTY) LTD" 210 "Iteris, Inc." 211 "DNA Group" 212 "Sure Power Industries, Inc." 213 "CNH Belgium N.V." 214 "MC elettronica Srl" 215 "Aetna Engineering/Fireboy-Xintex" 216 "Paneltronics Inc." 217 "RM Michaelides Software & Elektronik GmbH" 218 "Gits Manufacturing Company" 219 "Cat OEM Solutions" 220 "Beede Electrical Instrument Company, Inc." 221 "SiE" 222 "Generac Power Systems, Inc." 223 "Vaueo Retarder Co., Ltd." 224 "EMMI Network, S.L." 225 "SKF" 226 "Monaco Coach Corporation" 227 "Lykketronic A/S" 228 "ZF Marine Electronics" 229 "Garmin International Inc." 230 "Saucon Technologies" 231 "Topcon Positioning Systems, Inc." 232 "TSD Integrated Controls" 233 "Yacht Monitoring Solutions Inc." 234 "Mondial electronic GmbH" 235 "SailorMade Marine Telemetry - Tetra Technology Ltd." 236 "Norac Systems International Inc" 237 "Agtron Enterprises Inc" 238 "ZF Friedrichshafen AG" 239 "May & Scofield Ltd" 240 "Vanair Mfg" 241 "Schneider Automation SAS " 242 "Kokusandenki Co. Ltd" 243 "eRide, Inc." 244 "Techno-Matic" 245 "Capstan Ag Systems, Inc." 246 "Class 1, Inc" 247 "ePULSE" 248 "Cooper Standard Automotive Active Systems Group" 249 "Schaltbau GmbH" 250 "Kuhn Group" 251 "German Agricultural Society" 252 "Sensor-Technik Wiedemann GmbH" 253 "Mobile Control Systems" 254 "GE Sensing" 255 "MEAS France" 256 "Tyco Electronics AMP" 257 "Honda Motor Co., Ltd" 258 "ARAG" 259 "Jetter AG" 260 "Reichhardt GmbH" 261 "Red Dot Corporation" 262 "HydraForce, Inc" 263 "IMMI" 264 "Autolync" 265 "MTS Sensor Technologie GmbH" 266 "International Thermal Research Ltd" 267 "Red Lion Controls, Inc" 268 "Accurate Technologies" 269 "Saft America Inc.,  Space & Defense Division" 270 "Tennant" 271 "Cole Hersee" 272 "Gross Mechanical Laboratories, Inc" 273 "Active Research Limited" 274 "LTW Technology Co., LTD" 275 "Navico Egersund AS" 276 "Aqua-Hot Heating Systems" 277 "LHP Telematics" 278 "Takata Electronics" 279 "Geometris LP" 280 "Leica Geosystems Pty Ltd" 281 "Precision Governors LLC" 282 "Medallion Instrumentation Systems" 283 "CWF Hamilton & Co Ltd" 284 "Mobile Tech Chile" 285 "Sea Recovery Corp" 286 "Coelmo srl" 287 "NTech Industries, Inc" 288 "Mitsubishi FUSO Truck & Bus Corp." 289 "Watlow" 290 "Kuebler GmbH" 291 "Groeneveld Transport Efficiency BV" 292 "IKUSI - Angel Iglesias S.A." 293 "Spyder Controls Corp." 294 "Grayhill Inc." 295 "BEP Marine" 296 "micro dynamics GmbH" 297 "Zonar Systems Inc" 298 "Holley Performance" 299 "Rauch Landmaschinen GmbH" 300 "Systron Donner Automotive" 301 "Parker Hannifin (UK) Ltd FDE group" 302 "Nissin Kogyo Co., LTD" 303 "CTS Corporation" 304 "EmpirBus AB" 305 "NovAtel Inc" 306 "Sleipner Motor AB" 307 "MBW Technologies" 308 "Cyntrx" 309 "Krauss-Maffei Wegmann GmbH & Co. KG" 310 "TECNORD srl" 311 "Patrick Power Products" 312 "Lectronix, Inc." 313 "Ilmor Engineering, Inc" 314 "CSM GmbH" 315 "Icom Incorporated" 316 "ITT Flow Control" 317 "Navtronics Bvba" 318 "SAT Plan" 319 "Cadec Global" 320 "Miedema Landbouwwerktuigenfabriek B.V." 321 "Ultra Electronics, Electrics" 322 "MICHENKA s.r.o." 323 "Mobileye Vision Technologies Ltd." 324 "Snap-on Diagnostics" 325 "ASM Automation Sensorik Messtechnik GmbH" 326 "Akron Brass Company" 327 "Sonceboz SA" 328 "Qwerty Electronik AB" 329 "Deif A/S" 330 "Kidde Aerospace and Defense" 331 "Horton, Inc." 332 "HWH Corporation" 333 "Hadley Products Corporation" 334 "Takata-Petri AG" 335 "Evo Electric Ltd" 336 "APE s.r.o." 337 "Carraro S.p.A." 338 "GRAF-SYTECO" 339 "Competence Center ISOBUS e.V." 340 "Continental AG" 341 "Boning GmbH & Co" 342 "THOMAS MAGNETE GmbH" 343 "Baumer Group" 344 "Parvus Corporation" 345 "Korean Maritime University" 346 "Control Solutions" 347 "Honeywell" 348 "Amazonen Werke H. Dreyer" 349 "Suonentiet" 350 "Noris Marine Systems GmbH & Co KG" 351 "Thrane & Thrane" 352 "SAME DEUTZ-FAHR" 353 "Hegemon Electronics, Inc." 354 "Junkkari OY" 355 "Mastervolt International B.V." 356 "Fischer Panda Generators, Inc" 357 "Hardi International A/S" 358 "Victron Energy BV" 359 "Ludwig Bergmann GmbH" 360 "HJS Emission Technology GmbH & Co KG" 361 "InMach" 362 "Alois Poettinger Maschinenfabrik GmbH" 363 "BEI Duncan" 364 "OEM Controls Inc." 365 "Digi-Star, LLC" 366 "Viewnyx Corp." 367 "Fliegl Agrartechnik" 368 "HANSENHOF_electronic" 369 "Power Torque Engineering Ltd" 370 "Rolls-Royce Marine AS" 371 "Heinzmann GmbH & Co. KG" 372 "Delphi" 373 "Electronic Design Inc." 374 "Northern Lights, Inc." 375 "Williams Controls Inc." 376 "Quake Global" 377 "ifm electronic gmbh" 378 "Glendinning Marine Products" 379 "Yamabiko Corporation" 380 "Suntech International Ltd." 381 "B&G" 382 "National Agricultural and Food Research Organization" 383 "MCL Industries" 384 "Camano Light" 385 "Johnson Outdoor Marine Electronics" 386 "JLG Automation BVBA" 387 "Orscheln Products, LLC" 388 "Innomatix, LLC" 389 "Benchmark Electronics, Minnesota Division" 390 "Partech Inc." 391 "Electronic Design for Industry, Inc" 392 "Tianyuan Technology Co Ltd." 393 "Harvest Tec, Inc" 394 "Capi 2 Nederland BV" 395 "GENTEC S.R.L." 396 "Beyond Measure" 397 "Sanyo-kiki Co Ltd." 398 "Hilite International" 399 "ISEKI & Co., Ltd." 400 "Livorsi Marine" 401 "Torqeedo GmbH" 402 "Simma Software, Inc." 403 "Trackwell ADS, Inc." 404 "Com Nav Marine Ltd" 405 "Wema System AS" 406 "Vecima Networks Inc." 407 "Comtech Mobile Datacom" 408 "Corvus Energy Ltd." 409 "Transfluid S.r.L." 410 "COBO S.p.A. Divisione 3B6" 411 "Hy-Drive Technologies Ltd." 412 "WebTech Wireless Inc." 413 "Datapross Nijbroek bv" 414 "Cattron Group International" 415 "Valid Manufacturing Ltd." 416 "Kubota Corporation" 417 "KZValve" 418 "Intellistick Inc" 419 "Fusion Electronics Ltd" 420 "Vermeer Corporation, ACS Group" 421 "Vertex Standard Co, Ltd" 422 "True Heading AB" 423 "BSM Wireless, Inc." 424 "Odyne LLC" 425 "Methode Electronics Inc, MDI" 426 "Egersund Marine Electronics AS" 427 "em-trak Marine Electronics Ltd" 428 "Mfg_428" 429 "Rota Engineering Ltd." 430 "Auteq Telematica S.A." 431 "Tohatsu Corporation" 432 "S&A Systems, Inc." 433 "Rowe Electronics" 434 "Stored Energy Systems" 435 "Zunhammer GmbH" 436 "Kinze Manufacturing" 437 "Digital Yacht Limited" 438 "Comar Systems Ltd" 439 "Hyundai Heavy Industries" 440 "Cummins Power Generation" 441 "PTG Reifendruckregelsysteme GmbH" 442 "Horsch Maschinen GmbH" 443 "SignalQuest, Inc." 444 "ITT Power Solutions" 445 "KAT MECHATRONIC, Electronic Product Division" 446 "CertTech, L.L.C." 447 "Great Plains Mfg." 448 "Stanadyne Corporation, Electronics Systems" 449 "Polaris Industries Inc" 450 "Dycor Technologies Ltd." 451 "Parker Hannifin Corp" 452 "WIKA Alexander Wiegand SE & Co. KG" 453 "Cooper Bussmann" 454 "NGK Spark Plug Co. Ltd" 455 "ADZ NAGANO GmbH" 456 "General Kinetics" 457 "RUSELPROM-ElectricDrive Ltd" 458 "Control Solutions, Inc." 459 "Alltek Marine Electronics Corp" 460 "San Giorgio S.E.I.N." 461 "HAWE Hydraulik SE" 462 "IHI Shibaura Machinery Corporation" 463 "PROBOTIQ" 464 "Leach International Corporation" 465 "Ashcroft Inc" 466 "Veethree Electronics and Marine LLC" 467 "Lely Industries N.V." 468 "Tyco Fire Protection Products" 469 "RA Consulting GmbH" 470 "SI-TEX Marine Electronics" 471 "Sea Cross Marine AB" 472 "Tenneco Inc." 473 "Boss Industries, Inc." 474 "Persen Technologies Inc." 475 "GME" 476 "Hummingbird Marine Electronics" 477 "OilQuick AB" 478 "OceanSat BV" 479 "Vapor Bus International" 480 "EnerDel, Inc." 481 "Chetco Digital Instruments" 482 "Tricon Electronics" 483 "Valeo" 484 "Headsight Inc." 485 "MATT automotive" 486 "Westport Innovations Inc." 487 "DSE Test Solutions A/S" 488 "The Charles Machine Works, Inc." 489 "Appareo Systems" 490 "QuikQ" 491 "Penny and Giles Ltd" 492 "Inergy Automotive Systems" 493 "Watcheye" 494 "Synerject" 495 "HOLMER Maschinenbau GmbH" 496 "W. Gessmann GmbH" 497 "SENTRON Sistemas Embarcados" 498 "Innovative Design Solutions, Inc" 499 "LCJ Capteurs" 500 "Oxbo International Corporation" 501 "Agrotronix S.A." 502 "Attwood Corporation" 503 "Naviop S.R.L." 504 "Vesper Marine" 505 "Yetter Farm Equipment" 506 "IHI STAR Machinery Corporation" 507 "Test Center ISOBUS" 508 "Transtech Innovations" 509 "MOTORTECH GmbH" 510 "Marinesoft Co. Ltd" 511 "Sulky" 512 "Inpower LLC" 513 "FarmscanAg" 514 "DISTek Integration, Inc." 515 "GINAF Trucks Nederland B.V." 516 "AVAT Automation GmbH" 517 "Noland Engineering" 518 "Transas USA Inc." 519 "Peeters Landbouwmachines b.v." 520 "Trapeze" 1850 "Teleflex" 1851 "Raymarine" 1852 "Navionics" 1853 "Japan Radio Co." 1854 "Northstar Technologies" 1855 "Furuno USA" 1856 "Trimble" 1857 "Simrad" 1858 "Litton" 1859 "Kvasar AB" 1860 "MMP" 1861 "Vector CANtech" 1862 "Sanshin" 1863 "Thomas G. Faria Co.";
VAL_ 2566847486 DrvlineRetarderOverheatIndicator 0 "Driveline Retarder Overheat Indicator is off" 1 "Driveline Retarder Overheat Indicator is on continuously" 2 "Driveline Retarder Overheat Indicator is flashing" 3 "Not available";
VAL_ 2631859966 SteerStraightAheadPosReset_3600 0 "Take no action" 1 "Reset" 2 "Reserved" 3 "Not applicable";
VAL_ 2631859966 EngBuildHoursReset_1211 0 "Do not reset" 1 "Reset" 2 "Reserved" 3 "Take no action";
VAL_ 2631859966 EngIgntCtrlMntnHoursRst_6219 0 "Do not reset" 1 "Reset" 2 "Reserved" 3 "Take no action";
VAL_ 2631859966 EngSprkPlgScndUTrackingRst_6218 0 "Do not reset" 1 "Reset" 2 "Reserved" 3 "Take no action";
VAL_ 2631859966 TripGroup2Proprietary_989 0 "Take no action" 1 "Reset" 2 "Reserved" 3 "Not applicable";
VAL_ 2631859966 TireSensorInformation_6986 0 "Take no action" 1 "Reset" 2 "Reserved" 3 "Not applicable";
VAL_ 2631859966 TireConfigInformation_6985 0 "Take No Action" 1 "Reset" 2 "Reserved" 3 "Not Applicable";
VAL_ 2631859966 BinLiftCountReset_6898 0 "Do not reset" 1 "Reset" 2 "Reserved" 3 "Take no action";
VAL_ 2631859966 TripGroup1_988 0 "Take no action" 1 "Reset" 2 "Reserved" 3 "Not applicable";
VAL_ 2566840830 RetarderLocation 0 "(Primary)        Engine Compression Release Brake or Engine Compression Release Brake Combined with Engine Exhaust Brake" 1 "(Primary)         Engine Exhaust Brake" 2 "(Primary)         Transmission Input" 3 "(Secondary)    Transmission Output" 4 "(Secondary)    Driveline" 5 "Trailer" 14 "Other" 15 "Not available";
VAL_ 2566840830 RetarderType 0 "Electric/Magnetic" 1 "Hydraulic" 2 "Cooled Friction" 3 "Compression Release" 4 "Exhaust" 14 "Other" 15 "Not available";
VAL_ 2566844670 OprtrEngPTOGvrnrMmrySelectSwitch 0 "PTO set speed memory 1 selected" 1 "PTO set speed memory 2 selected" 2 "error" 3 "not available";
VAL_ 2566844670 EngRmtPTOGvrnrVrblSpedCtrlSwitch 0 "Off" 1 "On" 2 "Error" 3 "Not available";
VAL_ 2566844670 EngRmtPTOGvrnrPrprgrmmdSpdCtrlSw 0 "Off" 1 "On" 2 "Error" 3 "Not available";
VAL_ 2566844670 EngPTOGvrnrCast_DecelerateSwitch 0 "Off" 1 "On" 2 "Error" 3 "Not available";
VAL_ 2566844670 EngPTOGovernorSetSwitch 0 "Off" 1 "On" 2 "Error" 3 "Not available";
VAL_ 2566844670 EngPTOGovernorResumeSwitch 0 "Off" 1 "On" 2 "Error" 3 "Not available";
VAL_ 2566844670 EngPTOGovernorEnableSwitch 0 "Off" 1 "On" 2 "Error" 3 "Not available";
VAL_ 2566844670 EngPTOGovernorAccelerateSwitch 0 "Off" 1 "On" 2 "Error" 3 "Not available";
VAL_ 2566844670 RmtPTOGvrnrPrprgrmmdSpdCtrlSwtch 0 "Off" 1 "On" 2 "Error" 3 "Not Available";
VAL_ 2566844670 AuxInputIgnoreSwitch 0 "Off" 1 "On" 2 "Error" 3 "Not Available";
VAL_ 2566770174 RearWasherFunction 0 "Off" 1 "Low" 2 "Medium" 3 "High" 7 "Not available";
VAL_ 2566770174 FrontOperatorWasherSwitch 0 "Off" 1 "Low" 2 "Medium" 3 "High" 7 "Not available";
VAL_ 2566770174 FrontNonoperatorWasherSwitch 0 "Off" 1 "Low" 2 "Medium" 3 "High" 7 "Not available";
VAL_ 2566770174 RearWiperSwitch 0 "Off" 1 "Low" 2 "Medium" 3 "High" 4 "Delayed 1" 5 "Delayed 2" 6 "Mist" 15 "Not available";
VAL_ 2566770174 FrontOperatorWiperSwitch 0 "Off" 1 "Low" 2 "Medium" 3 "High" 4 "Delayed 1" 5 "Delayed 2" 6 "Mist" 15 "Not available";
VAL_ 2566770174 FrontNonoperatorWiperSwitch 0 "Off" 1 "Low" 2 "Medium" 3 "High" 4 "Delayed 1" 5 "Delayed 2" 6 "Mist" 15 "Not available";
VAL_ 2566769662 EngTorqueCurveSelectionCmd 0 "Indicates that this parameter is not presently requesting a different torque curve be used" 1 "Indicates that Torque Curve 1 is selected" 2 "Indicates that Torque Curve 2 is selected" 14 "SAE reserved" 15 "Not supported";
VAL_ 2566769662 EngAltDroopAuxInputSelect 0 "- Normal Droop Setting is selected" 1 "thru 1101" 14 "-  Error condition" 15 "-  Not available";
VAL_ 2566769662 EngAltDroopRemoteAccelSelect 0 "- Normal Droop Setting is selected" 1 "thru 1101" 14 "-  Error condition" 15 "-  Not available";
VAL_ 2566769662 EngAltDroopAccel2Select 0 "- Normal Droop Setting is selected" 1 "thru 1101" 14 "-  Error condition" 15 "- Not available";
VAL_ 2566769662 EngAltDroopAccel1Select 0 "- Normal Droop Setting is selected" 1 "thru 1101" 14 "-  Error condition" 15 "- Not available";
VAL_ 2566769662 EngAltRatingSelect 0 "indicates that Maximum Power Fueling is selected" 1 "indicates that the Alternate Power Fueling 1 is selected" 2 "indicates that the Alternate Power Fueling 2 is selected" 3 "indicates that the Alternate Power Fueling 3 is selected" 254 "Error condition." 255 "Not available";
VAL_ 2566769662 EngAltLowIdleSwitch 0 "Default low idle point is selected" 1 "Alternate low idle point is selected" 2 "Error" 3 "Not available or Unused";
VAL_ 2566769662 EngSynchronizationSwitch 0 "Functionality is disabled" 1 "Functionality is enabled" 2 "Error" 3 "Not available or Unused";
VAL_ 2566769662 EngAuxGovernorSwitch 0 "Auxiliary Governor is disabled" 1 "Auxiliary Governor is enabled" 2 "Error condition" 3 "Not available";
VAL_ 2566768638 EngTorqueCurveSelection 0 "Indicates that the engine is using a torque that is not presently selected by SPN 6796" 1 "Indicates that Torque Curve 1 is selected" 2 "Indicates that Torque Curve 2 is selected" 14 "Error" 15 "Not supported";
VAL_ 2566768638 EngAltDroopAuxInputSelectState 0 "- Control state is Normal Droop Setting" 1 "thru 1101" 14 "-  SAE reserved" 15 "-  Not available";
VAL_ 2566768638 EngAltDropRemoteAccelSelectState 0 "- Control state is Normal Droop Setting" 1 "thru 1101" 14 "-  SAE reserved" 15 "-  Not available";
VAL_ 2566768638 EngAltDroopAccel2SelectState 0 "- Control's state is Normal Droop Setting" 1 "thru 1101" 14 "-  SAE reserved" 15 "-  Not available";
VAL_ 2566768638 EngAltDroopAccel1SelectState 0 "- Control state is Normal Droop Setting" 1 "thru 1101" 14 "-  SAE reserved" 15 "-  Not available";
VAL_ 2566768638 EngAltRatingSelectState 0 "Control state is Maximum Power Fueling" 1 "Control state is Alternate Power Fueling 1 " 2 "Control state is Alternate Power Fueling 2 " 3 "Control state is Alternate Power Fueling 3" 254 "SAE reserved" 255 "Not available";
VAL_ 2566768638 EngAltLowIdleSelectState 0 "Normal idle state" 1 "Alternate idle state" 2 "SAE reserved" 3 "not available";
VAL_ 2566768638 EngMultiUnitSyncState 0 "Control State is Functionality disabled" 1 "Control State is Functionality enabled" 2 "SAE reserved" 3 "Not available";
VAL_ 2566768638 EngAuxGovernorState 0 "Control State is Auxiliary Governor disabled" 1 "Control State is Auxiliary Governor enabled" 2 "SAE reserved" 3 "Not available";
VAL_ 2365443326 HighLowBeamSwitch 0 "Low Beam Selected" 1 "High Beam Selected" 2 "Error" 3 "Not available";
VAL_ 2365443326 HazardLightSwitch 0 "Hazard Lamps to be Off" 1 "Hazard Lamps to be Flashing" 2 "Error" 3 "Not available";
VAL_ 2365443326 TurnSignalSwitch 0 "No Turn being signaled" 1 "Left Turn to be Flashing" 2 "Right turn to be Flashing" 14 "Error" 15 "Not available";
VAL_ 2365443326 MainLightSwitch 0 "Off" 1 "Park On" 2 "Headlight On" 3 "Headlight and Park On" 8 "Delayed Off" 14 "Error" 15 "Not available";
VAL_ 2365443326 WorkLightSwitch 0 "Off" 1 "Work Light Combination #1 On" 2 "Work Light Combination #2 On" 3 "Work Light Combination #3 On" 4 "Work Light Combination #4 On" 14 "Error" 15 "Not available";
VAL_ 2566802686 BlackOutWorkLampSelect 0 "Off" 1 "On" 2 "Reserved" 3 "Not Supported";
VAL_ 2566802686 NightVisionIlluminatorSelect 0 "Off" 1 "On" 2 "Reserved" 3 "Not Supported";
VAL_ 2566802686 BlackOutBrake_StopLampSelect 0 "Off" 1 "On" 2 "Reserved" 3 "Not Supported";
VAL_ 2566802686 ConvoyDrivingLampSelect 0 "Off" 1 "On" 2 "Reserved" 3 "Not Supported";
VAL_ 2566802686 ConvoyLampSelect 0 "Off" 1 "On" 2 "Reserved" 3 "Not Supported";
VAL_ 2566802686 FrontBlackOutMarkerLampSelect 0 "Off" 1 "On" 2 "Reserved" 3 "Not Supported";
VAL_ 2566802686 RearBlackOutMarkerSelect 0 "Off" 1 "On" 2 "Reserved" 3 "Not Supported";
VAL_ 2566774014 SlowVesselModeStatus 0 "Slow vessel mode is OFF." 1 "Slow vessel mode is ACTIVE." 2 "Reserved" 3 "Take no action";
VAL_ 2566774014 TrollingModeStatus 0 "Trolling mode is OFF." 1 "Trolling mode is ACTIVE." 2 "Reserved" 3 "Take no action";
VAL_ 2566774014 EngThrttlSynchrnzationModeStatus 0 "Not Synchronized" 1 "Synchronized Center" 2 "Synchronized Port" 3 "Synchronized Starboard" 4 "Synchronized Master" 15 "Take no action";
VAL_ 2432595710 DisplayDeadbands 0 "- Narrow = +/- 4.5mm" 1 "- Standard = +/- 12mm" 2 "- Wide = +/- 24mm" 15 "Not Available";
VAL_ 2432595710 LEDPatternCtrl 0 "- 5 Channel" 1 "- Offset" 2 "- 7 Channel" 15 "Not Available";
VAL_ 2432595710 LEDDisplayDeadbandCtrl 0 "+/- 4.5 mm " 1 "+/- 12 mm  " 2 "+/- 24 mm  " 3 "+/- 5  mm   " 4 "+/- 1 mm    " 15 "Not Available or Not applicable";
VAL_ 2432595710 LEDDisplayModeCtrl 0 "Center On-Grade Display Mode 1" 1 "Offset On-Grade Display Mode " 2 "Center On-Grade Display Mode 2" 15 "Not Available or Not Applicable";
VAL_ 2432595710 LEDDisplayData1 2 "High Coarse LED on" 4 "High Fine LED on" 8 "On-grade LED on" 16 "Low Fine LED on" 32 "Low Coarse LED on" 128 "Low Coarse" 129 "Low Medium/Coarse" 130 "Low Medium" 131 "Low Medium/Fine" 132 "Low Fine" 144 "On Grade" 145 "High Fine" 146 "High Medium/Fine" 147 "High Medium" 148 "High Medium/Coarse" 149 "High Coarse" 159 "No data" 254 "Error" 255 "Not Available";
VAL_ 2365486590 LaserReceiverType 0 "Reserved " 1 "Linear Laser Receiver" 2 "1 Meter Survey Receiver" 3 "2 Meter Survey Receiver" 4 "2.5 Meter Survey Receiver";
VAL_ 2365485566 LaserTracerInformation 1 "Laser power is on" 2 "Laser is ready" 4 "Valid target" 8 "Previous pass" 16 "Stringline" 32 "Curb";
VAL_ 2365485566 LEDDisplayData2 1 "On-grade “A” LED on" 2 "On-grade “B” LED on" 4 "On-grade “C” LED on" 8 "Up LED on" 16 "Down LED on" 32 "Left LED on" 64 "Right LED on" 128 "Low Coarse" 129 "Low Medium/Coarse" 130 "Low Medium" 131 "Low Medium/Fine" 132 "Low Fine" 144 "On Grade" 145 "High Fine" 146 "High Medium/Fine" 147 "High Medium" 148 "High Medium/Coarse" 149 "High Coarse" 159 "No data" 254 "Error" 255 "Not Available";
VAL_ 2364542462 SetElvtnSnsr2RefElvtn_5406 0 "Do not Set Reference Elevation" 1 "Set Reference Elevation" 2 "Reserved" 3 "Don't Care / Take No Action";
VAL_ 2364542462 SetElvtnSnsr1RefElvtn_5405 0 "Do not Set Reference Elevation" 1 "Set Reference Elevation" 2 "Reserved" 3 "Don't Care / Take No Action";
VAL_ 2364542462 SdShiftDesBladeOfsOprtrCtrl_3339 0 "No Operator Control Request" 1 "Momentary Operator Control Request" 2 "Manual Operator Control Request" 3 "Automatic Operator Control Request" 14 "Error Indicator" 15 "Not Installed";
VAL_ 2364542462 SdShiftBladeCtlModeOprtrCtl_3338 0 "No Operator Control Request" 1 "Increment Operator Control Request" 2 "Decrement Operator Control Request" 14 "Error Indicator" 15 "Not installed";
VAL_ 2364542462 RiDesBladeOfsOperatorCtl_3337 0 "No Operator Control Request" 1 "Increment Operator Control Request" 2 "Decrement Operator Control Request" 14 "Error Indicator" 15 "Not installed";
VAL_ 2364542462 LeDesBladeOfsOperatorCtl_3336 0 "No Operator Control Request" 1 "Increment Operator Control Request" 2 "Decrement Operator Control Request" 14 "Error Indicator" 15 "Not installed";
VAL_ 2364542462 RiBladeCtlModeOperatorCtl_3335 0 "No Change" 1 "Momentary Operator Control Request" 2 "Manual Operator Control Request" 3 "Automatic Operator Control Request" 14 "Error Indicator" 15 "Not Installed";
VAL_ 2364542462 LeBladeCtlModeOperatorCtl_3334 0 "No Change" 1 "Momentary Operator Control Request" 2 "Manual Operator Control Request" 3 "Automatic Operator Control Request" 14 "Error Indicator" 15 "Not Installed";
VAL_ 2364542462 BladeAutoModeCmd_3158 0 "Auto Allowed" 1 "Activity Allows Auto" 2 "Suspend Auto" 3 "Service Mode" 4 "Auto Not Allowed" 14 "Error Indicator" 15 "Not Supported";
VAL_ 2364542462 DesiredGradeOffsetSwitch_3157 0 "No button pressed" 1 "Increment button pressed" 2 "Decrement button pressed" 14 "Error Indicator" 15 "Not installed";
VAL_ 2364542462 BladeCtrlModeSwitch_3156 0 "No button pressed" 1 "Mode button pressed" 2 "Manual button pressed" 3 "Automatic button pressed" 14 "Error Indicator" 15 "Not Installed";
VAL_ 2633883646 FrontWheelDriveActuatorStatus 0 "Front Wheel Drive Actuator not engaged" 1 "Front Wheel Drive Actuator engaged" 2 "Error" 3 "Not Available";
VAL_ 2633880062 FMSstandardRequestsSupported 0 "On request mode is not supported" 1 "On request mode is supported" 2 "Reserved" 3 "Don't care";
VAL_ 2633880062 FMSstandardDiagnosticsSupported 0 "Diagnostics Is Not Supported" 1 "Diagnostics Is Supported" 2 "Reserved" 3 "Don't care";
VAL_ 2566806526 DrverAlertnessWarningSystemState 0 "System installed but disabled" 1 "Initializing" 2 "System temporarily not available" 3 "System available" 4 "System monitoring driver behavior" 7 "Not Available / Not Installed";
VAL_ 2566806526 LnDpartureIndicationEnableStatus 0 "Lane Departure indication disabled" 1 "Lane Departure Indication enabled " 2 "Reserved" 3 "Not Used";
VAL_ 2566806526 LaneTrackingStatusLeftSide 0 "Not Tracking Left side" 1 "Tracking Left side" 2 "Reserved" 3 "Don't care/Take no action";
VAL_ 2566806526 LaneTrackingStatusRightSide 0 "Not Tracking Right side" 1 "Tracking Right side" 2 "Reserved" 3 "Don't Care/take no action";
VAL_ 2431649790 LaneDepartureImminentLeSide_1700 0 "Not imminent" 1 "Imminent" 2 "Reserved" 3 "Not used";
VAL_ 2431649790 LaneDepartureImminentRiSide_1701 0 "Not imminent" 1 "Imminent" 2 "Reserved" 3 "Not Used";
VAL_ 2431649790 LaneDepartureRight_3566 0 "Middle of the vehicle does not depart the lane to the right side" 1 "Middle of the vehicle departs the lane to the right side" 2 "Reserved" 3 "Take no action";
VAL_ 2431649790 LaneDepartureLeft_3565 0 "Middle of the vehicle does not depart the lane to the left side" 1 "Middle of the vehicle departs the lane to the left side" 2 "Reserved" 3 "Take no action";
VAL_ 2431649790 DriverAlertnessWarning_7473 0 "No distracted driving condition detected" 1 "Level 1" 2 "Level 2" 3 "Level 3" 7 "Not Available";
VAL_ 2633929214 EngFuelLeakage2 0 "no leakage detected" 1 "leakage detected" 2 "Error" 3 "Not available";
VAL_ 2633929214 EngFuelLeakage1 0 "no leakage detected" 1 "leakage detected" 2 "Error" 3 "Not available";
VAL_ 2566831614 FanDriveState 0 "Fan off" 1 "Engine system-General" 2 "Excessive engine air temperature" 3 "Excessive engine oil temperature" 4 "Excessive engine coolant temperature" 5 "Excessive transmission oil temperature" 6 "Excessive hydraulic oil temperature" 7 "Default Operation" 8 "Reverse Operation" 9 "Manual control" 10 "Transmission retarder" 11 "A/C system" 12 "Timer" 13 "Engine brake" 14 "Other" 15 "Not available";
VAL_ 2566820094 EngTorqueLimitFeature 0 "Reserved" 1 "Highest torque rating" 2 "First torque rating" 3 "Previous torque rating" 4 "Current torque rating" 7 "Not available";
VAL_ 2566820094 TorqueLimitingFeatureStatus 0 "Disabled" 1 "Enabled" 2 "Error" 3 "Not available";
VAL_ 2566802174 TransAutoNeutralSt 0 "No request received,  conditions are such that an Auto-Neutral request would be honored." 1 "No request received,  conditions are such that an Auto-Neutral request would NOT be honored." 2 "Auto-Neutral request received,  shift to Auto-Neutral state is pending." 3 "Auto-Neutral request received,  shift to Auto-Neutral state has been achieved." 4 "Auto-Neutral request received,  shift to Auto-Neutral state is inhibited." 5 "Reserved" 6 "Error" 7 "Not Available";
VAL_ 2566802174 TransWarningIndicator 0 "Transmission Warning Indicator is off" 1 "Transmission Warning Indicator is on continuously" 2 "Transmission Warning Indicator is flashing" 3 "Not available";
VAL_ 2566802174 TrnsRverseGearShiftInhibitStatus 0 "Reverse gear shifts are currently allowed" 1 "Reverse gear shifts are currently inhibited" 2 "Error" 3 "Not Available";
VAL_ 2566802174 TransMode8Indicator 0 "Transmission Mode 8 not active" 1 "Transmission Mode 8 active" 2 "Error" 3 "Not available";
VAL_ 2566802174 TransMode7Indicator 0 "Transmission Mode 7 not active" 1 "Transmission Mode 7 active" 2 "Error" 3 "Not available";
VAL_ 2566802174 TransMode6Indicator 0 "Transmission Mode 6 not active" 1 "Transmission Mode 6 active" 2 "Error" 3 "Not available";
VAL_ 2566802174 TransMode5Indicator 0 "Transmission Mode 5 not active" 1 "Transmission Mode 5 active" 2 "Error" 3 "Not available";
VAL_ 2566802174 TransMode1Indicator 0 "Transmission Mode 1 not active" 1 "Transmission Mode 1 Active" 2 "Error" 3 "Not available";
VAL_ 2566802174 TransMode2Indicator 0 "Transmission Mode 2 not active" 1 "Transmission Mode 2 Active" 2 "Error" 3 "Not available";
VAL_ 2566802174 TransMode3Indicator 0 "Transmission Mode 3 not active" 1 "Transmission Mode 3 Active" 2 "Error" 3 "Not available";
VAL_ 2566802174 TransMode4Indicator 0 "Transmission Mode 4 not active" 1 "Transmission Mode 4 Active" 2 "Error" 3 "Not available";
VAL_ 2566802174 TransShiftInhibitIndicator 0 "Inactive" 1 "Active, on continuously)" 2 "Active, flashing)" 3 "Take no action";
VAL_ 2566802174 TransEngCrankEnable 0 "Cranking disabled" 1 "Cranking enabled" 2 "Error" 3 "Not available";
VAL_ 2566802174 ActiveShiftConsoleIndicator 0 "Primary shift console is active" 1 "Secondary shift console is active" 2 "Reserved" 3 "Not available";
VAL_ 2566802174 TransReadyForBrakeRelease 0 "Transmission Not Ready for Brake Release" 1 "Transmission Ready for Brake Release" 2 "Error" 3 "Not available";
VAL_ 2566802174 TrnsRqstedRangeDisplayFlashState 0 "Inactive" 1 "Active" 2 "Reserved" 3 "Take no action";
VAL_ 2566802174 TrnsRqstedRangeDisplayBlankState 0 "Inactive" 1 "Active" 2 "Reserved" 3 "Take no action";
VAL_ 2566802174 TransServiceIndicator 0 "Transmission Service Indicator is off" 1 "Transmission Service Indicator is on continuously" 2 "Transmission Service Indicator is flashing" 3 "Not available";
VAL_ 2566802174 TransAirSupplyPressIndicator 0 "Normal Pressure Range" 1 "Low pressure" 2 "Very low pressure" 3 "No pressure" 4 "Over pressure" 5 "Not defined" 6 "Error indicator" 7 "Not available";
VAL_ 2566802174 TransMode10Indicator 0 "Transmission Mode 10 not active" 1 "Transmission Mode 10 active" 2 "Error indicator" 3 "Not available";
VAL_ 2566802174 TransMode9Indicator 0 "Transmission Mode 9 not active" 1 "Transmission Mode 9 active" 2 "Error indicator" 3 "Not available";
VAL_ 2633942014 TransForwardDirectionSwitch 0 "Off" 1 "On" 2 "Error" 3 "Not available";
VAL_ 2633942014 TransNeutralSwitch 0 "Off" 1 "On" 2 "Error" 3 "Not available";
VAL_ 2633942014 TransReverseDirectionSwitch 0 "Off" 1 "On" 2 "Error" 3 "Not available";
VAL_ 2633942014 TransLowRangeSenseSwitch 0 "Off" 1 "On" 2 "Error" 3 "Not available";
VAL_ 2633942014 TransHighRangeSenseSwitch 0 "Off" 1 "On" 2 "Error" 3 "Not available";
